VERSION ""

NS_ :

BS_:

BU_: TPMS iBooster_ADAS IM ESC_ADAS EPS1_ADAS CGW_ADAS VCU_ADAS FCM

BO_ 912 IM_02_Alarm_Event: 16 IM
 SG_ ALIVE_IM_02 : 23|8@0+ (1,0) [0|255] ""  VCU_ADAS,CGW_ADAS
 SG_ CRC_IM_02 : 7|16@0+ (1,0) [0|65535] ""  VCU_ADAS,CGW_ADAS
 SG_ IM_Driver_Fatigue_Event : 98|3@0+ (1,0) [0|7] ""  VCU_ADAS,CGW_ADAS
 SG_ IM_Driver_Distraction_Event : 111|3@0+ (1,0) [0|7] ""  VCU_ADAS,CGW_ADAS

BO_ 913 IM_03_Status: 20 IM
 SG_ ALIVE_IM_03 : 23|8@0+ (1,0) [0|255] ""  VCU_ADAS,CGW_ADAS
 SG_ CRC_IM_03 : 7|16@0+ (1,0) [0|65535] ""  VCU_ADAS,CGW_ADAS
 SG_ IM_Calibrate_Result : 103|1@0+ (1,0) [0|1] ""  VCU_ADAS,CGW_ADAS
 SG_ IM_Camera_Lens_Cover : 102|1@0+ (1,0) [0|1] ""  VCU_ADAS,CGW_ADAS
 SG_ IM_Driver_Eye_Invisible : 101|1@0+ (1,0) [0|1] ""  VCU_ADAS,CGW_ADAS
 SG_ IM_Driver_Face_Invisible : 111|11@0+ (1,0) [0|1] ""  VCU_ADAS,CGW_ADAS
 SG_ IM_Driver_Distraction : 122|3@0+ (1,0) [0|7] ""  VCU_ADAS,CGW_ADAS
 SG_ IM_Driver_Fatigue : 116|2@0+ (1,0) [0|3] ""  VCU_ADAS,CGW_ADAS
 SG_ IM_DMS_Status : 98|3@0+ (1,0) [0|7] ""  VCU_ADAS,CGW_ADAS

BO_ 1986 IDS_iBooster_Resp: 8 iBooster_ADAS
 SG_ IDS_iBooster_Resp : 7|64@0+ (1,0) [0|1.84467440737096E+019] ""  CGW_ADAS

BO_ 1982 IDS_ESC_Resp: 8 ESC_ADAS
 SG_ IDS_ESC_Resp : 7|64@0+ (1,0) [0|1.84467440737096E+019] ""  CGW_ADAS

BO_ 1973 IDS_FCM_Resp: 8 FCM
 SG_ IDS_FCM_Resp : 7|64@0+ (1,0) [0|1.84467440737096E+019] ""  CGW_ADAS

BO_ 1906 IDS_iBooster_Req: 8 CGW_ADAS
 SG_ IDS_iBooster_Req : 7|64@0+ (1,0) [0|1.84467440737096E+019] ""  iBooster_ADAS

BO_ 1902 IDS_ESC_Req: 8 CGW_ADAS
 SG_ IDS_ESC_Req : 7|64@0+ (1,0) [0|1.84467440737096E+019] ""  ESC_ADAS

BO_ 1893 IDS_FCM_Req: 8 CGW_ADAS
 SG_ IDS_FCM_Req : 7|64@0+ (1,0) [0|1.84467440737096E+019] ""  FCM

BO_ 801 HU_02: 16 CGW_ADAS
 SG_ HU_DigitSpeed : 111|9@0+ (1,0) [0|260] "km/h"  FCM,VCU_ADAS,EPS1_ADAS
 SG_ ALIVE_HU_02 : 23|8@0+ (1,0) [0|255] ""  FCM,VCU_ADAS,EPS1_ADAS
 SG_ CRC_HU_02 : 7|16@0+ (1,0) [0|65535] ""  FCM,VCU_ADAS,EPS1_ADAS
 SG_ HU_ST_TILT_Setting : 102|1@0+ (1,0) [0|1] ""  FCM,VCU_ADAS,EPS1_ADAS
 SG_ HU_ST_USIS_Setting : 103|1@0+ (1,0) [0|1] ""  FCM,VCU_ADAS,EPS1_ADAS

BO_ 1791 Diag_FuncReq_All_ECUs: 8 CGW_ADAS
 SG_ Diag_FuncReq_All_ECUs : 7|64@0+ (1,0) [0|1.84467440737096E+019] "N/A"  TPMS,IM,iBooster_ADAS,FCM,ESC_ADAS,EPS1_ADAS

BO_ 1775 Diag_FuncReq_All_CAN: 8 CGW_ADAS
 SG_ Diag_FuncReq_All_CAN : 7|64@0+ (1,0) [0|1.84467440737096E+019] "N/A"  TPMS,IM,iBooster_ADAS,FCM,ESC_ADAS,EPS1_ADAS

BO_ 789 TBOX_01_OTA: 16 CGW_ADAS
 SG_ TBOX_OTA_WakeupStatus : 99|2@0+ (1,0) [0|0] ""  VCU_ADAS,TPMS,IM,iBooster_ADAS,FCM,ESC_ADAS,EPS1_ADAS
 SG_ ALIVE_TBOX_01 : 23|8@0+ (1,0) [0|255] ""  VCU_ADAS,EPS1_ADAS,IM,FCM,ESC_ADAS,iBooster_ADAS,TPMS
 SG_ CRC_TBOX_01 : 7|16@0+ (1,0) [0|65535] ""  VCU_ADAS,EPS1_ADAS,IM,FCM,ESC_ADAS,iBooster_ADAS,TPMS
 SG_ TBOX_OTA_Status : 103|4@0+ (1,0) [0|15] ""  VCU_ADAS,EPS1_ADAS,IM,FCM,ESC_ADAS,iBooster_ADAS,TPMS

BO_ 901 VCU_13_VSMS: 32 VCU_ADAS
 SG_ VCU_TowModRq : 115|1@0+ (1,0) [0|1] ""  IM,FCM,ESC_ADAS
 SG_ VCU_TowModSts : 116|1@0+ (1,0) [0|1] ""  IM,FCM,ESC_ADAS
 SG_ VCU_Dur_Lt_h : 207|14@0+ (1,0) [0|16383] "h"  IM,FCM,ESC_ADAS
 SG_ VCU_Dur_Trip_h : 199|8@0+ (1,0) [0|255] "h"  IM,FCM,ESC_ADAS
 SG_ VCU_Dur_Act_h : 99|4@0+ (1,0) [0|15] "h"  IM,FCM,ESC_ADAS
 SG_ VCU_Dur_Lt_min : 191|6@0+ (1,0) [0|59] ""  IM,FCM,ESC_ADAS
 SG_ VCU_Dur_Trip_min : 183|6@0+ (1,0) [0|59] "min"  IM,FCM,ESC_ADAS
 SG_ VCU_Dur_Act_min : 175|6@0+ (1,0) [0|59] "min"  IM,FCM,ESC_ADAS
 SG_ VCU_AvgDrivRngRate : 159|14@0+ (0.1,0) [0|1000] "km/h"  IM,FCM,ESC_ADAS
 SG_ ALIVE_VCU_13 : 23|8@0+ (1,0) [0|255] ""  IM,FCM,ESC_ADAS
 SG_ CRC_VCU_13 : 7|16@0+ (1,0) [0|65535] ""  IM,FCM,ESC_ADAS
 SG_ VCU_ProdRollrModSts : 101|1@0+ (1,0) [0|1] ""  FCM,IM,ESC_ADAS
 SG_ VCU_DynoModSts : 102|1@0+ (1,0) [0|1] ""  IM,ESC_ADAS,FCM
 SG_ VCU_DynoModActvtnEnblSts : 103|1@0+ (1,0) [0|1] ""  IM,ESC_ADAS,FCM
 SG_ VCU_AvgSpd_Lt : 143|11@0+ (0.1,0) [0|160] "km/h"  IM,FCM,ESC_ADAS
 SG_ VCU_AvgSpd_Trip : 127|11@0+ (0.1,0) [0|160] "km/h"  IM,FCM,ESC_ADAS
 SG_ VCU_AvgSpd_Act : 111|11@0+ (0.1,0) [0|160] "km/h"  IM,FCM,ESC_ADAS

BO_ 1296 NM_EPS: 8 EPS1_ADAS
 SG_ usrData1_EPS_Bit7_ECUSPEC_AWAKE : 31|1@0+ (1,0) [0|1] ""  FCM,IM,VCU_ADAS,ESC_ADAS,iBooster_ADAS,TPMS,CGW_ADAS
 SG_ usrData1_EPS_Bit6_DIAGN_AWAKE : 30|1@0+ (1,0) [0|1] ""  FCM,IM,VCU_ADAS,ESC_ADAS,iBooster_ADAS,TPMS,CGW_ADAS
 SG_ usrData1_EPS_Bit5_IGNITION_AWAKE : 29|1@0+ (1,0) [0|1] ""  FCM,IM,VCU_ADAS,ESC_ADAS,iBooster_ADAS,TPMS,CGW_ADAS
 SG_ usrData1_EPS_Bit4_NETWORK_AWAKE : 28|1@0+ (1,0) [0|1] ""  FCM,IM,VCU_ADAS,ESC_ADAS,iBooster_ADAS,TPMS,CGW_ADAS
 SG_ usrData1_EPS_Bit3_ECUSPEC_WAKEUP : 27|1@0+ (1,0) [0|1] ""  FCM,IM,VCU_ADAS,ESC_ADAS,iBooster_ADAS,TPMS,CGW_ADAS
 SG_ usrData1_EPS_Bit2_NETWORK_WAKEUP : 26|1@0+ (1,0) [0|1] ""  FCM,IM,VCU_ADAS,ESC_ADAS,iBooster_ADAS,TPMS,CGW_ADAS
 SG_ usrData1_EPS_Bit1_RESET_WAKEUP : 25|1@0+ (1,0) [0|1] ""  FCM,IM,VCU_ADAS,ESC_ADAS,iBooster_ADAS,TPMS,CGW_ADAS
 SG_ CtrlBitVector_EPS_Bit7_Res : 15|1@0+ (1,0) [0|1] ""  FCM,IM,VCU_ADAS,ESC_ADAS,iBooster_ADAS,TPMS,CGW_ADAS
 SG_ CtrlBitVector_EPS_Bit6_PNI : 14|1@0+ (1,0) [0|1] ""  FCM,IM,VCU_ADAS,ESC_ADAS,iBooster_ADAS,TPMS,CGW_ADAS
 SG_ CtrlBitVector_EPS_Bit5_Res : 13|1@0+ (1,0) [0|1] ""  FCM,IM,VCU_ADAS,ESC_ADAS,iBooster_ADAS,TPMS,CGW_ADAS
 SG_ CtrlBitVector_EPS_Bit4_ActWake : 12|1@0+ (1,0) [0|1] ""  FCM,IM,VCU_ADAS,ESC_ADAS,iBooster_ADAS,TPMS,CGW_ADAS
 SG_ CtrlBitVector_EPS_Bit3_NMCoord : 11|1@0+ (1,0) [0|1] ""  FCM,IM,VCU_ADAS,ESC_ADAS,iBooster_ADAS,TPMS,CGW_ADAS
 SG_ CtrlBitVector_EPS_Bit2_Res : 10|1@0+ (1,0) [0|1] ""  FCM,IM,VCU_ADAS,ESC_ADAS,iBooster_ADAS,TPMS,CGW_ADAS
 SG_ CtrlBitVector_EPS_Bit1_Res : 9|1@0+ (1,0) [0|1] ""  FCM,IM,VCU_ADAS,ESC_ADAS,iBooster_ADAS,TPMS,CGW_ADAS
 SG_ usrData1_EPS_Bit0_IGN_WAKEUP : 24|1@0+ (1,0) [0|1] ""  FCM,IM,VCU_ADAS,ESC_ADAS,iBooster_ADAS,TPMS,CGW_ADAS
 SG_ usrData0_EPS : 23|8@0+ (1,0) [0|255] ""  FCM,IM,VCU_ADAS,ESC_ADAS,iBooster_ADAS,TPMS,CGW_ADAS
 SG_ srcNodeID_EPS : 7|8@0+ (1,0) [0|127] ""  FCM,IM,VCU_ADAS,ESC_ADAS,iBooster_ADAS,TPMS,CGW_ADAS
 SG_ CtrlBitVector_EPS_Bit0_RMR : 8|1@0+ (1,0) [0|1] ""  FCM,IM,VCU_ADAS,ESC_ADAS,iBooster_ADAS,TPMS,CGW_ADAS
 SG_ usrData2_EPS : 39|8@0+ (1,0) [0|255] ""  FCM,IM,VCU_ADAS,ESC_ADAS,iBooster_ADAS,TPMS,CGW_ADAS
 SG_ usrData4_EPS_PN_Info1 : 55|8@0+ (1,0) [0|255] ""  FCM,IM,VCU_ADAS,ESC_ADAS,iBooster_ADAS,TPMS,CGW_ADAS
 SG_ usrData5_EPS_PN_Info2 : 63|8@0+ (1,0) [0|255] ""  FCM,IM,VCU_ADAS,ESC_ADAS,iBooster_ADAS,TPMS,CGW_ADAS
 SG_ usrData3_EPS : 47|8@0+ (1,0) [0|255] ""  FCM,IM,VCU_ADAS,ESC_ADAS,iBooster_ADAS,TPMS,CGW_ADAS

BO_ 1295 NM_ESC: 8 ESC_ADAS
 SG_ usrData1_ESC_Bit7_ECUSPEC_AWAKE : 31|1@0+ (1,0) [0|1] ""  CGW_ADAS,VCU_ADAS,EPS1_ADAS,FCM,IM,iBooster_ADAS,TPMS
 SG_ usrData1_ESC_Bit6_DIAGN_AWAKE : 30|1@0+ (1,0) [0|1] ""  CGW_ADAS,VCU_ADAS,EPS1_ADAS,FCM,IM,iBooster_ADAS,TPMS
 SG_ usrData1_ESC_Bit5_IGNITION_AWAKE : 29|1@0+ (1,0) [0|1] ""  CGW_ADAS,VCU_ADAS,EPS1_ADAS,FCM,IM,iBooster_ADAS,TPMS
 SG_ usrData1_ESC_Bit4_NETWORK_AWAKE : 28|1@0+ (1,0) [0|1] ""  CGW_ADAS,VCU_ADAS,EPS1_ADAS,FCM,IM,iBooster_ADAS,TPMS
 SG_ usrData1_ESC_Bit3_ECUSPEC_WAKEUP : 27|1@0+ (1,0) [0|1] ""  CGW_ADAS,VCU_ADAS,EPS1_ADAS,FCM,IM,iBooster_ADAS,TPMS
 SG_ usrData1_ESC_Bit2_NETWORK_WAKEUP : 26|1@0+ (1,0) [0|1] ""  CGW_ADAS,VCU_ADAS,EPS1_ADAS,FCM,IM,iBooster_ADAS,TPMS
 SG_ usrData1_ESC_Bit1_RESET_WAKEUP : 25|1@0+ (1,0) [0|1] ""  CGW_ADAS,VCU_ADAS,EPS1_ADAS,FCM,IM,iBooster_ADAS,TPMS
 SG_ CtrlBitVector_ESC_Bit7_Res : 15|1@0+ (1,0) [0|1] ""  CGW_ADAS,VCU_ADAS,EPS1_ADAS,FCM,IM,iBooster_ADAS,TPMS
 SG_ CtrlBitVector_ESC_Bit6_PNI : 14|1@0+ (1,0) [0|1] ""  CGW_ADAS,VCU_ADAS,EPS1_ADAS,FCM,IM,iBooster_ADAS,TPMS
 SG_ CtrlBitVector_ESC_Bit5_Res : 13|1@0+ (1,0) [0|1] ""  CGW_ADAS,VCU_ADAS,EPS1_ADAS,FCM,IM,iBooster_ADAS,TPMS
 SG_ CtrlBitVector_ESC_Bit4_ActWake : 12|1@0+ (1,0) [0|1] ""  CGW_ADAS,VCU_ADAS,EPS1_ADAS,FCM,IM,iBooster_ADAS,TPMS
 SG_ CtrlBitVector_ESC_Bit3_NMCoord : 11|1@0+ (1,0) [0|1] ""  CGW_ADAS,VCU_ADAS,EPS1_ADAS,FCM,IM,iBooster_ADAS,TPMS
 SG_ CtrlBitVector_ESC_Bit2_Res : 10|1@0+ (1,0) [0|1] ""  CGW_ADAS,VCU_ADAS,EPS1_ADAS,FCM,IM,iBooster_ADAS,TPMS
 SG_ CtrlBitVector_ESC_Bit1_Res : 9|1@0+ (1,0) [0|1] ""  CGW_ADAS,VCU_ADAS,EPS1_ADAS,FCM,IM,iBooster_ADAS,TPMS
 SG_ usrData1_ESC_Bit0_IGN_WAKEUP : 24|1@0+ (1,0) [0|1] ""  CGW_ADAS,VCU_ADAS,EPS1_ADAS,FCM,IM,iBooster_ADAS,TPMS
 SG_ usrData0_ESC : 23|8@0+ (1,0) [0|255] ""  CGW_ADAS,VCU_ADAS,EPS1_ADAS,FCM,IM,iBooster_ADAS,TPMS
 SG_ srcNodeID_ESC : 7|8@0+ (1,0) [0|127] ""  CGW_ADAS,VCU_ADAS,EPS1_ADAS,FCM,IM,iBooster_ADAS,TPMS
 SG_ CtrlBitVector_ESC_Bit0_RMR : 8|1@0+ (1,0) [0|1] ""  CGW_ADAS,VCU_ADAS,EPS1_ADAS,FCM,IM,iBooster_ADAS,TPMS
 SG_ usrData2_ESC : 39|8@0+ (1,0) [0|255] ""  CGW_ADAS,VCU_ADAS,EPS1_ADAS,FCM,IM,iBooster_ADAS,TPMS
 SG_ usrData4_ESC_PN_Info1 : 55|8@0+ (1,0) [0|255] ""  CGW_ADAS,VCU_ADAS,EPS1_ADAS,FCM,IM,iBooster_ADAS,TPMS
 SG_ usrData5_ESC_PN_Info2 : 63|8@0+ (1,0) [0|255] ""  CGW_ADAS,VCU_ADAS,EPS1_ADAS,FCM,IM,iBooster_ADAS,TPMS
 SG_ usrData3_ESC : 47|8@0+ (1,0) [0|255] ""  CGW_ADAS,VCU_ADAS,EPS1_ADAS,FCM,IM,iBooster_ADAS,TPMS

BO_ 1281 NM_CGW: 8 CGW_ADAS
 SG_ usrData1_CGW_Bit7_ECUSPEC_AWAKE : 31|1@0+ (1,0) [0|1] ""  ESC_ADAS,EPS1_ADAS,iBooster_ADAS
 SG_ usrData1_CGW_Bit6_DIAGN_AWAKE : 30|1@0+ (1,0) [0|1] ""  ESC_ADAS,EPS1_ADAS,iBooster_ADAS
 SG_ usrData1_CGW_Bit5_IGNITION_AWAKE : 29|1@0+ (1,0) [0|1] ""  ESC_ADAS,EPS1_ADAS,iBooster_ADAS
 SG_ usrData1_CGW_Bit4_NETWORK_AWAKE : 28|1@0+ (1,0) [0|1] ""  ESC_ADAS,EPS1_ADAS,iBooster_ADAS
 SG_ usrData1_CGW_Bit3_ECUSPEC_WAKEUP : 27|1@0+ (1,0) [0|1] ""  ESC_ADAS,EPS1_ADAS,iBooster_ADAS
 SG_ usrData1_CGW_Bit2_NETWORK_WAKEUP : 26|1@0+ (1,0) [0|1] ""  ESC_ADAS,EPS1_ADAS,iBooster_ADAS
 SG_ usrData1_CGW_Bit1_RESET_WAKEUP : 25|1@0+ (1,0) [0|1] ""  ESC_ADAS,EPS1_ADAS,iBooster_ADAS
 SG_ CtrlBitVector_CGW_Bit7_Res : 15|1@0+ (1,0) [0|1] ""  ESC_ADAS,EPS1_ADAS,iBooster_ADAS
 SG_ CtrlBitVector_CGW_Bit6_PNI : 14|1@0+ (1,0) [0|1] ""  ESC_ADAS,EPS1_ADAS,iBooster_ADAS
 SG_ CtrlBitVector_CGW_Bit5_Res : 13|1@0+ (1,0) [0|1] ""  ESC_ADAS,EPS1_ADAS,iBooster_ADAS
 SG_ CtrlBitVector_CGW_Bit4_ActWake : 12|1@0+ (1,0) [0|1] ""  ESC_ADAS,EPS1_ADAS,iBooster_ADAS
 SG_ CtrlBitVector_CGW_Bit3_NMCoord : 11|1@0+ (1,0) [0|1] ""  ESC_ADAS,EPS1_ADAS,iBooster_ADAS
 SG_ CtrlBitVector_CGW_Bit2_Res : 10|1@0+ (1,0) [0|1] ""  ESC_ADAS,EPS1_ADAS,iBooster_ADAS
 SG_ CtrlBitVector_CGW_Bit1_Res : 9|1@0+ (1,0) [0|1] ""  ESC_ADAS,EPS1_ADAS,iBooster_ADAS
 SG_ usrData1_CGW_Bit0_IGN_WAKEUP : 24|1@0+ (1,0) [0|1] ""  ESC_ADAS,EPS1_ADAS,iBooster_ADAS
 SG_ usrData0_CGW : 23|8@0+ (1,0) [0|255] ""  ESC_ADAS,EPS1_ADAS,iBooster_ADAS
 SG_ srcNodeID_CGW : 7|8@0+ (1,0) [0|127] ""  ESC_ADAS,EPS1_ADAS,iBooster_ADAS
 SG_ CtrlBitVector_CGW_Bit0_RMR : 8|1@0+ (1,0) [0|1] ""  ESC_ADAS,EPS1_ADAS,iBooster_ADAS
 SG_ usrData2_CGW : 39|8@0+ (1,0) [0|255] ""  ESC_ADAS,EPS1_ADAS,iBooster_ADAS
 SG_ usrData4_CGW_PN_Info1 : 55|8@0+ (1,0) [0|255] ""  ESC_ADAS,EPS1_ADAS,iBooster_ADAS
 SG_ usrData5_CGW_PN_Info2 : 63|8@0+ (1,0) [0|255] ""  ESC_ADAS,EPS1_ADAS,iBooster_ADAS
 SG_ usrData3_CGW : 47|8@0+ (1,0) [0|255] ""  ESC_ADAS,EPS1_ADAS,iBooster_ADAS

BO_ 1311 NM_iBooster: 8 iBooster_ADAS
 SG_ usrData1_iBo_Bit7_ECUSPEC_AWAKE : 31|1@0+ (1,0) [0|1] ""  EPS1_ADAS,FCM,IM,ESC_ADAS,TPMS,VCU_ADAS,CGW_ADAS
 SG_ usrData1_iBo_Bit6_DIAGN_AWAKE : 30|1@0+ (1,0) [0|1] ""  EPS1_ADAS,FCM,IM,ESC_ADAS,TPMS,VCU_ADAS,CGW_ADAS
 SG_ usrData1_iBo_Bit5_IGNITION_AWAKE : 29|1@0+ (1,0) [0|1] ""  EPS1_ADAS,FCM,IM,ESC_ADAS,TPMS,VCU_ADAS,CGW_ADAS
 SG_ usrData1_iBo_Bit4_NETWORK_AWAKE : 28|1@0+ (1,0) [0|1] ""  EPS1_ADAS,FCM,IM,ESC_ADAS,TPMS,VCU_ADAS,CGW_ADAS
 SG_ usrData1_iBo_Bit3_ECUSPEC_WAKEUP : 27|1@0+ (1,0) [0|1] ""  EPS1_ADAS,FCM,IM,ESC_ADAS,TPMS,VCU_ADAS,CGW_ADAS
 SG_ usrData1_iBo_Bit2_NETWORK_WAKEUP : 26|1@0+ (1,0) [0|1] ""  EPS1_ADAS,FCM,IM,ESC_ADAS,TPMS,VCU_ADAS,CGW_ADAS
 SG_ usrData1_iBo_Bit1_RESET_WAKEUP : 25|1@0+ (1,0) [0|1] ""  EPS1_ADAS,FCM,IM,ESC_ADAS,TPMS,VCU_ADAS,CGW_ADAS
 SG_ CtrlBitVector_iBo_Bit7_Res : 15|1@0+ (1,0) [0|1] ""  EPS1_ADAS,FCM,IM,ESC_ADAS,TPMS,VCU_ADAS,CGW_ADAS
 SG_ CtrlBitVector_iBo_Bit6_PNI : 14|1@0+ (1,0) [0|1] ""  EPS1_ADAS,FCM,IM,ESC_ADAS,TPMS,VCU_ADAS,CGW_ADAS
 SG_ CtrlBitVector_iBo_Bit5_Res : 13|1@0+ (1,0) [0|1] ""  EPS1_ADAS,FCM,IM,ESC_ADAS,TPMS,VCU_ADAS,CGW_ADAS
 SG_ CtrlBitVector_iBo_Bit4_ActWake : 12|1@0+ (1,0) [0|1] ""  EPS1_ADAS,FCM,IM,ESC_ADAS,TPMS,VCU_ADAS,CGW_ADAS
 SG_ CtrlBitVector_iBo_Bit3_NMCoord : 11|1@0+ (1,0) [0|1] ""  EPS1_ADAS,FCM,IM,ESC_ADAS,TPMS,VCU_ADAS,CGW_ADAS
 SG_ CtrlBitVector_iBo_Bit2_Res : 10|1@0+ (1,0) [0|1] ""  EPS1_ADAS,FCM,IM,ESC_ADAS,TPMS,VCU_ADAS,CGW_ADAS
 SG_ CtrlBitVector_iBo_Bit1_Res : 9|1@0+ (1,0) [0|1] ""  EPS1_ADAS,FCM,IM,ESC_ADAS,TPMS,VCU_ADAS,CGW_ADAS
 SG_ usrData1_iBo_Bit0_IGN_WAKEUP : 24|1@0+ (1,0) [0|1] ""  EPS1_ADAS,FCM,IM,ESC_ADAS,TPMS,VCU_ADAS,CGW_ADAS
 SG_ usrData0_iBo : 23|8@0+ (1,0) [0|255] ""  EPS1_ADAS,FCM,IM,ESC_ADAS,TPMS,VCU_ADAS,CGW_ADAS
 SG_ srcNodeID_iBo : 7|8@0+ (1,0) [0|127] ""  EPS1_ADAS,FCM,IM,ESC_ADAS,TPMS,VCU_ADAS,CGW_ADAS
 SG_ CtrlBitVector_iBo_Bit0_RMR : 8|1@0+ (1,0) [0|1] ""  EPS1_ADAS,FCM,IM,ESC_ADAS,TPMS,VCU_ADAS,CGW_ADAS
 SG_ usrData2_iBo : 39|8@0+ (1,0) [0|255] ""  EPS1_ADAS,FCM,IM,ESC_ADAS,TPMS,VCU_ADAS,CGW_ADAS
 SG_ usrData4_iBo_PN_Info1 : 55|8@0+ (1,0) [0|255] ""  EPS1_ADAS,FCM,IM,ESC_ADAS,TPMS,VCU_ADAS,CGW_ADAS
 SG_ usrData5_iBo_PN_Info2 : 63|8@0+ (1,0) [0|255] ""  EPS1_ADAS,FCM,IM,ESC_ADAS,TPMS,VCU_ADAS,CGW_ADAS
 SG_ usrData3_iBo : 47|8@0+ (1,0) [0|255] ""  EPS1_ADAS,FCM,IM,ESC_ADAS,TPMS,VCU_ADAS,CGW_ADAS

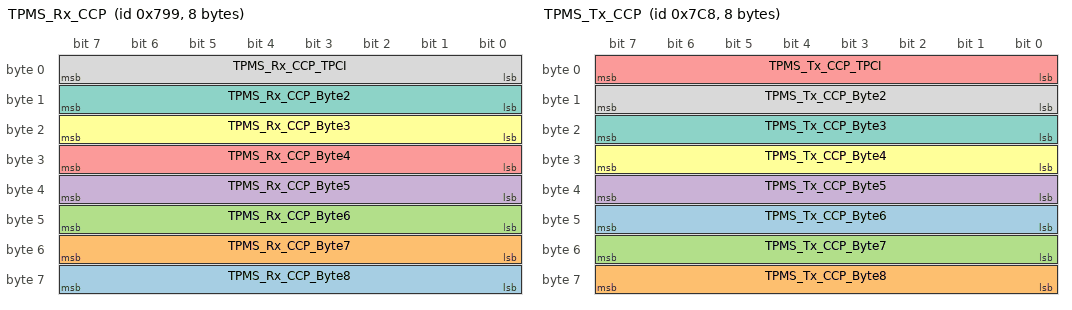
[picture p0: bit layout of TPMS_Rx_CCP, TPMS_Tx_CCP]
BO_ 1945 TPMS_Rx_CCP: 8 CGW_ADAS
 SG_ TPMS_Rx_CCP_Byte8 : 63|8@0+ (1,0) [0|255] ""  TPMS
 SG_ TPMS_Rx_CCP_Byte7 : 55|8@0+ (1,0) [0|255] ""  TPMS
 SG_ TPMS_Rx_CCP_Byte6 : 47|8@0+ (1,0) [0|255] ""  TPMS
 SG_ TPMS_Rx_CCP_Byte5 : 39|8@0+ (1,0) [0|255] ""  TPMS
 SG_ TPMS_Rx_CCP_Byte4 : 31|8@0+ (1,0) [0|255] ""  TPMS
 SG_ TPMS_Rx_CCP_Byte3 : 23|8@0+ (1,0) [0|255] ""  TPMS
 SG_ TPMS_Rx_CCP_Byte2 : 15|8@0+ (1,0) [0|255] ""  TPMS
 SG_ TPMS_Rx_CCP_TPCI : 7|8@0+ (1,0) [0|255] ""  TPMS

BO_ 1992 TPMS_Tx_CCP: 8 TPMS
 SG_ TPMS_Tx_CCP_Byte6 : 47|8@0+ (1,0) [0|255] ""  CGW_ADAS
 SG_ TPMS_Tx_CCP_Byte8 : 63|8@0+ (1,0) [0|255] ""  CGW_ADAS
 SG_ TPMS_Tx_CCP_Byte7 : 55|8@0+ (1,0) [0|255] ""  CGW_ADAS
 SG_ TPMS_Tx_CCP_Byte5 : 39|8@0+ (1,0) [0|255] ""  CGW_ADAS
 SG_ TPMS_Tx_CCP_TPCI : 7|8@0+ (1,0) [0|255] ""  CGW_ADAS
 SG_ TPMS_Tx_CCP_Byte4 : 31|8@0+ (1,0) [0|255] ""  CGW_ADAS
 SG_ TPMS_Tx_CCP_Byte3 : 23|8@0+ (1,0) [0|255] ""  CGW_ADAS
 SG_ TPMS_Tx_CCP_Byte2 : 15|8@0+ (1,0) [0|255] ""  CGW_ADAS

BO_ 528 TPMS_01: 32 TPMS
 SG_ TPM_MalfLmp_On_Rq : 211|1@0+ (1,0) [0|1] ""  FCM,CGW_ADAS
 SG_ TPM_IndLmp_On_Rq : 212|1@0+ (1,0) [0|1] ""  FCM,CGW_ADAS
 SG_ TPM_WarnDisp_Rq : 215|3@0+ (1,0) [0|7] ""  FCM,CGW_ADAS
 SG_ TPM_Stat : 202|3@0+ (1,0) [0|7] ""  FCM,CGW_ADAS
 SG_ TPM_MsgDisp_Rq : 206|4@0+ (1,0) [0|15] ""  FCM,CGW_ADAS
 SG_ Press_Disp_Avl : 207|1@0+ (1,0) [0|1] ""  FCM,CGW_ADAS
 SG_ TireStat_FR : 197|2@0+ (1,0) [0|3] ""  FCM,CGW_ADAS
 SG_ TireStat_RL : 195|2@0+ (1,0) [0|3] ""  FCM,CGW_ADAS
 SG_ TireStat_RR : 193|2@0+ (1,0) [0|3] ""  FCM,CGW_ADAS
 SG_ TireStat_FL : 199|2@0+ (1,0) [0|3] ""  FCM,CGW_ADAS
 SG_ TirePress_RR : 191|8@0+ (2.5,0) [0|632.5] "kPa"  FCM,CGW_ADAS
 SG_ TirePress_RL : 183|8@0+ (2.5,0) [0|632.5] "kPa"  FCM,CGW_ADAS
 SG_ TirePress_FR : 175|8@0+ (2.5,0) [0|632.5] "kPa"  FCM,CGW_ADAS
 SG_ TirePress_FL : 167|8@0+ (2.5,0) [0|632.5] "kPa"  FCM,CGW_ADAS
 SG_ Tire_Temp_WarnDisp_Rq : 159|3@0+ (1,0) [0|7] ""  CGW_ADAS,FCM
 SG_ Tire_Temp_Stat_RR : 145|2@0+ (1,0) [0|3] ""  CGW_ADAS,FCM
 SG_ Tire_Temp_Stat_RL : 147|2@0+ (1,0) [0|3] ""  CGW_ADAS,FCM
 SG_ Tire_Temp_Stat_FR : 149|2@0+ (1,0) [0|3] ""  CGW_ADAS,FCM
 SG_ Tire_Temp_Stat_FL : 151|2@0+ (1,0) [0|3] ""  CGW_ADAS,FCM
 SG_ RefPress_Rear : 143|8@0+ (2.5,0) [0|632.5] "kPa"  CGW_ADAS,FCM
 SG_ RefPress_Front : 135|8@0+ (2.5,0) [0|632.5] "kPa"  CGW_ADAS,FCM
 SG_ TireTemp_RR : 127|8@0+ (1,-50) [-50|204] "degC"  CGW_ADAS,FCM
 SG_ TireTemp_RL : 119|8@0+ (1,-50) [-50|204] "degC"  CGW_ADAS,FCM
 SG_ TireTemp_FR : 111|8@0+ (1,-50) [-50|204] "degC"  FCM,CGW_ADAS
 SG_ TireTemp_FL : 103|8@0+ (1,-50) [-50|204] "degC"  FCM,CGW_ADAS
 SG_ ALIVE_TPMS_01 : 23|8@0+ (1,0) [0|255] ""  FCM,CGW_ADAS
 SG_ CRC_TPMS_01 : 7|16@0+ (1,0) [0|65535] ""  FCM,CGW_ADAS

BO_ 640 HU_08_Unit: 16 CGW_ADAS
 SG_ ALIVE_HU_08 : 23|8@0+ (1,0) [0|255] ""  VCU_ADAS,FCM
 SG_ CRC_HU_08 : 7|16@0+ (1,0) [0|65535] ""  VCU_ADAS,FCM
 SG_ DateFormat : 99|2@0+ (1,0) [0|3] ""  VCU_ADAS,FCM
 SG_ SpeedUnit : 101|2@0+ (1,0) [0|3] ""  VCU_ADAS,FCM
 SG_ DistanceUnit : 109|2@0+ (1,0) [0|3] ""  VCU_ADAS,FCM
 SG_ TempUnit : 97|2@0+ (1,0) [0|3] ""  VCU_ADAS,FCM
 SG_ FuelConsumption : 127|8@0+ (1,0) [0|255] ""  VCU_ADAS,FCM
 SG_ Language : 119|8@0+ (1,0) [0|0] ""  VCU_ADAS,FCM
 SG_ FuelUnit : 111|2@0+ (1,0) [0|3] ""  VCU_ADAS,FCM
 SG_ TimeFormat : 103|2@0+ (1,0) [0|0] ""  VCU_ADAS,FCM

BO_ 128 VCU_07_Tqs_ESC: 32 VCU_ADAS
 SG_ VCU_AccPedalPos_Q : 247|2@0+ (1,0) [0|3] ""  CGW_ADAS,ESC_ADAS
 SG_ VCU_RECUPot_WhlTq_Q : 201|2@0+ (1,0) [0|3] ""  CGW_ADAS,ESC_ADAS
 SG_ VCU_RECUPot_WhlTq_RA_Q : 193|2@0+ (1,0) [0|3] ""  CGW_ADAS,ESC_ADAS
 SG_ VCU_RECUPot_WhlTq_FA_Q : 195|2@0+ (1,0) [0|3] ""  CGW_ADAS,ESC_ADAS
 SG_ VCU_Target_WhlTq_Q : 203|2@0+ (1,0) [0|3] ""  CGW_ADAS,ESC_ADAS
 SG_ VCU_Target_WhlTq_FA_Q : 205|2@0+ (1,0) [0|3] ""  CGW_ADAS,ESC_ADAS
 SG_ VCU_Target_WhlTq_RA_Q : 207|2@0+ (1,0) [0|3] ""  CGW_ADAS,ESC_ADAS
 SG_ ALIVE_VCU_07 : 23|8@0+ (1,0) [0|255] ""  CGW_ADAS,ESC_ADAS
 SG_ CRC_VCU_07 : 7|16@0+ (1,0) [0|65535] ""  CGW_ADAS,ESC_ADAS
 SG_ VCU_coordWhlTq_Q : 199|4@0+ (1,0) [0|15] ""  CGW_ADAS,ESC_ADAS
 SG_ VCU_AccPedalPos_Virt : 175|8@0+ (1,0) [0|100] "%"  CGW_ADAS,ESC_ADAS
 SG_ VCU_AccPedalPos : 167|8@0+ (1,0) [0|100] "%"  CGW_ADAS,ESC_ADAS
 SG_ VCU_coordWhlTq : 183|16@0- (1,0) [-32768|32767] "Nm"  CGW_ADAS,ESC_ADAS
 SG_ VCU_RECUPot_WhlTq : 151|16@0- (1,0) [-32768|32767] "Nm"  CGW_ADAS,ESC_ADAS
 SG_ VCU_RECUPot_WhlTq_RA : 135|16@0- (1,0) [-32768|32767] ""  CGW_ADAS,ESC_ADAS
 SG_ VCU_RECUPot_WhlTq_FA : 119|16@0- (1,0) [-32768|32767] ""  CGW_ADAS,ESC_ADAS
 SG_ VCU_Target_WhlTq : 103|16@0- (1,0) [-32768|32767] ""  CGW_ADAS,ESC_ADAS
 SG_ VCU_Target_WhlTq_FA : 215|16@0- (1,0) [-32768|32767] ""  CGW_ADAS,ESC_ADAS
 SG_ VCU_Target_WhlTq_RA : 231|16@0- (1,0) [-32768|32767] ""  CGW_ADAS,ESC_ADAS

BO_ 832 TCC_02: 48 VCU_ADAS
 SG_ TCC_ByPassFlap_error : 298|2@0+ (1,0) [0|3] ""  CGW_ADAS,FCM,TPMS
 SG_ TCC_RecircFlap_error : 309|2@0+ (1,0) [0|3] ""  CGW_ADAS,FCM,TPMS
 SG_ TCC_ModeFlap_error : 311|2@0+ (1,0) [0|3] ""  CGW_ADAS,FCM,TPMS
 SG_ TCC_Blower_Error : 211|2@0+ (1,0) [0|3] ""  TPMS,FCM,CGW_ADAS
 SG_ TCC_HVAC_AirDistributionMode : 301|3@0+ (1,0) [0|7] ""  CGW_ADAS,FCM,TPMS
 SG_ TCC_HV_Compressor_Availability : 295|8@0+ (1,0) [0|255] ""  CGW_ADAS,TPMS,FCM
 SG_ TCC_HV_Compressor_error : 237|2@0+ (1,0) [0|3] ""  CGW_ADAS,TPMS,FCM
 SG_ TCC_HV_Compressor_power : 271|8@0+ (100,0) [0|25500] "W"  CGW_ADAS,TPMS,FCM
 SG_ TCC_HV_PTC_HVAC_Availability : 279|8@0+ (1,0) [0|255] ""  CGW_ADAS,TPMS,FCM
 SG_ TCC_HV_PTC_HVAC_error : 239|2@0+ (1,0) [0|3] ""  CGW_ADAS,TPMS,FCM
 SG_ TCC_HV_PTC_HVAC_power : 255|9@0+ (100,0) [0|12800] "W"  CGW_ADAS,TPMS,FCM
 SG_ TCC_AGM_error : 225|2@0+ (1,0) [0|3] ""  CGW_ADAS,TPMS,FCM
 SG_ TCC_EFAN_error : 227|2@0+ (1,0) [0|3] ""  CGW_ADAS,TPMS,FCM
 SG_ TCC_HV_PTC_Battery_Availability : 287|8@0+ (1,0) [0|255] ""  CGW_ADAS,TPMS,FCM
 SG_ TCC_HV_PTC_Battery_error : 229|2@0+ (1,0) [0|3] ""  CGW_ADAS,TPMS,FCM
 SG_ TCC_HV_PTC_Battery_power : 262|7@0+ (100,0) [0|7000] "W"  CGW_ADAS,TPMS,FCM
 SG_ TCC_WAPU_EDU_Error : 231|2@0+ (1,0) [0|3] ""  CGW_ADAS,TPMS,FCM
 SG_ TCC_RSV_EDU_Error : 217|2@0+ (1,0) [0|3] ""  CGW_ADAS,TPMS,FCM
 SG_ TCC_CoolantTempEDURear_IN_error : 219|2@0+ (1,0) [0|3] ""  CGW_ADAS,TPMS,FCM
 SG_ TCC_CoolantTempEDUFront_IN_error : 221|2@0+ (1,0) [0|3] ""  CGW_ADAS,TPMS,FCM
 SG_ TCC_EDU_Cooling_error : 223|2@0+ (1,0) [0|3] ""  CGW_ADAS,TPMS,FCM
 SG_ TCC_CoolantTempIPU_IN : 247|8@0+ (1,-40) [-40|125] "°C"  CGW_ADAS,TPMS,FCM
 SG_ TCC_STAT_Defrost : 213|2@0+ (1,0) [0|3] ""  CGW_ADAS,TPMS,FCM
 SG_ TCC_STAT_Sync : 215|2@0+ (1,0) [0|3] ""  CGW_ADAS,TPMS,FCM
 SG_ TCC_STAT_Recirc : 201|2@0+ (1,0) [0|3] ""  CGW_ADAS,TPMS,FCM
 SG_ TCC_STAT_AC : 205|2@0+ (1,0) [0|3] ""  CGW_ADAS,TPMS,FCM
 SG_ TCC_STAT_AUTO : 207|2@0+ (1,0) [0|3] ""  CGW_ADAS,TPMS,FCM
 SG_ TCC_BlowerLevelManual : 199|3@0+ (1,0) [0|7] ""  CGW_ADAS,TPMS,FCM
 SG_ TCC_RightZoneSetTemp : 191|5@0+ (0.5,16) [16|27] "°C"  CGW_ADAS,TPMS,FCM
 SG_ TCC_LeftZoneSetTemp : 183|5@0+ (0.5,16) [16|27] "°C"  CGW_ADAS,TPMS,FCM
 SG_ TCC_CoolantTempIPU_IN_error : 331|2@0+ (1,0) [0|3] ""  TPMS,FCM,CGW_ADAS
 SG_ TCC_CabinTemp_Q : 333|2@0+ (1,0) [0|3] ""  TPMS,FCM,CGW_ADAS
 SG_ TCC_CabinTemp : 175|8@0+ (0.5,-40) [-40|85] "°C"  CGW_ADAS,FCM,TPMS
 SG_ TCC_AmbientTemp : 167|8@0+ (0.5,-40) [-40|87.5] "°C"  CGW_ADAS,FCM,TPMS
 SG_ TCC_AmbientTempRaw : 159|8@0+ (1,-40) [-40|210] "°C"  TPMS,CGW_ADAS,FCM
 SG_ CRC_TCC_02 : 7|16@0+ (1,0) [0|65535] ""  CGW_ADAS,FCM,TPMS
 SG_ ALIVE_TCC_02 : 23|8@0+ (1,0) [0|255] ""  CGW_ADAS,FCM,TPMS
 SG_ TCC_BlowerLevel : 135|7@0+ (1,0) [0|100] "%"  FCM,CGW_ADAS,TPMS
 SG_ TCC_RSV_EDU_Position : 151|7@0+ (1,0) [0|100] "%"  TPMS,CGW_ADAS,FCM
 SG_ TCC_CoolantFlow_EDURear : 127|8@0+ (0.5,0) [0|127.5] "l/min"  TPMS,CGW_ADAS,FCM
 SG_ TCC_CoolantFlow_EDUFront : 119|8@0+ (0.5,0) [0|127.5] "l/min"  TPMS,CGW_ADAS,FCM
 SG_ TCC_WAPU_EDU : 143|7@0+ (1,0) [0|100] "%"  TPMS,CGW_ADAS,FCM
 SG_ TCC_CoolantTempEDURear_IN : 111|8@0+ (1,-40) [-40|125] "°C"  TPMS,CGW_ADAS,FCM
 SG_ TCC_CoolantTempEDUFront_IN : 103|8@0+ (1,-40) [-40|125] "°C"  TPMS,CGW_ADAS,FCM
 SG_ TCC_AmbientTemp_Q : 335|2@0+ (1,0) [0|3] ""  TPMS,FCM,CGW_ADAS
 SG_ TCC_STAT_MaxAC : 203|2@0+ (1,0) [0|3] ""  CGW_ADAS,TPMS,FCM

BO_ 409 ESC_02_AccelYRS: 32 ESC_ADAS
 SG_ ESC_VehLatInc_Q : 199|4@0+ (1,0) [0|15] ""  VCU_ADAS,FCM,EPS1_ADAS,CGW_ADAS
 SG_ ESC_VehLatInc : 183|16@0+ (0.002,-65) [-65|65] "m/s²"  VCU_ADAS,FCM,EPS1_ADAS,CGW_ADAS
 SG_ SSecOC_MAC_ESC_02 : 39|64@0+ (1,0) [0|1.84467440737096E+019] ""  VCU_ADAS,FCM,EPS1_ADAS,CGW_ADAS
 SG_ SSecOC_Fresh_ESC_02 : 31|8@0+ (1,0) [0|255] ""  VCU_ADAS,FCM,EPS1_ADAS,CGW_ADAS
 SG_ ESC_VehLgtInc_Q : 159|4@0+ (1,0) [0|15] ""  VCU_ADAS,EPS1_ADAS,CGW_ADAS,FCM
 SG_ ESC_VehLgtInc : 143|16@0+ (0.002,-65) [-65|65] "m/s²"  VCU_ADAS,EPS1_ADAS,CGW_ADAS,FCM
 SG_ ESC_LatAcc_Q : 135|4@0+ (1,0) [0|15] ""  VCU_ADAS,EPS1_ADAS,CGW_ADAS,FCM
 SG_ ESC_LatAcc : 103|16@0+ (0.002,-65) [-65|65] "m/s²"  VCU_ADAS,EPS1_ADAS,CGW_ADAS,FCM
 SG_ ESC_LgtAcc_Q : 131|4@0+ (1,0) [0|15] ""  VCU_ADAS,EPS1_ADAS,CGW_ADAS,FCM
 SG_ ESC_LgtAcc : 119|16@0+ (0.002,-65) [-65|65] "m/s²"  VCU_ADAS,EPS1_ADAS,CGW_ADAS,FCM
 SG_ ALIVE_ESC_02 : 23|8@0+ (1,0) [0|255] ""  CGW_ADAS,VCU_ADAS,EPS1_ADAS,FCM
 SG_ CRC_ESC_02 : 7|16@0+ (1,0) [0|65535] ""  VCU_ADAS,EPS1_ADAS,FCM,CGW_ADAS
 SG_ ESC_YawRt_Q : 155|4@0+ (1,0) [0|15] ""  CGW_ADAS,VCU_ADAS,EPS1_ADAS,FCM
 SG_ ESC_YawRt : 167|16@0+ (0.005,-163.84) [-163.84|163.835] "°/sec"  CGW_ADAS,VCU_ADAS,EPS1_ADAS,FCM

BO_ 299 ESC_04_Torques: 48 ESC_ADAS
 SG_ ESC_IntvAct_Q : 343|4@0+ (1,0) [0|15] ""  VCU_ADAS,CGW_ADAS
 SG_ ESC_IntvAct : 329|2@0+ (1,0) [0|3] ""  VCU_ADAS,CGW_ADAS
 SG_ ESC_DTC_IntvAct_Q : 333|4@0+ (1,0) [0|15] ""  VCU_ADAS,CGW_ADAS
 SG_ ESC_DTC_IntvAct : 335|2@0+ (1,0) [0|3] ""  VCU_ADAS,CGW_ADAS
 SG_ ESC_TCS_IntvAct_Q : 323|4@0+ (1,0) [0|15] ""  CGW_ADAS,VCU_ADAS
 SG_ SSecOC_MAC_ESC_04 : 39|64@0+ (1,0) [0|1.84467440737096E+019] ""  VCU_ADAS,CGW_ADAS
 SG_ SSecOC_Fresh_ESC_04 : 31|8@0+ (1,0) [0|255] ""  VCU_ADAS,CGW_ADAS
 SG_ ESC_MotRotSpdMinLim_RA_Q : 115|4@0+ (1,0) [0|15] ""  CGW_ADAS,VCU_ADAS
 SG_ ESC_MotRotSpdMinLim_FA_Q : 119|4@0+ (1,0) [0|15] ""  CGW_ADAS,VCU_ADAS
 SG_ ESC_MotRotSpdMinLim_RA_Sts : 97|1@0+ (1,0) [0|1] ""  CGW_ADAS,VCU_ADAS
 SG_ ESC_MotRotSpdMinLim_FA_Sts : 99|1@0+ (1,0) [0|1] ""  CGW_ADAS,VCU_ADAS
 SG_ ESC_MotRotSpdMinLim_RA : 127|8@0- (1,0) [-128|127] ""  CGW_ADAS,VCU_ADAS
 SG_ ESC_MotRotSpdMinLim_FA : 135|8@0- (1,0) [-128|127] ""  CGW_ADAS,VCU_ADAS
 SG_ ESC_RecuWhlTqReq : 207|16@0- (1,0) [-32768|32767] "Nm"  CGW_ADAS,VCU_ADAS
 SG_ ESC_StabWhlTq_RA : 191|16@0- (1,0) [-32768|32767] ""  CGW_ADAS,VCU_ADAS
 SG_ ESC_StabWhlTq_FA : 175|16@0- (1,0) [-32768|32767] "Nm"  CGW_ADAS,VCU_ADAS
 SG_ ESC_MotRotSpdMaxLim_FA : 159|16@0- (1,0) [-32768|32767] ""  CGW_ADAS,VCU_ADAS
 SG_ ESC_MotRotSpdMaxLim_RA : 143|16@0- (1,0) [-32768|32767] ""  CGW_ADAS,VCU_ADAS
 SG_ ESC_TCS_IntvAct : 313|2@0+ (1,0) [0|3] ""  CGW_ADAS,VCU_ADAS
 SG_ ESC_MotRotSpdMaxLim_FA_Sts : 103|1@0+ (1,0) [0|1] ""  CGW_ADAS,VCU_ADAS
 SG_ ESC_MotRotSpdMaxLim_RA_Sts : 101|1@0+ (1,0) [0|1] ""  CGW_ADAS,VCU_ADAS
 SG_ ESC_RecuWhlTqReq_Q : 319|4@0+ (1,0) [0|15] ""  CGW_ADAS,VCU_ADAS
 SG_ ESC_StabWhlTq_FA_Q : 291|4@0+ (1,0) [0|15] ""  CGW_ADAS,VCU_ADAS
 SG_ ESC_RecuWhlTqReq_Sts : 309|2@0+ (1,0) [0|3] ""  CGW_ADAS,VCU_ADAS
 SG_ ESC_StabWhlTq_FA_Sts : 293|2@0+ (1,0) [0|3] ""  CGW_ADAS,VCU_ADAS
 SG_ ESC_StabWhlTq_RA_Q : 283|4@0+ (1,0) [0|15] ""  CGW_ADAS,VCU_ADAS
 SG_ ESC_StabWhlTq_RA_Sts : 295|2@0+ (1,0) [0|3] ""  CGW_ADAS,VCU_ADAS
 SG_ ESC_MotRotSpdMaxLim_FA_Q : 111|4@0+ (1,0) [0|15] ""  VCU_ADAS,CGW_ADAS
 SG_ ESC_MotRotSpdMaxLim_RA_Q : 107|4@0+ (1,0) [0|15] ""  VCU_ADAS,CGW_ADAS
 SG_ ESC_CFA_Min : 279|7@0+ (0.01,0) [0|1] ""  VCU_ADAS,CGW_ADAS
 SG_ ESC_DrvTotBrkTqReq_Q : 299|4@0+ (1,0) [0|15] ""  VCU_ADAS,CGW_ADAS
 SG_ ESC_TotBrkTqReq_Q : 287|4@0+ (1,0) [0|15] ""  VCU_ADAS,CGW_ADAS
 SG_ ESC_CFA_Max : 271|7@0+ (0.01,0) [0|1] ""  VCU_ADAS,CGW_ADAS
 SG_ ESC_DrvTotBrkTqReq : 255|16@0+ (1,-32000) [-32000|0] "Nm"  VCU_ADAS,CGW_ADAS
 SG_ ESC_TotBrkTqReq : 239|16@0+ (1,-32000) [-32000|0] "Nm"  VCU_ADAS,CGW_ADAS
 SG_ ALIVE_ESC_04 : 23|8@0+ (1,0) [0|255] ""  VCU_ADAS,CGW_ADAS
 SG_ CRC_ESC_04 : 7|16@0+ (1,0) [0|65535] ""  VCU_ADAS,CGW_ADAS

BO_ 152 ESC_03_Status_Functions: 32 ESC_ADAS
 SG_ SSecOC_MAC_ESC_03 : 39|64@0+ (1,0) [0|1.84467440737096E+019] ""  FCM,VCU_ADAS,CGW_ADAS
 SG_ SSecOC_Fresh_ESC_03 : 31|8@0+ (1,0) [0|255] ""  FCM,VCU_ADAS,CGW_ADAS
 SG_ ESC_ActvIndcn_AEB : 207|1@0+ (1,0) [0|1] ""  VCU_ADAS,FCM,CGW_ADAS
 SG_ ESC_FltIndcn_AEB : 206|2@0+ (1,0) [0|3] ""  VCU_ADAS,FCM,CGW_ADAS
 SG_ ESC_BrkDiscTemp : 175|16@0+ (1,0) [0|2000] "°C"  CGW_ADAS,VCU_ADAS,FCM
 SG_ ESC_ABS_IntvAct : 141|2@0+ (1,0) [0|3] ""  CGW_ADAS,VCU_ADAS,FCM
 SG_ ESC_SysSts : 127|2@0+ (1,0) [0|3] ""  CGW_ADAS,VCU_ADAS,FCM
 SG_ ESC_EssReq : 199|3@0+ (1,0) [0|7] ""  CGW_ADAS,VCU_ADAS,FCM
 SG_ ESC_EssReq_Q : 147|4@0+ (1,0) [0|15] ""  CGW_ADAS,VCU_ADAS,FCM
 SG_ ESC_BrkLiReq_Q : 155|4@0+ (1,0) [0|15] ""  CGW_ADAS,VCU_ADAS,FCM
 SG_ ESC_BrkLiReq : 157|2@0+ (1,0) [0|3] ""  CGW_ADAS,VCU_ADAS,FCM
 SG_ ESC_MstCylP_Q : 119|4@0+ (1,0) [0|15] ""  CGW_ADAS,VCU_ADAS,FCM
 SG_ ESC_MstCylP : 103|16@0+ (0.01,0) [0|250] "bar"  CGW_ADAS,VCU_ADAS,FCM
 SG_ ESC_BTC_IntvAct_Q : 123|4@0+ (1,0) [0|15] ""  VCU_ADAS,FCM,CGW_ADAS
 SG_ ESC_SystSts_EPB : 135|2@0+ (1,0) [0|3] ""  CGW_ADAS,VCU_ADAS,FCM
 SG_ ESC_AVH_Actv : 159|2@0+ (1,0) [0|3] ""  CGW_ADAS,VCU_ADAS,FCM
 SG_ ESC_CDP_Actv : 151|2@0+ (1,0) [0|3] ""  CGW_ADAS,VCU_ADAS,FCM
 SG_ ESC_EPB_SwitchPosition : 165|2@0+ (1,0) [0|3] ""  CGW_ADAS,VCU_ADAS,FCM
 SG_ ESC_EPB_SwitchPosition_Q : 163|4@0+ (1,0) [0|15] ""  CGW_ADAS,VCU_ADAS,FCM
 SG_ ESC_BTC_IntvAct : 125|2@0+ (1,0) [0|3] ""  VCU_ADAS,FCM,CGW_ADAS
 SG_ ESC_VDC_IntvAct_Q : 131|4@0+ (1,0) [0|15] ""  CGW_ADAS,VCU_ADAS,FCM
 SG_ ESC_ABS_IntvAct_Q : 139|4@0+ (1,0) [0|15] ""  CGW_ADAS,VCU_ADAS,FCM
 SG_ ESC_DrvPressBrkPedl : 167|1@0+ (1,0) [0|1] ""  FCM,VCU_ADAS,CGW_ADAS
 SG_ ESC_SpecialMode : 188|2@0+ (1,0) [0|3] ""  VCU_ADAS,FCM,CGW_ADAS
 SG_ ESC_VDC_IntvAct : 133|2@0+ (1,0) [0|3] ""  FCM,VCU_ADAS,CGW_ADAS
 SG_ ESC_Mode : 115|4@0+ (1,0) [0|15] ""  VCU_ADAS,FCM,CGW_ADAS
 SG_ ESC_SystSts_HDC : 191|3@0+ (1,0) [0|7] ""  CGW_ADAS,VCU_ADAS,FCM
 SG_ ESC_SystSts_AVH : 143|2@0+ (1,0) [0|3] ""  CGW_ADAS,VCU_ADAS,FCM
 SG_ ALIVE_ESC_03 : 23|8@0+ (1,0) [0|255] ""  CGW_ADAS,FCM,VCU_ADAS
 SG_ CRC_ESC_03 : 7|16@0+ (1,0) [0|65535] ""  CGW_ADAS,FCM,VCU_ADAS

BO_ 787 HU_01_OTA: 16 CGW_ADAS
 SG_ ALIVE_HU_01 : 23|8@0+ (1,0) [0|255] ""  VCU_ADAS,EPS1_ADAS,IM,FCM,ESC_ADAS,iBooster_ADAS,TPMS
 SG_ CRC_HU_01 : 7|16@0+ (1,0) [0|65535] ""  VCU_ADAS,EPS1_ADAS,IM,FCM,ESC_ADAS,iBooster_ADAS,TPMS
 SG_ HU_OTA_UpdateConfirm : 103|3@0+ (1,0) [0|7] ""  VCU_ADAS,EPS1_ADAS,IM,FCM,ESC_ADAS,iBooster_ADAS,TPMS

BO_ 786 ESC_05_OTA: 16 ESC_ADAS
 SG_ ALIVE_ESC_05 : 23|8@0+ (1,0) [0|255] ""  CGW_ADAS,VCU_ADAS,EPS1_ADAS,IM,FCM,iBooster_ADAS,TPMS
 SG_ CRC_ESC_05 : 7|16@0+ (1,0) [0|65535] ""  CGW_ADAS,VCU_ADAS,EPS1_ADAS,IM,FCM,iBooster_ADAS,TPMS
 SG_ ESC_OTA_inhib_FB : 103|2@0+ (1,0) [0|3] ""  CGW_ADAS,VCU_ADAS,EPS1_ADAS,IM,FCM,iBooster_ADAS,TPMS

BO_ 386 FCM_02_SA: 20 FCM
 SG_ SSecOC_MAC_FCM_02 : 39|64@0+ (1,0) [0|1.84467440737096E+019] ""  CGW_ADAS
 SG_ SSecOC_Fresh_FCM_02 : 31|8@0+ (1,0) [0|255] ""  CGW_ADAS
 SG_ CRC_FCM_02 : 7|16@0+ (1,0) [0|65535] ""  CGW_ADAS
 SG_ ALIVE_FCM_02 : 23|8@0+ (1,0) [0|255] ""  CGW_ADAS
 SG_ FCM_LatVelocityLane : 151|8@0+ (1,0) [0|255] ""  CGW_ADAS
 SG_ FCM_LonVelocityLane : 143|8@0+ (1,0) [0|255] ""  CGW_ADAS
 SG_ FCM_LatClearanceRi : 135|8@0+ (1,0) [0|255] ""  CGW_ADAS
 SG_ FCM_LatClearanceLe : 127|8@0+ (1,0) [0|255] ""  CGW_ADAS
 SG_ FCM_HostLaneWidth : 119|8@0+ (1,0) [0|255] ""  CGW_ADAS
 SG_ FCM_LaneMarkingWidth : 111|8@0+ (1,0) [0|255] ""  CGW_ADAS
 SG_ FCM_LaneMarkingColor : 98|2@0+ (1,0) [0|3] ""  CGW_ADAS
 SG_ FCM_LaneMarkingTyp : 101|3@0+ (1,0) [0|7] ""  CGW_ADAS
 SG_ FCM_LaneMarkingSts : 103|2@0+ (1,0) [0|3] ""  CGW_ADAS
 SG_ FCM_DRA_AESA_ECALL_Req : 159|1@0+ (1,0) [0|1] ""  CGW_ADAS

BO_ 357 FCM_03_STATUS_HU: 24 FCM
 SG_ FCM_LA_sens_Feed : 177|2@0+ (1,0) [0|3] ""  CGW_ADAS
 SG_ FCM_ELKA_ON_Feed : 169|2@0+ (1,0) [0|3] ""  CGW_ADAS
 SG_ FCM_LA_Mode_Feed : 153|2@0+ (1,0) [0|3] ""  CGW_ADAS
 SG_ FCM_HWA_ICON_Feed : 180|3@0+ (1,0) [0|7] ""  CGW_ADAS
 SG_ FCM_DRA_Sts : 183|3@0+ (1,0) [0|7] ""  CGW_ADAS
 SG_ FCM_AESA_Sts : 172|3@0+ (1,0) [0|7] ""  CGW_ADAS
 SG_ SSecOC_MAC_FCM_03 : 39|64@0+ (1,0) [0|1.84467440737096E+019] ""  CGW_ADAS
 SG_ SSecOC_Fresh_FCM_03 : 31|8@0+ (1,0) [0|255] ""  CGW_ADAS
 SG_ FCM_PDC_SettingSts : 125|2@0+ (1,0) [0|3] ""  CGW_ADAS
 SG_ FCM_BSW_Sts : 127|2@0+ (1,0) [0|3] ""  CGW_ADAS
 SG_ FCM_DRA_DstSetgsSts : 113|2@0+ (1,0) [0|3] ""  CGW_ADAS
 SG_ FCM_DRA_BehaviorSts : 115|2@0+ (1,0) [0|3] ""  CGW_ADAS
 SG_ FCM_ASA_RoadCondSts : 117|2@0+ (1,0) [0|3] ""  CGW_ADAS
 SG_ FCM_ASA_LegalLimSts : 119|2@0+ (1,0) [0|3] ""  CGW_ADAS
 SG_ FCM_ELK_Sts : 106|3@0+ (1,0) [0|7] ""  CGW_ADAS
 SG_ FCM_LDW_Sts : 175|3@0+ (1,0) [0|7] ""  CGW_ADAS
 SG_ FCM_ASA_SpdChgWarnSts : 108|2@0+ (1,0) [0|3] ""  CGW_ADAS
 SG_ FCM_ASA_OverSpdWarnSts : 111|3@0+ (1,0) [0|7] ""  CGW_ADAS
 SG_ FCM_DCA_Sts : 97|2@0+ (1,0) [0|3] ""  CGW_ADAS
 SG_ FCM_AEB_Sts : 99|2@0+ (1,0) [0|3] ""  CGW_ADAS
 SG_ FCM_FCW_Snvty : 101|2@0+ (1,0) [0|3] ""  CGW_ADAS
 SG_ FCM_FCW_Sts : 103|2@0+ (1,0) [0|3] ""  CGW_ADAS
 SG_ ALIVE_FCM_03 : 23|8@0+ (1,0) [0|255] ""  CGW_ADAS
 SG_ CRC_FCM_03 : 7|16@0+ (1,0) [0|65535] ""  CGW_ADAS
 SG_ FCM_DRA_AESA_Status : 185|2@0+ (1,0) [0|3] ""  CGW_ADAS
 SG_ FCM_HOW_Sts : 162|3@0+ (1,0) [0|7] ""  CGW_ADAS
 SG_ FCM_LCA_Sts : 167|3@0+ (1,0) [0|7] ""  CGW_ADAS
 SG_ FCM_VehPosiLane : 159|4@0+ (1,0) [0|15] ""  CGW_ADAS
 SG_ FCM_TakeoverWarnSts : 164|2@0+ (1,0) [0|3] ""  CGW_ADAS
 SG_ FCM_ASA_Sts : 155|2@0+ (1,0) [0|3] ""  CGW_ADAS
 SG_ FCM_DCA_Warn : 135|8@0+ (1,0) [0|255] ""  CGW_ADAS
 SG_ FCM_DCA_Sts2 : 123|4@0+ (1,0) [0|15] ""  CGW_ADAS

BO_ 352 HU_05_SET_ADAS: 32 CGW_ADAS
 SG_ HU_Veh_DoorLock : 229|1@0+ (1,0) [0|1] ""  IM,VCU_ADAS,FCM,EPS1_ADAS
 SG_ HU_Veh_GearPosition : 202|3@0+ (1,0) [0|7] ""  IM,VCU_ADAS,FCM,EPS1_ADAS
 SG_ HU_Veh_TurnLed : 204|2@0+ (1,0) [0|2] ""  IM,VCU_ADAS,FCM,EPS1_ADAS
 SG_ HU_VehSteerWhlAngle : 223|10@0+ (1,0) [0|720] "degree"  IM,VCU_ADAS,FCM,EPS1_ADAS
 SG_ HU_Veh_SteerAngle_Symbol : 205|1@0+ (1,0) [0|1] ""  IM,VCU_ADAS,FCM,EPS1_ADAS
 SG_ HU_Veh_Speed : 215|8@0+ (1,0) [0|250] "km/h"  IM,VCU_ADAS,FCM,EPS1_ADAS
 SG_ HU_LDW_Switch : 123|2@0+ (1,0) [0|3] ""  IM,VCU_ADAS,FCM,EPS1_ADAS
 SG_ HOD_HandsMonitor : 121|2@0+ (1,0) [0|3] ""  VCU_ADAS,IM,FCM,EPS1_ADAS
 SG_ HU_FunctSelect : 239|4@0+ (1,0) [0|15] ""  VCU_ADAS,IM,FCM,EPS1_ADAS
 SG_ HU_SpeedControlSts : 233|2@0+ (1,0) [0|3] ""  VCU_ADAS,IM,FCM,EPS1_ADAS
 SG_ HU_CruiseControlSts : 235|2@0+ (1,0) [0|3] ""  VCU_ADAS,IM,FCM,EPS1_ADAS
 SG_ SET_ACCSoftbutton_mode : 207|2@0+ (1,0) [0|3] ""  IM,VCU_ADAS,FCM,EPS1_ADAS
 SG_ SET_ACCSoftButton_set_timegap : 195|4@0+ (1,0) [0|15] ""  IM,VCU_ADAS,FCM,EPS1_ADAS
 SG_ HU_PDCPopupSts : 197|2@0+ (1,0) [0|3] ""  IM,VCU_ADAS,EPS1_ADAS,FCM
 SG_ SET_PDCSoftButton_Front : 199|2@0+ (1,0) [0|3] ""  IM,VCU_ADAS,EPS1_ADAS,FCM
 SG_ MILE_KM : 143|24@0+ (1,0) [0|16777200] "km"  IM,FCM,VCU_ADAS,EPS1_ADAS
 SG_ HandsoffDetection : 135|8@0+ (1,0) [0|255] ""  IM,VCU_ADAS,EPS1_ADAS,FCM
 SG_ SET_PDCSetting : 125|2@0+ (1,0) [0|3] ""  IM,VCU_ADAS,EPS1_ADAS,FCM
 SG_ SET_BlindSpotWarning : 127|2@0+ (1,0) [0|3] ""  IM,VCU_ADAS,EPS1_ADAS,FCM
 SG_ SET_DistanceSettings : 113|2@0+ (1,0) [0|3] ""  IM,VCU_ADAS,EPS1_ADAS,FCM
 SG_ SET_DrivingAssistBehavior : 115|2@0+ (1,0) [0|3] ""  IM,VCU_ADAS,EPS1_ADAS,FCM
 SG_ SET_AutoSpeedAdaption_RoadCond : 117|2@0+ (1,0) [0|3] ""  IM,VCU_ADAS,EPS1_ADAS,FCM
 SG_ SET_AutoSpeedAdaption_LegalLimit : 119|2@0+ (1,0) [0|3] ""  IM,VCU_ADAS,EPS1_ADAS,FCM
 SG_ SET_ELK : 105|2@0+ (1,0) [0|3] ""  IM,VCU_ADAS,EPS1_ADAS,FCM
 SG_ SET_LDW : 107|2@0+ (1,0) [0|3] ""  IM,VCU_ADAS,EPS1_ADAS,FCM
 SG_ SET_SpeedChangeWarning : 109|2@0+ (1,0) [0|3] ""  IM,VCU_ADAS,EPS1_ADAS,FCM
 SG_ SET_OverspeedWarning : 111|2@0+ (1,0) [0|3] ""  IM,VCU_ADAS,EPS1_ADAS,FCM
 SG_ SET_DriverConditionAssist : 97|2@0+ (1,0) [0|3] ""  IM,VCU_ADAS,EPS1_ADAS,FCM
 SG_ SET_AEB : 99|2@0+ (1,0) [0|3] ""  IM,VCU_ADAS,EPS1_ADAS,FCM
 SG_ SET_ForwardCollWarn_Sensitivity : 101|2@0+ (1,0) [0|3] ""  IM,VCU_ADAS,EPS1_ADAS,FCM
 SG_ SET_ForwardCollisionWarning : 103|2@0+ (1,0) [0|3] ""  IM,VCU_ADAS,EPS1_ADAS,FCM
 SG_ ALIVE_HU_05 : 23|8@0+ (1,0) [0|255] ""  IM,VCU_ADAS,FCM,EPS1_ADAS
 SG_ CRC_HU_05 : 7|16@0+ (1,0) [0|65535] ""  IM,VCU_ADAS,FCM,EPS1_ADAS
 SG_ HU_ELK_AcoustWarnSetg : 226|2@0+ (1,0) [0|3] ""  IM,VCU_ADAS,FCM,EPS1_ADAS
 SG_ RNG : 167|12@0+ (1,0) [0|4094] "km"  IM,VCU_ADAS,EPS1_ADAS,FCM
 SG_ SET_ASA : 169|2@0+ (1,0) [0|3] ""  IM,VCU_ADAS,EPS1_ADAS,FCM
 SG_ SET_PDCSoftButton : 228|2@0+ (1,0) [0|3] ""  VCU_ADAS,IM,FCM,EPS1_ADAS
 SG_ ASA_SpdLimFusion : 191|8@0+ (1,0) [0|255] ""  IM,VCU_ADAS,EPS1_ADAS,FCM
 SG_ STAT_ISAMap : 171|2@0+ (1,0) [0|3] ""  IM,VCU_ADAS,EPS1_ADAS,FCM
 SG_ HU_SpdLimMap : 183|8@0+ (1,0) [0|255] ""  IM,VCU_ADAS,EPS1_ADAS,FCM

BO_ 400 SWS_02_CC_RQ: 20 CGW_ADAS
 SG_ V2X_Charging : 143|8@0+ (1,0) [0|255] ""  VCU_ADAS,FCM,ESC_ADAS
 SG_ ChargeCurrent : 135|8@0+ (1,0) [0|255] ""  VCU_ADAS,FCM,ESC_ADAS
 SG_ StateOfCharge : 127|8@0+ (1,0) [0|255] ""  VCU_ADAS,FCM,ESC_ADAS
 SG_ ChargePort_Lock : 119|8@0+ (1,0) [0|255] ""  VCU_ADAS,FCM,ESC_ADAS
 SG_ Charging_ONOFF : 111|8@0+ (1,0) [0|255] ""  VCU_ADAS,FCM,ESC_ADAS
 SG_ CC_STATE : 97|2@0+ (1,0) [0|3] ""  VCU_ADAS,FCM,ESC_ADAS
 SG_ CC_CNL : 99|2@0+ (1,0) [0|3] ""  VCU_ADAS,FCM,ESC_ADAS
 SG_ CC_RES : 101|2@0+ (1,0) [0|3] ""  VCU_ADAS,FCM,ESC_ADAS
 SG_ CC_SET : 103|2@0+ (1,0) [0|3] ""  VCU_ADAS,FCM,ESC_ADAS
 SG_ ALIVE_SWS_02 : 23|8@0+ (1,0) [0|255] ""  VCU_ADAS,FCM,ESC_ADAS
 SG_ CRC_SWS_02 : 7|16@0+ (1,0) [0|65535] ""  VCU_ADAS,FCM,ESC_ADAS

BO_ 1055 WarnMsg_iBooster: 16 iBooster_ADAS
 SG_ SSecOC_MAC_iBoosterWarnMsg : 39|64@0+ (1,0) [0|255] ""  CGW_ADAS
 SG_ SSecOC_Fresh_iBoosterWarnMsg : 31|8@0+ (1,0) [0|255] ""  CGW_ADAS
 SG_ WarningMessageID_iBooster : 111|16@0+ (1,0) [0|65535] ""  CGW_ADAS
 SG_ BitBlinking_iBooster : 99|2@0+ (1,0) [0|3] "Bit"  CGW_ADAS
 SG_ BitStatus_iBooster : 97|2@0+ (1,0) [0|3] "Bit"  CGW_ADAS
 SG_ ALIVE_WarnMsg_iBooster : 23|8@0+ (1,0) [0|255] ""  CGW_ADAS
 SG_ CRC_WarnMsg_iBooster : 7|16@0+ (1,0) [0|65535] ""  CGW_ADAS

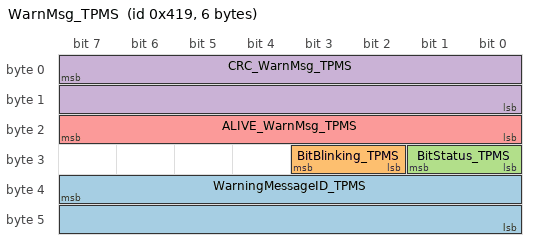
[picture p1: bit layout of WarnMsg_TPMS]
BO_ 1049 WarnMsg_TPMS: 6 TPMS
 SG_ WarningMessageID_TPMS : 39|16@0+ (1,0) [0|65535] ""  CGW_ADAS
 SG_ BitBlinking_TPMS : 27|2@0+ (1,0) [0|3] "Bit"  CGW_ADAS
 SG_ BitStatus_TPMS : 25|2@0+ (1,0) [0|3] "Bit"  CGW_ADAS
 SG_ CRC_WarnMsg_TPMS : 7|16@0+ (1,0) [0|65535] ""  CGW_ADAS
 SG_ ALIVE_WarnMsg_TPMS : 23|8@0+ (1,0) [0|255] ""  CGW_ADAS

BO_ 2564485407 Diag_Resp_iBooster: 64 iBooster_ADAS
 SG_ Diag_Resp_iBooster : 7|64@0+ (1,0) [0|1.84467440737096E+019] "N/A"  CGW_ADAS

BO_ 2564485401 Diag_Resp_TPMS: 64 TPMS
 SG_ Diag_Resp_TPMS : 7|64@0+ (1,0) [0|1.84467440737096E+019] "N/A"  CGW_ADAS

BO_ 2564431857 Diag_PhyReq_iBooster: 64 CGW_ADAS
 SG_ Diag_PhyReq_iBooster : 7|64@0+ (1,0) [0|1.84467440737096E+019] "N/A"  iBooster_ADAS

BO_ 2564430321 Diag_PhyReq_TPMS: 64 CGW_ADAS
 SG_ Diag_PhyReq_TPMS : 7|64@0+ (1,0) [0|1.84467440737096E+019] "N/A"  TPMS

BO_ 263 BCM_11_WIPERWASHER_STATUS: 16 CGW_ADAS
 SG_ ALIVE_BCM_11 : 23|8@0+ (1,0) [0|255] ""  FCM
 SG_ STAT_WiperSensitivityInterval : 103|3@0+ (1,0) [0|7] ""  FCM
 SG_ CRC_BCM_11 : 7|16@0+ (1,0) [0|65535] ""  FCM
 SG_ STAT_WasherRear : 109|2@0+ (1,0) [0|3] ""  FCM
 SG_ STAT_WiperRear : 111|2@0+ (1,0) [0|3] ""  FCM
 SG_ STAT_WasherFront : 97|2@0+ (1,0) [0|3] ""  FCM
 SG_ STAT_WiperFront : 100|3@0+ (1,0) [0|7] ""  FCM

BO_ 265 BCM_08_SWITCH_STATUS: 20 CGW_ADAS
 SG_ STAT_AutoAC_Button : 145|2@0+ (1,0) [0|3] ""  ESC_ADAS,FCM,VCU_ADAS
 SG_ STAT_ESCButton : 147|2@0+ (1,0) [0|3] ""  VCU_ADAS,FCM,ESC_ADAS
 SG_ STAT_WadingModeButton : 149|2@0+ (1,0) [0|3] ""  FCM,ESC_ADAS,VCU_ADAS
 SG_ STAT_DownhillAssistButton : 151|2@0+ (1,0) [0|3] ""  VCU_ADAS,FCM,ESC_ADAS
 SG_ STAT_InteriorSocket230VButton : 137|2@0+ (1,0) [0|3] ""  VCU_ADAS,FCM,ESC_ADAS
 SG_ STAT_PDC_Button : 129|2@0+ (1,0) [0|3] ""  VCU_ADAS,FCM,ESC_ADAS
 SG_ STAT_MaxAC_Button : 121|2@0+ (1,0) [0|3] ""  FCM,ESC_ADAS,VCU_ADAS
 SG_ STAT_BLTS_BCM_Mon : 111|2@0+ (1,0) [0|3] ""  ESC_ADAS,FCM,VCU_ADAS
 SG_ STAT_TemperatureRightWheel : 140|3@0+ (1,0) [0|7] ""  VCU_ADAS,FCM,ESC_ADAS
 SG_ STAT_TemperatureLeftWheel : 143|3@0+ (1,0) [0|7] ""  VCU_ADAS,FCM,ESC_ADAS
 SG_ STAT_FAN_Wheel : 132|3@0+ (1,0) [0|7] ""  VCU_ADAS,FCM,ESC_ADAS
 SG_ STAT_AC_Button : 123|2@0+ (1,0) [0|3] ""  FCM,ESC_ADAS,VCU_ADAS
 SG_ STAT_Zone_Wheel : 135|3@0+ (1,0) [0|7] ""  VCU_ADAS,FCM,ESC_ADAS
 SG_ STAT_Recirculation_Button : 125|2@0+ (1,0) [0|3] ""  FCM,ESC_ADAS,VCU_ADAS
 SG_ STAT_Windshield_Button : 127|2@0+ (1,0) [0|3] ""  FCM,ESC_ADAS,VCU_ADAS
 SG_ STAT_MultimediaControlButton : 114|3@0+ (1,0) [0|7] ""  FCM,ESC_ADAS,VCU_ADAS
 SG_ STAT_MultimediaVolumeButton : 117|3@0+ (1,0) [0|7] ""  FCM,ESC_ADAS,VCU_ADAS
 SG_ STAT_Display_Button : 119|2@0+ (1,0) [0|3] ""  FCM,ESC_ADAS,VCU_ADAS
 SG_ STAT_SteeringWheelHeating_Button : 105|2@0+ (1,0) [0|3] ""  FCM,ESC_ADAS,VCU_ADAS
 SG_ STAT_Sync_Button : 107|2@0+ (1,0) [0|3] ""  FCM,ESC_ADAS,VCU_ADAS
 SG_ STAT_Defrost_Button : 109|2@0+ (1,0) [0|3] ""  FCM,ESC_ADAS,VCU_ADAS
 SG_ ALIVE_BCM_08 : 23|8@0+ (1,0) [0|255] ""  ESC_ADAS,VCU_ADAS,FCM
 SG_ CRC_BCM_08 : 7|16@0+ (1,0) [0|65535] ""  ESC_ADAS,VCU_ADAS,FCM
 SG_ STAT_BrakeLightSwitchBCM : 97|2@0+ (1,0) [0|3] ""  ESC_ADAS,FCM,VCU_ADAS
 SG_ STAT_Horn : 99|2@0+ (1,0) [0|3] ""  ESC_ADAS,FCM,VCU_ADAS
 SG_ STAT_WorkingLight_Button : 101|2@0+ (1,0) [0|3] ""  ESC_ADAS,FCM,VCU_ADAS
 SG_ STAT_HazardWarn : 103|2@0+ (1,0) [0|3] ""  ESC_ADAS,FCM,VCU_ADAS

BO_ 262 BCM_07_LIGHT: 32 CGW_ADAS
 SG_ STAT_ReadingLight_RR : 239|2@0+ (1,0) [0|3] ""  IM,VCU_ADAS,FCM,ESC_ADAS
 SG_ STAT_ActiveReadLightPA : 225|2@0+ (1,0) [0|3] ""  IM,VCU_ADAS,FCM,ESC_ADAS
 SG_ STAT_ActiveReadLightDR : 227|2@0+ (1,0) [0|3] ""  IM,VCU_ADAS,FCM,ESC_ADAS
 SG_ STAT_ActiveInteriorLight : 229|2@0+ (1,0) [0|3] ""  IM,VCU_ADAS,FCM,ESC_ADAS
 SG_ STAT_ActiveAmbientLight : 217|2@0+ (1,0) [0|3] ""  IM,VCU_ADAS,FCM,ESC_ADAS
 SG_ STAT_HeadlightTurnOnReminder : 219|2@0+ (1,0) [0|3] ""  IM,VCU_ADAS,FCM,ESC_ADAS
 SG_ STAT_HazardWarningLight : 221|2@0+ (1,0) [0|3] ""  IM,VCU_ADAS,FCM,ESC_ADAS
 SG_ STAT_Emergency_BrakeLight : 223|2@0+ (1,0) [0|3] ""  IM,VCU_ADAS,FCM,ESC_ADAS
 SG_ RLS_VoltageError : 92|2@0+ (1,0) [0|3] ""  IM,VCU_ADAS,ESC_ADAS,FCM
 SG_ RLS_TempSensorValue : 135|8@0+ (0.5,-40) [-40|87] "degC"  IM,VCU_ADAS,ESC_ADAS,FCM
 SG_ RLS_TempDewPoint : 87|11@0+ (0.1,-39.6) [-39.6|60.4] "degC"  IM,VCU_ADAS,ESC_ADAS,FCM
 SG_ STAT_ReadingLight_RL : 231|2@0+ (1,0) [0|3] ""  IM,VCU_ADAS,FCM,ESC_ADAS
 SG_ STAT_HeadlightReminder : 215|2@0+ (1,0) [0|3] ""  IM,VCU_ADAS,FCM,ESC_ADAS
 SG_ RLS_Solar_Right : 191|8@0+ (4,0) [0|1000] "w/m2"  IM,VCU_ADAS,ESC_ADAS,FCM
 SG_ RLS_Solar_Left : 183|8@0+ (4,0) [0|1000] "w/m2"  IM,VCU_ADAS,ESC_ADAS,FCM
 SG_ RLS_RS_FAULT : 173|1@0+ (1,0) [0|1] ""  IM,VCU_ADAS,ESC_ADAS,FCM
 SG_ RLS_Response_error : 169|1@0+ (1,0) [0|1] ""  IM,VCU_ADAS,ESC_ADAS,FCM
 SG_ RLS_Rainfall : 153|2@0+ (1,0) [0|3] ""  IM,VCU_ADAS,ESC_ADAS,FCM
 SG_ RLS_LiSwitchReason : 155|2@0+ (1,0) [0|3] ""  IM,VCU_ADAS,ESC_ADAS,FCM
 SG_ RLS_HumidSensorValue : 143|8@0+ (0.5,-0.5) [-0.5|127] "%"  IM,VCU_ADAS,ESC_ADAS,FCM
 SG_ RLS_Humid_Temp_Error : 170|1@0+ (1,0) [0|1] ""  IM,VCU_ADAS,ESC_ADAS,FCM
 SG_ RLS_FWBrightness : 167|10@0+ (6,0) [0|6126] "Lux"  IM,VCU_ADAS,ESC_ADAS,FCM
 SG_ RLS_COMMFAULT : 171|1@0+ (1,0) [0|1] ""  IM,VCU_ADAS,ESC_ADAS,FCM
 SG_ RLS_AutoPanel : 172|1@0+ (1,0) [0|1] ""  IM,VCU_ADAS,ESC_ADAS,FCM
 SG_ RLS_AmbBrightness : 151|12@0+ (20,0) [0|81880] "Lux"  IM,VCU_ADAS,ESC_ADAS,FCM
 SG_ BCM_BSM_OTM_Right_LED_State : 210|3@0+ (1,0) [0|7] ""  IM,VCU_ADAS,FCM,ESC_ADAS
 SG_ BCM_BSM_OTM_Left_LED_State : 213|3@0+ (1,0) [0|7] ""  IM,VCU_ADAS,FCM,ESC_ADAS
 SG_ STAT_LicenceLight : 127|2@0+ (1,0) [0|3] ""  IM,VCU_ADAS,ESC_ADAS,FCM
 SG_ STAT_WorkingLight : 113|2@0+ (1,0) [0|3] ""  IM,VCU_ADAS,ESC_ADAS,FCM
 SG_ STAT_LowBeam : 119|2@0+ (1,0) [0|3] "Bit"  IM,VCU_ADAS,ESC_ADAS,FCM
 SG_ STAT_PositionLight : 117|2@0+ (1,0) [0|3] "Bit"  IM,VCU_ADAS,ESC_ADAS,FCM
 SG_ STAT_BrakeLight : 115|2@0+ (1,0) [0|3] ""  IM,VCU_ADAS,ESC_ADAS,FCM
 SG_ STAT_LightActivation : 98|3@0+ (1,0) [0|7] ""  IM,VCU_ADAS,ESC_ADAS,FCM
 SG_ STAT_DRL : 107|2@0+ (1,0) [0|3] "Bit"  IM,VCU_ADAS,ESC_ADAS,FCM
 SG_ STAT_TurnIndicators : 101|3@0+ (1,0) [0|7] "Bit"  IM,VCU_ADAS,ESC_ADAS,FCM
 SG_ STAT_ReverseLight : 109|2@0+ (1,0) [0|3] ""  IM,VCU_ADAS,ESC_ADAS,FCM
 SG_ STAT_InteriorLight : 111|2@0+ (1,0) [0|3] "Bit"  IM,VCU_ADAS,ESC_ADAS,FCM
 SG_ STAT_FogLampRear : 103|2@0+ (1,0) [0|3] "Bit"  IM,VCU_ADAS,ESC_ADAS,FCM
 SG_ STAT_ADBFunction : 125|2@0+ (1,0) [0|3] ""  IM,VCU_ADAS,ESC_ADAS,FCM
 SG_ ALIVE_BCM_07 : 23|8@0+ (1,0) [0|255] ""  IM,VCU_ADAS,ESC_ADAS,FCM
 SG_ CRC_BCM_07 : 7|16@0+ (1,0) [0|65535] ""  IM,VCU_ADAS,ESC_ADAS,FCM
 SG_ STAT_HighBeam : 105|2@0+ (1,0) [0|3] "Bit"  IM,VCU_ADAS,ESC_ADAS,FCM

BO_ 324 ESC_01_VeloSpeed: 48 ESC_ADAS
 SG_ ESC_VehSpdLat_Q : 311|4@0+ (1,0) [0|15] ""  CGW_ADAS,EPS1_ADAS,FCM,iBooster_ADAS,IM,TPMS,VCU_ADAS
 SG_ ESC_VehSpdLat : 295|16@0+ (0.015625,0) [0|350] "km/h"  VCU_ADAS,TPMS,IM,iBooster_ADAS,FCM,EPS1_ADAS,CGW_ADAS
 SG_ SSecOC_MAC_ESC_01 : 39|64@0+ (1,0) [0|1.84467440737096E+019] ""  VCU_ADAS,TPMS,IM,iBooster_ADAS,FCM,EPS1_ADAS,CGW_ADAS
 SG_ SSecOC_Fresh_ESC_01 : 31|8@0+ (1,0) [0|255] ""  VCU_ADAS,TPMS,IM,iBooster_ADAS,FCM,EPS1_ADAS,CGW_ADAS
 SG_ ESC_WhlTck_RR_Q : 283|2@0+ (1,0) [0|3] ""  IM,iBooster_ADAS,EPS1_ADAS,CGW_ADAS,VCU_ADAS,FCM,TPMS
 SG_ ESC_WhlTck_RL_Q : 287|2@0+ (1,0) [0|3] ""  IM,iBooster_ADAS,EPS1_ADAS,CGW_ADAS,VCU_ADAS,FCM,TPMS
 SG_ ESC_WhlTck_FR_Q : 275|2@0+ (1,0) [0|3] ""  IM,iBooster_ADAS,EPS1_ADAS,CGW_ADAS,VCU_ADAS,FCM,TPMS
 SG_ ESC_WhlTck_RR : 271|8@0+ (1,0) [0|254] "Tick"  VCU_ADAS,IM,iBooster_ADAS,EPS1_ADAS,CGW_ADAS,FCM,TPMS
 SG_ ESC_WhlTck_RL : 263|8@0+ (1,0) [0|254] "Tick"  VCU_ADAS,IM,iBooster_ADAS,EPS1_ADAS,CGW_ADAS,FCM,TPMS
 SG_ ESC_WhlTck_FR : 255|8@0+ (1,0) [0|254] "Tick"  VCU_ADAS,IM,iBooster_ADAS,EPS1_ADAS,CGW_ADAS,FCM,TPMS
 SG_ ESC_WhlTck_FL_Q : 279|2@0+ (1,0) [0|3] ""  IM,iBooster_ADAS,EPS1_ADAS,CGW_ADAS,VCU_ADAS,FCM,TPMS
 SG_ ESC_WhlTck_FL : 247|8@0+ (1,0) [0|254] "Tick"  VCU_ADAS,IM,iBooster_ADAS,EPS1_ADAS,CGW_ADAS,FCM,TPMS
 SG_ ESC_WhlSpd_RR_Q : 223|2@0+ (1,0) [0|3] ""  iBooster_ADAS,VCU_ADAS,FCM,IM,EPS1_ADAS,CGW_ADAS,TPMS
 SG_ ESC_WhlSpd_RR : 207|16@0- (0.015625,0) [-400|400] "rad/s"  iBooster_ADAS,VCU_ADAS,FCM,IM,EPS1_ADAS,CGW_ADAS,TPMS
 SG_ ESC_WhlSpd_RL_Q : 199|2@0+ (1,0) [0|3] ""  iBooster_ADAS,VCU_ADAS,FCM,IM,EPS1_ADAS,CGW_ADAS,TPMS
 SG_ ESC_WhlSpd_RL : 183|16@0- (0.015625,0) [-400|400] "rad/s"  iBooster_ADAS,VCU_ADAS,FCM,IM,EPS1_ADAS,CGW_ADAS,TPMS
 SG_ ESC_WhlSpd_FR_Q : 175|2@0+ (1,0) [0|3] ""  iBooster_ADAS,VCU_ADAS,FCM,IM,EPS1_ADAS,CGW_ADAS,TPMS
 SG_ ESC_WhlSpd_FR : 159|16@0- (0.015625,0) [-400|400] "rad/s"  iBooster_ADAS,VCU_ADAS,FCM,IM,EPS1_ADAS,CGW_ADAS,TPMS
 SG_ ESC_WhlSpd_FL_Q : 151|2@0+ (1,0) [0|3] ""  iBooster_ADAS,VCU_ADAS,FCM,IM,EPS1_ADAS,CGW_ADAS,TPMS
 SG_ ESC_WhlSpd_FL : 135|16@0- (0.015625,0) [-400|400] "rad/s"  iBooster_ADAS,VCU_ADAS,FCM,IM,EPS1_ADAS,CGW_ADAS,TPMS
 SG_ ESC_VehDrvCond_Q : 127|2@0+ (1,0) [0|3] ""  VCU_ADAS,iBooster_ADAS,FCM,IM,EPS1_ADAS,CGW_ADAS,TPMS
 SG_ ESC_DrivDist_Q : 219|2@0+ (1,0) [0|3] ""  VCU_ADAS,IM,iBooster_ADAS,EPS1_ADAS,FCM,CGW_ADAS,TPMS
 SG_ ALIVE_ESC_01 : 23|8@0+ (1,0) [0|255] ""  iBooster_ADAS,EPS1_ADAS,VCU_ADAS,CGW_ADAS,FCM,TPMS,IM
 SG_ CRC_ESC_01 : 7|16@0+ (1,0) [0|65535] ""  iBooster_ADAS,EPS1_ADAS,VCU_ADAS,CGW_ADAS,FCM,TPMS,IM
 SG_ ESC_DrivDist : 231|16@0+ (1,0) [0|65535] "cm"  VCU_ADAS,IM,iBooster_ADAS,EPS1_ADAS,FCM,CGW_ADAS,TPMS
 SG_ ESC_VehDrvCond : 115|2@0+ (1,0) [0|3] ""  VCU_ADAS,iBooster_ADAS,FCM,IM,CGW_ADAS,EPS1_ADAS,TPMS
 SG_ ESC_VehSpd_Q : 119|2@0+ (1,0) [0|3] ""  iBooster_ADAS,EPS1_ADAS,VCU_ADAS,CGW_ADAS,FCM,IM,TPMS
 SG_ ESC_VehSpd : 103|16@0+ (0.015625,0) [0|350] "km/h"  iBooster_ADAS,EPS1_ADAS,VCU_ADAS,CGW_ADAS,FCM,IM,TPMS

BO_ 267 TM_01_STATUS: 16 CGW_ADAS
 SG_ SSecOC_MAC_TM_01 : 39|64@0+ (1,0) [0|255] ""  FCM,ESC_ADAS
 SG_ SSecOC_Fresh_TM_01 : 31|8@0+ (1,0) [0|255] ""  FCM,ESC_ADAS
 SG_ STAT_Hitch_TM : 127|2@0+ (1,0) [0|3] ""  FCM,ESC_ADAS
 SG_ ALIVE_TM_01 : 23|8@0+ (1,0) [0|255] ""  FCM,ESC_ADAS
 SG_ CRC_TM_01 : 7|16@0+ (1,0) [0|65535] ""  FCM,ESC_ADAS
 SG_ ST_TRAI : 121|2@0+ (1,0) [0|3] ""  FCM,ESC_ADAS
 SG_ TrailerInput : 119|2@0+ (1,0) [0|3] ""  FCM,ESC_ADAS
 SG_ STAT_HWPosLightInput_TM : 111|2@0+ (1,0) [0|3] ""  FCM,ESC_ADAS
 SG_ STAT_HWIndicatorInput_TM : 113|2@0+ (1,0) [0|3] ""  FCM,ESC_ADAS
 SG_ STAT_HWBrakeLightInput_TM : 109|2@0+ (1,0) [0|3] ""  FCM,ESC_ADAS
 SG_ VoltageStatus_TM : 99|2@0+ (1,0) [0|3] ""  FCM,ESC_ADAS
 SG_ STAT_BrakeLight_TM : 101|2@0+ (1,0) [0|3] ""  FCM,ESC_ADAS
 SG_ TrailerSystemError : 115|2@0+ (1,0) [0|3] ""  FCM,ESC_ADAS
 SG_ STAT_TurnIndicators_TM : 107|4@0+ (1,0) [0|15] "Bit"  FCM,ESC_ADAS
 SG_ STAT_FogLampRear_TM : 103|2@0+ (1,0) [0|3] "Bit"  FCM,ESC_ADAS
 SG_ STAT_PositionLight_TM : 97|2@0+ (1,0) [0|3] "Bit"  FCM,ESC_ADAS
 SG_ STAT_ReverseLight_TM : 117|2@0+ (1,0) [0|3] "Bit"  FCM,ESC_ADAS

BO_ 171 ACM_01_CRASH: 16 CGW_ADAS
 SG_ SSecOC_MAC_ACM_01 : 39|64@0+ (1,0) [0|1.84467440737096E+019] ""  VCU_ADAS,FCM
 SG_ ALIVE_ACM_01 : 23|8@0+ (1,0) [0|255] ""  VCU_ADAS,FCM
 SG_ CRC_ACM_01 : 7|16@0+ (1,0) [0|65535] ""  VCU_ADAS,FCM
 SG_ ST_CRASH_TYPE : 100|4@0+ (1,0) [0|15] ""  VCU_ADAS,FCM
 SG_ ST_CRASH : 103|3@0+ (1,0) [0|7] ""  VCU_ADAS,FCM
 SG_ SSecOC_Fresh_ACM_01 : 31|8@0+ (1,0) [0|255] ""  VCU_ADAS,FCM

BO_ 760 TBOX_02_TIME: 20 CGW_ADAS
 SG_ ALIVE_TBOX_02 : 23|8@0+ (1,0) [0|255] ""  IM,ESC_ADAS,VCU_ADAS,iBooster_ADAS,FCM,EPS1_ADAS,TPMS
 SG_ CRC_TBOX_02 : 7|16@0+ (1,0) [0|65535] ""  IM,ESC_ADAS,VCU_ADAS,iBooster_ADAS,FCM,EPS1_ADAS,TPMS
 SG_ TBOX_CrtTi_Hr : 119|5@0+ (1,0) [0|23] "h"  IM,ESC_ADAS,EPS1_ADAS,VCU_ADAS,iBooster_ADAS,FCM,TPMS
 SG_ TBOX_CrtTi_Mins : 111|6@0+ (1,0) [0|59] "min"  IM,ESC_ADAS,VCU_ADAS,EPS1_ADAS,iBooster_ADAS,FCM,TPMS
 SG_ TBOX_CrtTi_Sec : 103|6@0+ (1,0) [0|59] "s"  IM,ESC_ADAS,VCU_ADAS,iBooster_ADAS,EPS1_ADAS,FCM,TPMS
 SG_ TBOX_CrtTi_Day : 127|5@0+ (1,1) [1|31] "d"  IM,ESC_ADAS,EPS1_ADAS,VCU_ADAS,iBooster_ADAS,FCM,TPMS
 SG_ TBOX_CrtTi_Mth : 135|4@0+ (1,1) [1|12] "m"  FCM,IM,ESC_ADAS,EPS1_ADAS,VCU_ADAS,iBooster_ADAS,TPMS
 SG_ TBOX_CrtTi_Yr : 143|8@0+ (1,2015) [2015|2270] "y"  FCM,IM,EPS1_ADAS,ESC_ADAS,VCU_ADAS,iBooster_ADAS,TPMS
 SG_ TBOX_ZoneT : 151|7@0+ (15,-720) [-720|1185] "min"  EPS1_ADAS,FCM,IM,ESC_ADAS,VCU_ADAS,iBooster_ADAS,TPMS

BO_ 1015 SWS_01_AUDIO_CONT: 16 CGW_ADAS
 SG_ Microphone_SWS : 105|2@0+ (1,0) [0|3] ""  FCM
 SG_ Phone_SWS : 107|2@0+ (1,0) [0|0] ""  FCM
 SG_ Track_Rewind_SWS : 109|2@0+ (1,0) [0|3] ""  FCM
 SG_ Track_Forward_SWS : 111|2@0+ (1,0) [0|3] ""  FCM
 SG_ VolumeDown_SWS : 97|2@0+ (1,0) [0|3] ""  FCM
 SG_ ALIVE_SWS_AUDIO_CONT : 23|8@0+ (1,0) [0|255] ""  FCM
 SG_ CRC_SWS_AUDIO_CONT : 7|16@0+ (1,0) [0|65535] ""  FCM
 SG_ VolumeUp_SWS : 99|2@0+ (1,0) [0|3] ""  FCM
 SG_ OK_button_SWS : 101|2@0+ (1,0) [0|3] ""  FCM
 SG_ TOOT_SWS : 103|2@0+ (1,0) [0|3] ""  FCM

BO_ 1018 HU_03_SET_FUNC: 16 CGW_ADAS
 SG_ SET_TowMode : 127|2@0+ (1,0) [0|0] ""  TPMS
 SG_ ALIVE_HU_03 : 23|8@0+ (1,0) [0|255] ""  TPMS
 SG_ CRC_HU_03 : 7|16@0+ (1,0) [0|65535] ""  TPMS
 SG_ SteeringHeatingRequest : 117|2@0+ (1,0) [0|3] ""  TPMS
 SG_ SET_InteriorMotionSensing : 119|2@0+ (1,0) [0|3] ""  TPMS
 SG_ SET_RCP_Button : 113|2@0+ (1,0) [0|3] ""  TPMS
 SG_ DimmingVehicleBrightness : 111|8@0+ (1,0) [0|100] "%"  TPMS
 SG_ SET_DayTimeRunningLight : 103|2@0+ (1,0) [0|3] ""  TPMS
 SG_ SET_LeavingHomeSetting : 98|3@0+ (1,0) [0|7] "Bit"  TPMS
 SG_ SET_ComingHomeSetting : 101|3@0+ (1,0) [0|7] "Bit"  TPMS
 SG_ SET_ToDefaultFactorySetting : 115|2@0+ (1,0) [0|3] ""  TPMS
 SG_ SET_RemoteLockFeedback : 125|2@0+ (1,0) [0|3] ""  TPMS

CM_ BU_ TPMS "Tire Pressure Monitoring System";
CM_ BU_ iBooster_ADAS "iBooster";
CM_ BU_ IM "Inner Mirror";
CM_ BU_ ESC_ADAS "Electronic Stability Control";
CM_ BU_ EPS1_ADAS "Electronic Power Steering 1";
CM_ BU_ CGW_ADAS "Central Gateway";
CM_ BU_ VCU_ADAS "Vehicle Control Unit";
CM_ BU_ FCM "Front Camera Module";
CM_ SG_ 912 ALIVE_IM_02 "Alive Counter";
CM_ SG_ 912 CRC_IM_02 "DataID=0x008B. Checksum calculation accordig CAN Specification. Cyclic Redundancy Check";
CM_ SG_ 913 ALIVE_IM_03 "Alive Counter";
CM_ SG_ 913 CRC_IM_03 "DataID=0x008C. Checksum calculation accordig CAN Specification. Cyclic Redundancy Check";
CM_ BO_ 1986 "Intrusion Detection System";
CM_ BO_ 1982 "Intrusion Detection System";
CM_ BO_ 1973 "Intrusion Detection System";
CM_ BO_ 1906 "Intrusion Detection System";
CM_ BO_ 1902 "Intrusion Detection System";
CM_ BO_ 1893 "Intrusion Detection System";
CM_ SG_ 801 HU_DigitSpeed "calculated speed";
CM_ SG_ 801 ALIVE_HU_02 "Alive Counter";
CM_ SG_ 801 CRC_HU_02 "DataID=0x002E. Checksum calculation accordig CAN Specification. Cyclic Redundancy Check";
CM_ SG_ 1791 Diag_FuncReq_All_ECUs "Diagnostic physical request data to all ECUs";
CM_ SG_ 1775 Diag_FuncReq_All_CAN "Diagnostic physical request data to all CAN";
CM_ SG_ 789 TBOX_OTA_WakeupStatus "it is a status of wake up type(OTA), TBOX shall send this signal when wakeup network for OTA until vehicle sleep";
CM_ SG_ 789 ALIVE_TBOX_01 "Alive Counter";
CM_ SG_ 789 CRC_TBOX_01 "DataID=0x004F. Checksum calculation accordig CAN Specification. Cyclic Redundancy Check";
CM_ SG_ 789 TBOX_OTA_Status "TBOX send OTA status to all CANFD ECUs, OTA status is a statusmachine of OTA process";
CM_ BO_ 901 "SVSM";
CM_ SG_ 901 VCU_TowModRq "Tow mode request from VCU to HU";
CM_ SG_ 901 VCU_TowModSts "Status of Tow Mode";
CM_ SG_ 901 VCU_Dur_Lt_h "Duration lifetime h";
CM_ SG_ 901 VCU_Dur_Trip_h "Duration trip in h";
CM_ SG_ 901 VCU_Dur_Act_h "Duration since start h";
CM_ SG_ 901 VCU_Dur_Lt_min "Duration since lifetime min";
CM_ SG_ 901 VCU_Dur_Trip_min "Duration since start trip min";
CM_ SG_ 901 VCU_Dur_Act_min "Duration since start min
";
CM_ SG_ 901 VCU_AvgDrivRngRate "Average speed of last charge in km/h";
CM_ SG_ 901 ALIVE_VCU_13 "Alive Counter";
CM_ SG_ 901 CRC_VCU_13 "DataID=0x0068. Checksum calculation accordig CAN Specification. Cyclic Redundancy Check";
CM_ SG_ 901 VCU_ProdRollrModSts "Production Roller Mode Status";
CM_ SG_ 901 VCU_DynoModSts "Dyno Mode Status";
CM_ SG_ 901 VCU_AvgSpd_Lt "Average vehicle speed since lifetime km/h";
CM_ SG_ 901 VCU_AvgSpd_Trip "Average vehicle speed since trip km/h";
CM_ SG_ 901 VCU_AvgSpd_Act "Average vehicle speed since start km/h";
CM_ BO_ 1296 "Networkmanagement message";
CM_ BO_ 1295 "Networkmanagement message";
CM_ BO_ 1281 "Networkmanagement message";
CM_ BO_ 1311 "Networkmanagement message";
CM_ SG_ 1945 TPMS_Rx_CCP_Byte8 "CCP signal";
CM_ SG_ 1945 TPMS_Rx_CCP_Byte7 "CCP signal";
CM_ SG_ 1945 TPMS_Rx_CCP_Byte6 "CCP signal";
CM_ SG_ 1945 TPMS_Rx_CCP_Byte5 "CCP signal";
CM_ SG_ 1945 TPMS_Rx_CCP_Byte4 "CCP signal";
CM_ SG_ 1945 TPMS_Rx_CCP_Byte3 "CCP signal";
CM_ SG_ 1945 TPMS_Rx_CCP_Byte2 "CCP signal";
CM_ SG_ 1945 TPMS_Rx_CCP_TPCI "CCP signal";
CM_ SG_ 1992 TPMS_Tx_CCP_Byte6 "CCP signal";
CM_ SG_ 1992 TPMS_Tx_CCP_Byte8 "CCP signal";
CM_ SG_ 1992 TPMS_Tx_CCP_Byte7 "CCP signal";
CM_ SG_ 1992 TPMS_Tx_CCP_Byte5 "CCP signal";
CM_ SG_ 1992 TPMS_Tx_CCP_TPCI "CCP signal";
CM_ SG_ 1992 TPMS_Tx_CCP_Byte4 "CCP signal";
CM_ SG_ 1992 TPMS_Tx_CCP_Byte3 "CCP signal";
CM_ SG_ 1992 TPMS_Tx_CCP_Byte2 "CCP signal";
CM_ SG_ 528 TPM_MalfLmp_On_Rq "Request Tire Pressure Monitoring Malfunction Lamp";
CM_ SG_ 528 TPM_IndLmp_On_Rq "Request Tire Pressure Monitoring Indication Lamp";
CM_ SG_ 528 TPM_WarnDisp_Rq "Request Tire Pressure Monitioring Warning Display";
CM_ SG_ 528 TPM_Stat "Status Tire Pressure Monitoring";
CM_ SG_ 528 TPM_MsgDisp_Rq "Request tire pressure monitoring display";
CM_ SG_ 528 Press_Disp_Avl "Pressure display avaiable";
CM_ SG_ 528 TireStat_FR "Tire status front right";
CM_ SG_ 528 TireStat_RL "Tire status rear left";
CM_ SG_ 528 TireStat_RR "Tire status rear right";
CM_ SG_ 528 TireStat_FL "Tire status front left";
CM_ SG_ 528 TirePress_RR "Tire pressure rear right";
CM_ SG_ 528 TirePress_RL "Tire pressure rear left";
CM_ SG_ 528 TirePress_FR "Tire pressure front right";
CM_ SG_ 528 TirePress_FL "Tire pressure front left";
CM_ SG_ 528 Tire_Temp_WarnDisp_Rq "Request display warning tire temperature";
CM_ SG_ 528 Tire_Temp_Stat_RR "Status Tire Temperature Rear Right";
CM_ SG_ 528 Tire_Temp_Stat_RL "Status Tire Temperature Rear Left";
CM_ SG_ 528 Tire_Temp_Stat_FR "Status Tire Temperature Front Right";
CM_ SG_ 528 Tire_Temp_Stat_FL "Status Tire Temperature front left";
CM_ SG_ 528 RefPress_Rear "Reference Pressure rear";
CM_ SG_ 528 RefPress_Front "Reference Pressure front";
CM_ SG_ 528 TireTemp_RR "Tire Temperature Rear Right";
CM_ SG_ 528 TireTemp_RL "Tire Temperature Rear Left";
CM_ SG_ 528 TireTemp_FR "Tire Temperature Front Right";
CM_ SG_ 528 TireTemp_FL "Tire Temperature Front Left";
CM_ SG_ 528 ALIVE_TPMS_01 "Alive Counter";
CM_ SG_ 528 CRC_TPMS_01 "DataID=0x005D. Checksum calculation accordig CAN Specification. Cyclic Redundancy Check";
CM_ SG_ 640 ALIVE_HU_08 "Alive Counter";
CM_ SG_ 640 CRC_HU_08 "DataID=0x0034. Checksum calculation accordig CAN Specification. Cyclic Redundancy Check";
CM_ SG_ 128 VCU_AccPedalPos_Q "Qualifier for Accelerator Pedal Status";
CM_ SG_ 128 VCU_RECUPot_WhlTq_Q "Qualifier for Complete Vehicle Recuperation  Potential with power limits";
CM_ SG_ 128 VCU_RECUPot_WhlTq_RA_Q "Qualifier for Rear Axis Recuperation  Potential with power limits";
CM_ SG_ 128 VCU_RECUPot_WhlTq_FA_Q "Qualifier for Front Axis Recuperation  Potential with power limits";
CM_ SG_ 128 VCU_Target_WhlTq_Q "Qualifier for Target Wheel Torque for complete vehicle";
CM_ SG_ 128 VCU_Target_WhlTq_FA_Q "Qualifier for Target Front Wheel Torque Request";
CM_ SG_ 128 VCU_Target_WhlTq_RA_Q "Qualifier for Target Rear Wheel Torque Request";
CM_ SG_ 128 ALIVE_VCU_07 "Alive Counter";
CM_ SG_ 128 CRC_VCU_07 "DataID=0x0062. Checksum calculation accordig CAN Specification. Cyclic Redundancy Check";
CM_ SG_ 128 VCU_coordWhlTq_Q "Qualifier for Torque demand for Complete vehicle with Recuperation request from ESC";
CM_ SG_ 128 VCU_AccPedalPos_Virt "Virtual Accelerator pedal position";
CM_ SG_ 128 VCU_AccPedalPos "Accelerator pedal position";
CM_ SG_ 128 VCU_coordWhlTq "Torque demand for Complete vehicle with Recuperation request from ESC";
CM_ SG_ 128 VCU_RECUPot_WhlTq "Wheel based, combined FA + RA";
CM_ SG_ 128 VCU_RECUPot_WhlTq_RA "Wheel based";
CM_ SG_ 128 VCU_RECUPot_WhlTq_FA "Wheel based";
CM_ SG_ 128 VCU_Target_WhlTq "Coordinated Target Tq.on vehicle level (Driver + system). Before ESC request. Positiv value acccelerating; negativ values decelerating.";
CM_ SG_ 128 VCU_Target_WhlTq_FA "Coordinated Target Tq. Front axel (Driver + system + RECU). Before ESC stability Tq. request,  but with RECU request from ESC. Positiv value acccelerating; negativ values decelerating";
CM_ SG_ 128 VCU_Target_WhlTq_RA "Coordinated Target Tq. Rear axel (Driver + system + RECU). Before ESC request. Positiv value acccelerating; negativ values decelerating";
CM_ SG_ 832 TCC_ByPassFlap_error "By Pass flap error";
CM_ SG_ 832 TCC_RecircFlap_error "Recirculation flap error";
CM_ SG_ 832 TCC_ModeFlap_error "Mode Flap error";
CM_ SG_ 832 TCC_Blower_Error "HVAC Blower error";
CM_ SG_ 832 TCC_HVAC_AirDistributionMode "HVAC flap position (air distribution mode)";
CM_ SG_ 832 TCC_HV_Compressor_Availability "HV-compressor availability status";
CM_ SG_ 832 TCC_HV_Compressor_error "HV-compressor error";
CM_ SG_ 832 TCC_HV_Compressor_power "HV-compressor power";
CM_ SG_ 832 TCC_HV_PTC_HVAC_Availability "HVAC PTC availability status";
CM_ SG_ 832 TCC_HV_PTC_HVAC_error "HVAC PTC error";
CM_ SG_ 832 TCC_HV_PTC_HVAC_power "HVAC PTC power total";
CM_ SG_ 832 TCC_AGM_error "Active Grill Shutter (AGS) error";
CM_ SG_ 832 TCC_EFAN_error "Cooling fan (EFAN) error";
CM_ SG_ 832 TCC_HV_PTC_Battery_Availability "Battery HPTC availability status";
CM_ SG_ 832 TCC_HV_PTC_Battery_error "Battery HPTC error";
CM_ SG_ 832 TCC_HV_PTC_Battery_power "Battery HPTC power";
CM_ SG_ 832 TCC_WAPU_EDU_Error "EDU waterpump error";
CM_ SG_ 832 TCC_RSV_EDU_Error "EDU RSV error";
CM_ SG_ 832 TCC_CoolantTempEDURear_IN_error "EDU rear coolant inlet temperature sensor error";
CM_ SG_ 832 TCC_CoolantTempEDUFront_IN_error "EDU front coolant inlet temperature sensor error";
CM_ SG_ 832 TCC_EDU_Cooling_error "Error status of EDU cooling";
CM_ SG_ 832 TCC_CoolantTempIPU_IN "Coolant inlet temperature at IPU inlet";
CM_ SG_ 832 TCC_STAT_Defrost "Status feedback of Defrost function";
CM_ SG_ 832 TCC_STAT_Sync "Status feedback of SYNC function";
CM_ SG_ 832 TCC_STAT_Recirc "Status feedback of Recirculation function";
CM_ SG_ 832 TCC_STAT_AC "Status feedback of AC function";
CM_ SG_ 832 TCC_STAT_AUTO "Status feedback of AUTO function";
CM_ SG_ 832 TCC_BlowerLevelManual "HVAC blower level current set";
CM_ SG_ 832 TCC_RightZoneSetTemp "Right zone temperature setting for cabin conditioning";
CM_ SG_ 832 TCC_LeftZoneSetTemp "Left zone temperature setting for cabin conditioning";
CM_ SG_ 832 TCC_CoolantTempIPU_IN_error "Coolant inlet temperature at IPU inlet error";
CM_ SG_ 832 TCC_CabinTemp_Q "Qualifier for cabin temperature sensor";
CM_ SG_ 832 TCC_CabinTemp "Cabin temperature inside the vehicle";
CM_ SG_ 832 TCC_AmbientTemp "Ambient temperature outside the vehicle";
CM_ SG_ 832 TCC_AmbientTempRaw "Ambient Temperature Raw";
CM_ SG_ 832 CRC_TCC_02 "DataID=0x0058. Checksum calculation accordig CAN Specification. Cyclic Redundancy Check";
CM_ SG_ 832 ALIVE_TCC_02 "Alive Counter";
CM_ SG_ 832 TCC_RSV_EDU_Position "EDU RSV position ";
CM_ SG_ 832 TCC_CoolantFlow_EDURear "EDU rear coolant volume flow";
CM_ SG_ 832 TCC_CoolantFlow_EDUFront "EDU front coolant volume flow";
CM_ SG_ 832 TCC_WAPU_EDU "EDU waterpump speed";
CM_ SG_ 832 TCC_CoolantTempEDURear_IN "EDU rear coolant inlet temperature";
CM_ SG_ 832 TCC_CoolantTempEDUFront_IN "EDU front coolant inlet temperature";
CM_ SG_ 832 TCC_AmbientTemp_Q "Qualifier for ambient temperature sensor ";
CM_ SG_ 832 TCC_STAT_MaxAC "Status feedback of MAX AC function";
CM_ BO_ 409 "Longitudinal, lateral acceleration, yaw rate sensor";
CM_ SG_ 409 ESC_VehLatInc_Q "Qualifier Vehicle Inclination Lateral";
CM_ SG_ 409 ESC_VehLatInc "Vehicle Inclination Lateral";
CM_ SG_ 409 SSecOC_MAC_ESC_02 "Short SecOC MAC signal byte 0 on CAN";
CM_ SG_ 409 SSecOC_Fresh_ESC_02 "Short SecOC Fresh signal byte 0 on CAN";
CM_ SG_ 409 ESC_VehLgtInc_Q "Qualifier Vehicle Inclination Longitudinal";
CM_ SG_ 409 ESC_VehLgtInc "Vehicle Inclination Longitudinal";
CM_ SG_ 409 ESC_LatAcc_Q "Extended status qualifier for the signal lateral acceleration";
CM_ SG_ 409 ESC_LatAcc "Lateral acceleration in the center of gravity.
A positive longitudinal acceleration acts in the vehicle Y direction. 
The lateral acceleration of the vehicle is measured by a lateral acceleration sensor.";
CM_ SG_ 409 ESC_LgtAcc_Q "Extended status qualifier for the signal longitudinal acceleration";
CM_ SG_ 409 ESC_LgtAcc "Longitudinal acceleration in the center of gravity.
A positive longitudinal acceleration acts in the vehicle X direction. 
The longitudinal acceleration of the vehicle is measured by a longitudinal acceleration sensor.";
CM_ SG_ 409 ALIVE_ESC_02 "Alive Counter";
CM_ SG_ 409 CRC_ESC_02 "DataID=0x0026. Checksum calculation accordig CAN Specification. Cyclic Redundancy Check";
CM_ SG_ 409 ESC_YawRt_Q "Qualifier yaw rate";
CM_ SG_ 409 ESC_YawRt "yaw rate, invalid Value = FFFFh";
CM_ BO_ 299 "ESC Torques";
CM_ SG_ 299 ESC_IntvAct_Q "Qualifier ESC Intervention active";
CM_ SG_ 299 ESC_IntvAct "ESC Intervention active";
CM_ SG_ 299 ESC_DTC_IntvAct_Q "Qualifier DTC Control Intervention active";
CM_ SG_ 299 ESC_DTC_IntvAct "DTC Control Intervention active";
CM_ SG_ 299 ESC_TCS_IntvAct_Q "Qualifier TCS Control Intervention active";
CM_ SG_ 299 SSecOC_MAC_ESC_04 "Short SecOC MAC signal byte 0 on CAN";
CM_ SG_ 299 SSecOC_Fresh_ESC_04 "Short SecOC Fresh signal byte 0 on CAN";
CM_ SG_ 299 ESC_MotRotSpdMinLim_RA_Q "Qualifier min. target speed EDU Rear Axle";
CM_ SG_ 299 ESC_MotRotSpdMinLim_FA_Q "Qualifier min. target speed EDU Front Axle";
CM_ SG_ 299 ESC_MotRotSpdMinLim_RA_Sts "min. target speed EDU Rear Axle release";
CM_ SG_ 299 ESC_MotRotSpdMinLim_FA_Sts "min. target speed EDU Front Axle release";
CM_ SG_ 299 ESC_MotRotSpdMinLim_RA "min. target speed EDU Rear Axle";
CM_ SG_ 299 ESC_MotRotSpdMinLim_FA "min. target speed EDU Front Axle";
CM_ SG_ 299 ESC_RecuWhlTqReq "Recuperation wheel torque request";
CM_ SG_ 299 ESC_StabWhlTq_RA "Stability Control Wheel Torque Request Rear Axle (TCS/DTC)";
CM_ SG_ 299 ESC_StabWhlTq_FA "Stability Control Wheel Torque Request Front Axle (TCS/DTC)";
CM_ SG_ 299 ESC_MotRotSpdMaxLim_FA "max. target speed EDU Front Axle";
CM_ SG_ 299 ESC_MotRotSpdMaxLim_RA "max. target speed EDU Rear Axle";
CM_ SG_ 299 ESC_TCS_IntvAct "TCS Control Intervention active";
CM_ SG_ 299 ESC_MotRotSpdMaxLim_FA_Sts "max. target speed EDU Front Axle release";
CM_ SG_ 299 ESC_MotRotSpdMaxLim_RA_Sts "max. target speed EDU Rear Axle release";
CM_ SG_ 299 ESC_RecuWhlTqReq_Q "Qualifier Recuperation wheel torque request";
CM_ SG_ 299 ESC_StabWhlTq_FA_Q "Qualifier Stability Control Wheel Torque Request Front Axle (TCS/DTC)";
CM_ SG_ 299 ESC_RecuWhlTqReq_Sts "Recuperation Request active";
CM_ SG_ 299 ESC_StabWhlTq_FA_Sts "Stability Control Intervention active Front Axle";
CM_ SG_ 299 ESC_StabWhlTq_RA_Q "Qualifier Stability Control Wheel Torque Request Rear Axle (TCS/DTC)";
CM_ SG_ 299 ESC_StabWhlTq_RA_Sts "Stability Control Intervention active Rear Axle";
CM_ SG_ 299 ESC_MotRotSpdMaxLim_FA_Q "Qualifier max. target speed EDU Front Axle";
CM_ SG_ 299 ESC_MotRotSpdMaxLim_RA_Q "Qualifier max. target speed EDU Rear Axle";
CM_ SG_ 299 ESC_CFA_Min "Coefficient Front Axle Minimum, 1=full torque Front, 0= full torque Rear";
CM_ SG_ 299 ESC_DrvTotBrkTqReq_Q "Extended status qualifier for signal Actual_Braking_ torque_sum.";
CM_ SG_ 299 ESC_TotBrkTqReq_Q "Extended status qualifier for signal Actual_Braking_ torque_sum.
";
CM_ SG_ 299 ESC_CFA_Max "Coefficient Front Axle Maximum, 1=full torque Front, 0= full torque Rear";
CM_ SG_ 299 ESC_DrvTotBrkTqReq "Current wheel-related braking torque that the driver tries to apply via the brake pedal.
When the brake pedal is actuated, a negative value is transmitted ";
CM_ SG_ 299 ESC_TotBrkTqReq "Current wheel-related total friction braking torque. A negative braking torque corresponds to a frictional force against the vehicle movement.";
CM_ SG_ 299 ALIVE_ESC_04 "Alive Counter";
CM_ SG_ 299 CRC_ESC_04 "DataID=0x0028. Checksum calculation accordig CAN Specification. Cyclic Redundancy Check";
CM_ BO_ 152 "Status Functions";
CM_ SG_ 152 SSecOC_MAC_ESC_03 "Short SecOC MAC signal byte 0 on CAN";
CM_ SG_ 152 SSecOC_Fresh_ESC_03 "Short SecOC Fresh signal byte 0 on CAN";
CM_ SG_ 152 ESC_ActvIndcn_AEB "Indication for AEB braking readiness of ESC";
CM_ SG_ 152 ESC_FltIndcn_AEB "Indication for AEB braking readiness of ESC";
CM_ SG_ 152 ESC_BrkDiscTemp "Model Based brake disc Temperature";
CM_ SG_ 152 ESC_ABS_IntvAct "ABS intervention active";
CM_ SG_ 152 ESC_SysSts "Overall ESC System Status";
CM_ SG_ 152 ESC_EssReq "Emergency Braking Signal Request from ESC";
CM_ SG_ 152 ESC_EssReq_Q "Qualifier Emergency Braking Signal Request from ESC";
CM_ SG_ 152 ESC_BrkLiReq_Q "Qualifier for Brake lights on requested by EPBi";
CM_ SG_ 152 ESC_BrkLiReq "Brake lights on requested by EPBi";
CM_ SG_ 152 ESC_MstCylP_Q "qualifier Pressure of the braking system (Pressure of the master cylinder).Invalid value = FFFFh";
CM_ SG_ 152 ESC_MstCylP "Pressure of the braking system (Pressure of the master cylinder).Invalid value = FFFFh";
CM_ SG_ 152 ESC_BTC_IntvAct_Q "Qualifier BTC intervention active";
CM_ SG_ 152 ESC_SystSts_EPB "Status electric park brake";
CM_ SG_ 152 ESC_AVH_Actv "Autohold active";
CM_ SG_ 152 ESC_CDP_Actv "Controlled deceleration via Parking Brake Button active";
CM_ SG_ 152 ESC_EPB_SwitchPosition "EPB switch position";
CM_ SG_ 152 ESC_EPB_SwitchPosition_Q "qualifier EPB switch position";
CM_ SG_ 152 ESC_BTC_IntvAct "BTC intervention active";
CM_ SG_ 152 ESC_VDC_IntvAct_Q "Qualifier VDC Intervention active ESC_VDC_IntvAct  (VDC incl. EUC + RMF + TSM)";
CM_ SG_ 152 ESC_ABS_IntvAct_Q "Qualifier ABS Intervention active ESC_ABS_IntvAct";
CM_ SG_ 152 ESC_DrvPressBrkPedl "driver is applying the brake pedal or not";
CM_ SG_ 152 ESC_SpecialMode "ESC Special mode";
CM_ SG_ 152 ESC_VDC_IntvAct "VDC intervention active (VDC incl. EUC + RMF + TSM)";
CM_ SG_ 152 ESC_Mode "Shows Active ESC Mode
";
CM_ SG_ 152 ESC_SystSts_HDC "Hill Descent Control Status";
CM_ SG_ 152 ESC_SystSts_AVH "Auto Vehicle Hold Status";
CM_ SG_ 152 ALIVE_ESC_03 "Alive Counter";
CM_ SG_ 152 CRC_ESC_03 "DataID=0x0027. Checksum calculation accordig CAN Specification. Cyclic Redundancy Check";
CM_ SG_ 787 ALIVE_HU_01 "Alive Counter";
CM_ SG_ 787 CRC_HU_01 "DataID=0x002D. Checksum calculation accordig CAN Specification. Cyclic Redundancy Check";
CM_ SG_ 787 HU_OTA_UpdateConfirm "HU send the input confirmation of updating from user to all CANFD ECUs";
CM_ SG_ 786 ALIVE_ESC_05 "Alive Counter";
CM_ SG_ 786 CRC_ESC_05 "DataID=0x0029. Checksum calculation accordig CAN Specification. Cyclic Redundancy Check";
CM_ SG_ 786 ESC_OTA_inhib_FB "ESC execute the inhibition and send the Feedback to all CANFD ECUs";
CM_ SG_ 386 SSecOC_MAC_FCM_02 "Short SecOC MAC signal byte 0 on CAN";
CM_ SG_ 386 SSecOC_Fresh_FCM_02 "Short SecOC Fresh signal byte 0 on CAN";
CM_ SG_ 386 CRC_FCM_02 "DataID=0x002B. Checksum calculation accordig CAN Specification. Cyclic Redundancy Check";
CM_ SG_ 386 ALIVE_FCM_02 "Alive Counter";
CM_ SG_ 386 FCM_LatVelocityLane "Lateral velocity in reference to the host lane";
CM_ SG_ 386 FCM_LonVelocityLane "Longitudinal velocity in reference to the host lane";
CM_ SG_ 386 FCM_LatClearanceRi "Lateral clearance to the left Right marking";
CM_ SG_ 386 FCM_LatClearanceLe "Lateral clearance to the left lane marking";
CM_ SG_ 386 FCM_HostLaneWidth "Width of host lane";
CM_ SG_ 386 FCM_LaneMarkingWidth "Width of lane marking";
CM_ SG_ 386 FCM_LaneMarkingColor "Color of lane marking";
CM_ SG_ 386 FCM_LaneMarkingTyp "Type of lane marking";
CM_ SG_ 386 FCM_LaneMarkingSts "Status of lane marking";
CM_ SG_ 386 FCM_DRA_AESA_ECALL_Req "The signal will be used to trigger the ECALL functionality once the AESA control is done and the vehicle is brought to stop.";
CM_ SG_ 357 FCM_LA_sens_Feed "Csaba --> can we remove it?";
CM_ SG_ 357 FCM_ELKA_ON_Feed "Vanessa --> can we remove it?";
CM_ SG_ 357 FCM_LA_Mode_Feed "need to be checked with VALEO";
CM_ SG_ 357 FCM_HWA_ICON_Feed "HighWayAssist icon signal für HU will be removed, because Status includes this state already";
CM_ SG_ 357 FCM_DRA_Sts "DrivingAssist status";
CM_ SG_ 357 FCM_AESA_Sts "AutomaticEmergencyStoppingAssist status feedback to HU";
CM_ SG_ 357 SSecOC_MAC_FCM_03 "Short SecOC MAC signal byte 0 on CAN";
CM_ SG_ 357 SSecOC_Fresh_FCM_03 "Short SecOC Fresh signal byte 0 on CAN";
CM_ SG_ 357 FCM_PDC_SettingSts "ParkDistanceControl settings feedback to HU";
CM_ SG_ 357 FCM_BSW_Sts "BlindSpotWarning (warning/no warning) status feedback to HU (is not relevant) will be removed";
CM_ SG_ 357 FCM_DRA_DstSetgsSts "DrivingAssist DistanceSettings status feedback to HU";
CM_ SG_ 357 FCM_DRA_BehaviorSts "DrivingAssist DistanceSettings behavior status feedback to HU";
CM_ SG_ 357 FCM_ASA_RoadCondSts "DrivingAssist DistanceSettings road condition status feedback to HU";
CM_ SG_ 357 FCM_ASA_LegalLimSts "DrivingAssist DistanceSettings road condition status feedback to HU";
CM_ SG_ 357 FCM_ELK_Sts "EmergencyLaneKeeping status feedback to HU";
CM_ SG_ 357 FCM_LDW_Sts "LaneDepartureWarning status feedback to HU";
CM_ SG_ 357 FCM_ASA_SpdChgWarnSts "AutomaticSpeedAssist overspeed warning status feedback to HU";
CM_ SG_ 357 FCM_ASA_OverSpdWarnSts "AutomaticSpeedAssist speed limit change warning status feedback to HU";
CM_ SG_ 357 FCM_DCA_Sts "DriverConditionAssist status feedback signal will be removed";
CM_ SG_ 357 FCM_AEB_Sts "AutomaticEmergencyBrankingAssist deceleration status feedback signal … will be removed";
CM_ SG_ 357 FCM_FCW_Snvty "ForwardCollisionWarning sensitivity setting feedback to HU";
CM_ SG_ 357 FCM_FCW_Sts "ForwardCollisionWarning status feedback signal will be removed";
CM_ SG_ 357 ALIVE_FCM_03 "Alive Counter";
CM_ SG_ 357 CRC_FCM_03 "DataID=0x0003. Checksum calculation accordig CAN Specification. Cyclic Redundancy Check";
CM_ SG_ 357 FCM_DRA_AESA_Status "Signal indicating the working status of AESA (automatic emergency stop assist) system.";
CM_ SG_ 357 FCM_HOW_Sts "HandsOffWarning status feedback to HU";
CM_ SG_ 357 FCM_LCA_Sts "LaneCenteringAssist status feedback to HU";
CM_ SG_ 357 FCM_VehPosiLane "The position of vehicle in lanes --> Rucai";
CM_ SG_ 357 FCM_TakeoverWarnSts "TakeOverWarning status feedback to HU";
CM_ SG_ 357 FCM_ASA_Sts "AutomaticSpeedAssist status feedback to HU";
CM_ SG_ 357 FCM_DCA_Warn "DriverConditionAssist warning signal to HU will be removed";
CM_ SG_ 357 FCM_DCA_Sts2 "DriverConditionAssist status feedback signal to HU will be removed";
CM_ SG_ 352 HU_Veh_DoorLock "Door lock signal (HMI simulated)";
CM_ SG_ 352 HU_Veh_GearPosition "Gear position (HMI simulated)";
CM_ SG_ 352 HU_Veh_TurnLed "Turning led signal (HMI simulated)";
CM_ SG_ 352 HU_VehSteerWhlAngle "Steering wheel angle (HMI simulated)";
CM_ SG_ 352 HU_Veh_SteerAngle_Symbol "Steering wheel angle symbol (HMI simulated)";
CM_ SG_ 352 HU_Veh_Speed "Vehicle speed (HMI simulated)";
CM_ SG_ 352 HU_FunctSelect "signal for function selection in HU (ACC/CC/DistanceControl/SpeedLimiter)";
CM_ SG_ 352 HU_CruiseControlSts "Cruise Control Status";
CM_ SG_ 352 HU_PDCPopupSts "the signal for the pop up status of PDC / RVC";
CM_ SG_ 352 SET_PDCSoftButton_Front "to switch front park assist under Vehicle, comfort features setting";
CM_ SG_ 352 MILE_KM "Mileage information, value of total distance";
CM_ SG_ 352 ALIVE_HU_05 "Alive Counter";
CM_ SG_ 352 CRC_HU_05 "DataID=0x0031. Checksum calculation accordig CAN Specification. Cyclic Redundancy Check";
CM_ SG_ 352 HU_ELK_AcoustWarnSetg "acoustic warning setting for ELK function from HU";
CM_ SG_ 352 RNG "The signal / parameter indicates the expected range (on-board computer function).";
CM_ SG_ 352 SET_PDCSoftButton "a signal for two softbuttons to open or close the pop up under offroad, attitude settings - moved to HU - to be deleted";
CM_ BO_ 400 "Cruise Control message from Steering Wheel Switchtes
charging options: if only needed by VCU, could be combined with Cruise Control";
CM_ SG_ 400 ALIVE_SWS_02 "Alive Counter";
CM_ SG_ 400 CRC_SWS_02 "DataID=0x004D. Checksum calculation accordig CAN Specification. Cyclic Redundancy Check";
CM_ BO_ 1055 "Warning message to HU";
CM_ SG_ 1055 SSecOC_MAC_iBoosterWarnMsg "Short SecOC MAC signal byte 0 on CAN";
CM_ SG_ 1055 SSecOC_Fresh_iBoosterWarnMsg "Short SecOC Fresh signal byte 0 on CAN";
CM_ SG_ 1055 WarningMessageID_iBooster "The value (0-65534) defines the warning message ID (details see warning message cataloge). ";
CM_ SG_ 1055 BitBlinking_iBooster "This parameter defines the blinking frequency of a telltale";
CM_ SG_ 1055 BitStatus_iBooster "The status defines if a warning message is set or reset";
CM_ SG_ 1055 ALIVE_WarnMsg_iBooster "Alive Counter";
CM_ SG_ 1055 CRC_WarnMsg_iBooster "DataID=0x007F. Checksum calculation accordig CAN Specification. Cyclic Redundancy Check";
CM_ BO_ 1049 "Warning message to HU";
CM_ SG_ 1049 WarningMessageID_TPMS "The value (0-65534) defines the warning message ID (details see warning message cataloge). ";
CM_ SG_ 1049 BitBlinking_TPMS "This parameter defines the blinking frequency of a telltale";
CM_ SG_ 1049 BitStatus_TPMS "The status defines if a warning message is set or reset";
CM_ SG_ 1049 CRC_WarnMsg_TPMS "DataID=0x0089. Checksum calculation accordig CAN Specification. Cyclic Redundancy Check";
CM_ SG_ 1049 ALIVE_WarnMsg_TPMS "Alive Counter";
CM_ SG_ 2564485407 Diag_Resp_iBooster "Diagnostic physical response data from iBooster";
CM_ SG_ 2564485401 Diag_Resp_TPMS "Diagnostic physical response data from TPMS";
CM_ SG_ 2564431857 Diag_PhyReq_iBooster "Diagnostic physical request data to iBooster";
CM_ SG_ 2564430321 Diag_PhyReq_TPMS "Diagnostic physical request data to TPMS";
CM_ BO_ 263 "status, mode of wiper";
CM_ SG_ 263 ALIVE_BCM_11 "Alive Counter";
CM_ SG_ 263 STAT_WiperSensitivityInterval "Mulifunction switch wiper
Status Intervallmode button";
CM_ SG_ 263 CRC_BCM_11 "DataID=0x0011. Checksum calculation accordig CAN Specification. Cyclic Redundancy Check";
CM_ SG_ 263 STAT_WasherRear "Multifunction switch wiper
Status WashMode Rear button";
CM_ SG_ 263 STAT_WiperRear "Multifunction switch wiper
Status Rear Wiper intermediate button";
CM_ SG_ 263 STAT_WasherFront "Multifunction switch wiper
Status WashMode Front button";
CM_ SG_ 263 STAT_WiperFront "Information if the wiping speed high is activated. (Button)
Invalid value = 7";
CM_ BO_ 265 "General switch status contriled by BCM  /Body";
CM_ SG_ 265 STAT_WadingModeButton "Wading Mode Button Status";
CM_ SG_ 265 STAT_BLTS_BCM_Mon "Monitoring function for BLTS";
CM_ SG_ 265 ALIVE_BCM_08 "Alive Counter";
CM_ SG_ 265 CRC_BCM_08 "DataID=0x000E. Checksum calculation accordig CAN Specification. Cyclic Redundancy Check";
CM_ SG_ 265 STAT_BrakeLightSwitchBCM "Raw Value Brake Light switch BCM pressed
ASIL B on Body CAN";
CM_ SG_ 265 STAT_Horn "Status switch horn";
CM_ SG_ 265 STAT_WorkingLight_Button "Status WorkingLight Button";
CM_ SG_ 265 STAT_HazardWarn "Hazard Warning switch activation";
CM_ BO_ 262 "This message includes the status information of the different light systems, like the status of the indication lamps and high-/lowbeam.";
CM_ SG_ 262 STAT_ReadingLight_RR "Current state of reading light";
CM_ SG_ 262 STAT_ActiveReadLightPA "status for active reading light passenger side";
CM_ SG_ 262 STAT_ActiveReadLightDR "status for active reading light driver side";
CM_ SG_ 262 STAT_ActiveInteriorLight "status for active interior light";
CM_ SG_ 262 STAT_ActiveAmbientLight "status for active ambiente light";
CM_ SG_ 262 STAT_HeadlightTurnOnReminder "Request for headlight turn on signal";
CM_ SG_ 262 STAT_HazardWarningLight "State of the hazard warning light function.";
CM_ SG_ 262 STAT_Emergency_BrakeLight "State of the emergency BRAKE LIGHT function";
CM_ SG_ 262 RLS_VoltageError "Voltage error";
CM_ SG_ 262 RLS_TempSensorValue "Windscreen temperature";
CM_ SG_ 262 RLS_TempDewPoint "Dew Point";
CM_ SG_ 262 STAT_ReadingLight_RL "Current state of reading light ";
CM_ SG_ 262 STAT_HeadlightReminder "Follow Me Home Light Status

";
CM_ SG_ 262 RLS_Solar_Right "Solar value right";
CM_ SG_ 262 RLS_Solar_Left "Solar value left";
CM_ SG_ 262 RLS_RS_FAULT "RS Fault";
CM_ SG_ 262 RLS_Response_error "Response error";
CM_ SG_ 262 RLS_Rainfall "Rainfall classification";
CM_ SG_ 262 RLS_LiSwitchReason "Light switch reason";
CM_ SG_ 262 RLS_HumidSensorValue "Relative humidity on inner surface of windscreen";
CM_ SG_ 262 RLS_Humid_Temp_Error "Humid_Temp error";
CM_ SG_ 262 RLS_FWBrightness "Forward brightness";
CM_ SG_ 262 RLS_COMMFAULT "Communication error";
CM_ SG_ 262 RLS_AutoPanel "Auto Panel Dim Request";
CM_ SG_ 262 RLS_AmbBrightness "Ambient brightness";
CM_ SG_ 262 BCM_BSM_OTM_Right_LED_State "State of the LCDAS LED in the right outer mirror. LED control is requested by FCM.";
CM_ SG_ 262 BCM_BSM_OTM_Left_LED_State "State of the LCDAS LED in the left outer mirror. LED control is requested by FCM.";
CM_ SG_ 262 STAT_LowBeam "LowBeam status.
Invalid value = 3
";
CM_ SG_ 262 STAT_PositionLight "Position Ligth status.
Invalid value = 3
";
CM_ SG_ 262 STAT_BrakeLight "Debug message for validation Status of stop light";
CM_ SG_ 262 STAT_LightActivation "Status of Autolight ";
CM_ SG_ 262 STAT_DRL "Status Day Time running Light";
CM_ SG_ 262 STAT_TurnIndicators "This signal represents the constant blinking status of the turn indicators.
Invalid value  = 7";
CM_ SG_ 262 STAT_ReverseLight "Status if the reverse light is activated ";
CM_ SG_ 262 STAT_InteriorLight "Status for functional illumination in the interior light switch button.
Invalid = 3";
CM_ SG_ 262 STAT_FogLampRear "Fog lamp Rear Status";
CM_ SG_ 262 ALIVE_BCM_07 "Alive Counter";
CM_ SG_ 262 CRC_BCM_07 "DataID=0x000D. Checksum calculation accordig CAN Specification. Cyclic Redundancy Check";
CM_ SG_ 262 STAT_HighBeam "This is the status signal for the static warning lamp in the instrument cluster, if highbeam is activated or deactivated.
Invalid value = 3";
CM_ BO_ 324 "ESC_Velospeed - Vehicle speed, wheele speed, milage";
CM_ SG_ 324 ESC_VehSpdLat_Q "Qualifier Lateral Vehicle Speed";
CM_ SG_ 324 ESC_VehSpdLat "Lateral Vehicle Speed (qualifier Lateral Vehicle Speed)";
CM_ SG_ 324 SSecOC_MAC_ESC_01 "Short SecOC MAC signal byte 0 on CAN";
CM_ SG_ 324 SSecOC_Fresh_ESC_01 "Short SecOC Fresh signal byte 0 on CAN";
CM_ SG_ 324 ESC_WhlTck_RR_Q "Qualifier Wheel Tick RR";
CM_ SG_ 324 ESC_WhlTck_RL_Q "Qualifier Wheel Tick RL";
CM_ SG_ 324 ESC_WhlTck_FR_Q "Qualifier Wheel Tick FR";
CM_ SG_ 324 ESC_WhlTck_RR "Wheel tick (pulse counter) of rear right wheel.
A tick is counted every rising and falling edge of teeth.
The ticks are accumulated. No ticks must be lost or added.";
CM_ SG_ 324 ESC_WhlTck_RL "Wheel tick (pulse counter) of rear left wheel.
A tick is counted every rising and falling edge of teeth.
The ticks are accumulated. No ticks must be lost or added.";
CM_ SG_ 324 ESC_WhlTck_FR "Wheel tick (pulse counter) of front right wheel.
A tick is counted every rising and falling edge of teeth.
The ticks are accumulated. No ticks must be lost or added.";
CM_ SG_ 324 ESC_WhlTck_FL_Q "Qualifier Wheel Tick FL";
CM_ SG_ 324 ESC_WhlTck_FL "Wheel tick (pulse counter) of front left wheel.
A tick is counted every rising and falling edge of teeth.
The ticks are accumulated. No ticks must be lost or added.";
CM_ SG_ 324 ESC_WhlSpd_RR_Q "Qualifier wheel speed rear right";
CM_ SG_ 324 ESC_WhlSpd_RR "Measured speed of the rear right single wheel.";
CM_ SG_ 324 ESC_WhlSpd_RL_Q "Qualifier wheel speed rear left";
CM_ SG_ 324 ESC_WhlSpd_RL "Measured speed of the rear left single wheel.";
CM_ SG_ 324 ESC_WhlSpd_FR_Q "Qualifier for wheel speed front right";
CM_ SG_ 324 ESC_WhlSpd_FR "Measured speed of the front right single wheel.";
CM_ SG_ 324 ESC_WhlSpd_FL_Q "Qualifier for wheel speed front left";
CM_ SG_ 324 ESC_WhlSpd_FL "Measured speed of the front left single wheel.";
CM_ SG_ 324 ESC_VehDrvCond_Q "Qualifier Driving Condition Detected: Stationary, Moving Forwards, Moving Backwards";
CM_ SG_ 324 ESC_DrivDist_Q "Qualifier ESC_Mileage: 1 cm / Digit;  invalid value FFFFh, input for Mileage calc, in cm, reset each clamp change";
CM_ SG_ 324 ALIVE_ESC_01 "Alive Counter";
CM_ SG_ 324 CRC_ESC_01 "DataID=0x0025. Checksum calculation accordig CAN Specification. Cyclic Redundancy Check";
CM_ SG_ 324 ESC_DrivDist "ESC_Mileage: 1 cm / Digit;  invalid value FFFFh, input for Mileage calc, in cm, reset each clamp change";
CM_ SG_ 324 ESC_VehDrvCond "Driving Condition Detected: Driving condition Values 4,5,6 describe if the axle are on the chassis dynamometer roller dynamometer test bench;
Value 3 described when the recognition of the moving direction isn't recognised.";
CM_ SG_ 324 ESC_VehSpd_Q "Qualifier Vehicle Speed";
CM_ SG_ 324 ESC_VehSpd "Vehicle Speed";
CM_ BO_ 267 "Trailer Module Status";
CM_ SG_ 267 SSecOC_MAC_TM_01 "Short SecOC MAC signal byte 0 on CAN";
CM_ SG_ 267 SSecOC_Fresh_TM_01 "Short SecOC Fresh signal byte 0 on CAN";
CM_ SG_ 267 ALIVE_TM_01 "Alive Counter";
CM_ SG_ 267 CRC_TM_01 "DataID=0x005C. Checksum calculation accordig CAN Specification. Cyclic Redundancy Check";
CM_ SG_ 267 ST_TRAI "This parameter/signal indicates whether a trailer is actually connected or not.";
CM_ SG_ 267 STAT_BrakeLight_TM "Debug message for validation Status of stop light";
CM_ SG_ 267 STAT_TurnIndicators_TM "This signal represents the constant blinking status of the turn indicators.
Invalid value  = 7";
CM_ SG_ 267 STAT_FogLampRear_TM "Fog lamp Rear Status";
CM_ SG_ 267 STAT_PositionLight_TM "Position Ligth status.
Invalid value = 3
";
CM_ SG_ 267 STAT_ReverseLight_TM "Fog lamp Rear Status";
CM_ BO_ 171 "Post Crash reaction";
CM_ SG_ 171 SSecOC_MAC_ACM_01 "Short SecOC MAC signal byte 0 on CAN";
CM_ SG_ 171 ALIVE_ACM_01 "Alive Counter";
CM_ SG_ 171 CRC_ACM_01 "DataID=0x0001. Checksum calculation accordig CAN Specification. Cyclic Redundancy Check";
CM_ SG_ 171 ST_CRASH_TYPE "If a crash is detected, the ACM will provide the crash severitys (defined by calibration).";
CM_ SG_ 171 ST_CRASH "If a crash is detected, the ACM provides this information on the CAN. Crash severity is defined during calibration.";
CM_ SG_ 171 SSecOC_Fresh_ACM_01 "Short SecOC Fresh signal byte 0 on CAN";
CM_ BO_ 760 "Time and Date information";
CM_ SG_ 760 ALIVE_TBOX_02 "Alive Counter";
CM_ SG_ 760 CRC_TBOX_02 "DataID=0x0050. Checksum calculation accordig CAN Specification. Cyclic Redundancy Check";
CM_ SG_ 760 TBOX_CrtTi_Hr "Current hour information
";
CM_ SG_ 760 TBOX_CrtTi_Mins "Current minutes information
";
CM_ SG_ 760 TBOX_CrtTi_Sec "Current seconds information";
CM_ SG_ 760 TBOX_CrtTi_Day "Current Day information.";
CM_ SG_ 760 TBOX_CrtTi_Mth "Current month information";
CM_ SG_ 760 TBOX_CrtTi_Yr "Current year information";
CM_ SG_ 760 TBOX_ZoneT "Summer or Winter time information

";
CM_ BO_ 1015 "Board computer, media button for IPC  from SCM";
CM_ SG_ 1015 VolumeDown_SWS "Status Button Decrease Audio Volume";
CM_ SG_ 1015 ALIVE_SWS_AUDIO_CONT "Alive Counter";
CM_ SG_ 1015 CRC_SWS_AUDIO_CONT "DataID=0x004E. Checksum calculation accordig CAN Specification. Cyclic Redundancy Check";
CM_ SG_ 1015 VolumeUp_SWS "Status Button Increase Audio Volume";
CM_ SG_ 1015 OK_button_SWS "OK button status inside SWS. Long press is SWS_FAV select.
";
CM_ SG_ 1015 TOOT_SWS "Status Button Mute";
CM_ BO_ 1018 "Settings for customer functions, mode functions";
CM_ SG_ 1018 ALIVE_HU_03 "Alive Counter";
CM_ SG_ 1018 CRC_HU_03 "DataID=0x002F. Checksum calculation accordig CAN Specification. Cyclic Redundancy Check";
CM_ SG_ 1018 SET_RCP_Button "RCP softbutton status inside ICH, Display menue button information";
CM_ SG_ 1018 DimmingVehicleBrightness "255  invalid value. Valid range 0 - 100% Values between 101 and 254 are reserved. Used for PWM control of clamp 58,";
CM_ SG_ 1018 SET_DayTimeRunningLight "Activation of the day time running light";
CM_ SG_ 1018 SET_LeavingHomeSetting "Setting for follow me home light function
Invalid value = 3";
CM_ SG_ 1018 SET_ComingHomeSetting "Setting for Leaving home light";
CM_ SG_ 1018 SET_ToDefaultFactorySetting "Settings to default values for the ECU's,";
CM_ SG_ 1018 SET_RemoteLockFeedback "Remote Lock feedback: customer can choose light feedback when lock the door with remote key";
BA_DEF_  "DBName" STRING ;
BA_DEF_ SG_  "GenSigSendType" ENUM  "Cyclic","OnWrite","OnWriteWithRepetition","OnChange","OnChangeWithRepetition","NotUsed","NotUsed","NoSigSendType";
BA_DEF_ SG_  "GenSigInactiveValue" INT 0 65535;
BA_DEF_ SG_  "GenSigStartValue" HEX 0 65535;
BA_DEF_ BO_  "GenMsgTimeoutTime" INT 0 65535;
BA_DEF_ BO_  "E2EDataId" INT 0 65535;
BA_DEF_ BO_  "SCP_FreshnessValueTxLength" INT 0 512;
BA_DEF_ BO_  "SCP_FreshnessValueLength" INT 0 512;
BA_DEF_ BO_  "SCP_AuthInfoTxLength" INT 0 512;
BA_DEF_ BO_  "GenMsgSendType" ENUM  "Cyclic","NotUsed","NotUsed","NotUsed","NotUsed","NotUsed","NotUsed","IfActive","NoMsgSendType";
BA_DEF_ BO_  "NmAsrMessage" ENUM  "No","Yes";
BA_DEF_ BO_  "Transmitter" STRING ;
BA_DEF_ BO_  "Gateway" STRING ;
BA_DEF_ BO_  "VFrameFormat" ENUM  "CAN Standard","CAN Extended","reserved","reserved","reserved","reserved","reserved","reserved","reserved","reserved","reserved","reserved","reserved","reserved","CAN FD Standard","CAN FD Extended";
BA_DEF_ BO_  "DiagRequest" ENUM  "No","Yes";
BA_DEF_ BO_  "DiagResponse" ENUM  "No","Yes";
BA_DEF_ BO_  "DiagState" ENUM  "No","Yes";
BA_DEF_ BO_  "GenMsgCycleTime" INT 0 65535;
BA_DEF_ BO_  "GenMsgCycleTimeFast" INT 0 65535;
BA_DEF_ BO_  "GenMsgDelayTime" INT 0 65535;
BA_DEF_ BO_  "GenMsgILSupport" ENUM  "No","Yes";
BA_DEF_ BO_  "GenMsgNrOfRepetition" INT 0 255;
BA_DEF_ BO_  "GenMsgStartDelayTime" INT 0 65535;
BA_DEF_ BU_  "NmAsrNode" ENUM  "No","Yes";
BA_DEF_ BU_  "NmAsrCanMsgReducedTime" INT 0 65535;
BA_DEF_ BU_  "NmAsrCanMsgCycleOffset" INT 0 65535;
BA_DEF_ BU_  "ILUsed" ENUM  "No","Yes";
BA_DEF_ BU_  "NmAsrNodeIdentifier" HEX 0 255;
BA_DEF_  "BaudrateCANFD" INT 0 10000000;
BA_DEF_  "NmAsrWaitBusSleepTime" INT 0 65535;
BA_DEF_  "NmAsrTimeoutTime" INT 0 65536;
BA_DEF_  "NmAsrRepeatMessageTime" INT 0 65535;
BA_DEF_  "NmAsrCanMsgCycleTime" INT 0 65535;
BA_DEF_  "Baudrate" INT 0 1000000;
BA_DEF_  "BusType" STRING ;
BA_DEF_  "NmAsrBaseAddress" HEX 1280 2047;
BA_DEF_  "NmAsrMessageCount" INT 1 256;
BA_DEF_  "NmType" STRING ;
BA_DEF_DEF_  "DBName" "";
BA_DEF_DEF_  "GenSigSendType" "Cyclic";
BA_DEF_DEF_  "GenSigInactiveValue" 0;
BA_DEF_DEF_  "GenSigStartValue" 0;
BA_DEF_DEF_  "GenMsgTimeoutTime" 0;
BA_DEF_DEF_  "E2EDataId" 0;
BA_DEF_DEF_  "SCP_FreshnessValueTxLength" 4;
BA_DEF_DEF_  "SCP_FreshnessValueLength" 48;
BA_DEF_DEF_  "SCP_AuthInfoTxLength" 64;
BA_DEF_DEF_  "GenMsgSendType" "NoMsgSendType";
BA_DEF_DEF_  "NmAsrMessage" "No";
BA_DEF_DEF_  "Transmitter" "Default";
BA_DEF_DEF_  "Gateway" "Default";
BA_DEF_DEF_  "VFrameFormat" "CAN FD Standard";
BA_DEF_DEF_  "DiagRequest" "No";
BA_DEF_DEF_  "DiagResponse" "No";
BA_DEF_DEF_  "DiagState" "No";
BA_DEF_DEF_  "GenMsgCycleTime" 0;
BA_DEF_DEF_  "GenMsgCycleTimeFast" 0;
BA_DEF_DEF_  "GenMsgDelayTime" 0;
BA_DEF_DEF_  "GenMsgILSupport" "Yes";
BA_DEF_DEF_  "GenMsgNrOfRepetition" 0;
BA_DEF_DEF_  "GenMsgStartDelayTime" 0;
BA_DEF_DEF_  "NmAsrNode" "No";
BA_DEF_DEF_  "NmAsrCanMsgReducedTime" 50;
BA_DEF_DEF_  "NmAsrCanMsgCycleOffset" 0;
BA_DEF_DEF_  "ILUsed" "Yes";
BA_DEF_DEF_  "NmAsrNodeIdentifier" 0;
BA_DEF_DEF_  "BaudrateCANFD" 2000000;
BA_DEF_DEF_  "NmAsrWaitBusSleepTime" 1500;
BA_DEF_DEF_  "NmAsrTimeoutTime" 2000;
BA_DEF_DEF_  "NmAsrRepeatMessageTime" 3200;
BA_DEF_DEF_  "NmAsrCanMsgCycleTime" 640;
BA_DEF_DEF_  "Baudrate" 500000;
BA_DEF_DEF_  "BusType" "";
BA_DEF_DEF_  "NmAsrBaseAddress" 1280;
BA_DEF_DEF_  "NmAsrMessageCount" 128;
BA_DEF_DEF_  "NmType" "NmAsr";
BA_ "BusType" "CAN FD";
BA_ "DBName" "ADAS_CANFD";
BA_ "NmAsrNode" BU_ TPMS 1;
BA_ "NmAsrCanMsgCycleOffset" BU_ TPMS 125;
BA_ "NmAsrNodeIdentifier" BU_ TPMS 25;
BA_ "NmAsrNode" BU_ iBooster_ADAS 1;
BA_ "NmAsrCanMsgCycleOffset" BU_ iBooster_ADAS 155;
BA_ "NmAsrNodeIdentifier" BU_ iBooster_ADAS 31;
BA_ "NmAsrNode" BU_ IM 1;
BA_ "NmAsrCanMsgCycleOffset" BU_ IM 70;
BA_ "NmAsrNodeIdentifier" BU_ IM 14;
BA_ "NmAsrNode" BU_ ESC_ADAS 1;
BA_ "NmAsrCanMsgCycleOffset" BU_ ESC_ADAS 75;
BA_ "NmAsrNodeIdentifier" BU_ ESC_ADAS 15;
BA_ "NmAsrNode" BU_ EPS1_ADAS 1;
BA_ "NmAsrCanMsgCycleOffset" BU_ EPS1_ADAS 80;
BA_ "NmAsrNodeIdentifier" BU_ EPS1_ADAS 16;
BA_ "NmAsrNode" BU_ CGW_ADAS 1;
BA_ "NmAsrCanMsgCycleOffset" BU_ CGW_ADAS 5;
BA_ "NmAsrNodeIdentifier" BU_ CGW_ADAS 1;
BA_ "NmAsrNode" BU_ VCU_ADAS 1;
BA_ "NmAsrCanMsgCycleOffset" BU_ VCU_ADAS 20;
BA_ "NmAsrNodeIdentifier" BU_ VCU_ADAS 4;
BA_ "NmAsrNode" BU_ FCM 1;
BA_ "NmAsrCanMsgCycleOffset" BU_ FCM 25;
BA_ "NmAsrNodeIdentifier" BU_ FCM 5;
BA_ "E2EDataId" BO_ 912 139;
BA_ "Transmitter" BO_ 912 "IM";
BA_ "Gateway" BO_ 912 "CGW";
BA_ "GenMsgTimeoutTime" BO_ 913 3000;
BA_ "E2EDataId" BO_ 913 140;
BA_ "GenMsgSendType" BO_ 913 0;
BA_ "Transmitter" BO_ 913 "IM";
BA_ "Gateway" BO_ 913 "CGW";
BA_ "GenMsgCycleTime" BO_ 913 1000;
BA_ "Transmitter" BO_ 1986 "iBooster";
BA_ "Gateway" BO_ 1986 "-";
BA_ "Transmitter" BO_ 1982 "ESC";
BA_ "Gateway" BO_ 1982 "-";
BA_ "Transmitter" BO_ 1973 "FCM";
BA_ "Gateway" BO_ 1973 "-";
BA_ "Transmitter" BO_ 1906 "CGW";
BA_ "Gateway" BO_ 1906 "-";
BA_ "Transmitter" BO_ 1902 "CGW";
BA_ "Gateway" BO_ 1902 "-";
BA_ "Transmitter" BO_ 1893 "CGW";
BA_ "Gateway" BO_ 1893 "-";
BA_ "GenMsgTimeoutTime" BO_ 801 1500;
BA_ "E2EDataId" BO_ 801 46;
BA_ "GenMsgSendType" BO_ 801 0;
BA_ "Transmitter" BO_ 801 "HU";
BA_ "Gateway" BO_ 801 "-";
BA_ "GenMsgCycleTime" BO_ 801 500;
BA_ "Transmitter" BO_ 1791 "Tester";
BA_ "Gateway" BO_ 1791 "CGW,VCU,HU";
BA_ "DiagState" BO_ 1791 1;
BA_ "Transmitter" BO_ 1775 "Tester";
BA_ "Gateway" BO_ 1775 "CGW,VCU,HU";
BA_ "DiagState" BO_ 1775 1;
BA_ "GenMsgTimeoutTime" BO_ 789 1500;
BA_ "E2EDataId" BO_ 789 79;
BA_ "GenMsgSendType" BO_ 789 0;
BA_ "Transmitter" BO_ 789 "TBOX";
BA_ "Gateway" BO_ 789 "CGW,VCU,HU";
BA_ "GenMsgCycleTime" BO_ 789 500;
BA_ "GenMsgTimeoutTime" BO_ 901 3000;
BA_ "E2EDataId" BO_ 901 104;
BA_ "GenMsgSendType" BO_ 901 0;
BA_ "Transmitter" BO_ 901 "VCU";
BA_ "Gateway" BO_ 901 "CGW";
BA_ "GenMsgCycleTime" BO_ 901 1000;
BA_ "NmAsrMessage" BO_ 1296 1;
BA_ "Transmitter" BO_ 1296 "EPS";
BA_ "Gateway" BO_ 1296 "-";
BA_ "GenMsgILSupport" BO_ 1296 0;
BA_ "NmAsrMessage" BO_ 1295 1;
BA_ "Transmitter" BO_ 1295 "ESC";
BA_ "Gateway" BO_ 1295 "-";
BA_ "GenMsgILSupport" BO_ 1295 0;
BA_ "NmAsrMessage" BO_ 1281 1;
BA_ "Transmitter" BO_ 1281 "CGW";
BA_ "Gateway" BO_ 1281 "VCU";
BA_ "GenMsgILSupport" BO_ 1281 0;
BA_ "NmAsrMessage" BO_ 1311 1;
BA_ "Transmitter" BO_ 1311 "iBooster";
BA_ "Gateway" BO_ 1311 "-";
BA_ "GenMsgILSupport" BO_ 1311 0;
BA_ "Transmitter" BO_ 1945 "CGW";
BA_ "Gateway" BO_ 1945 "-";
BA_ "GenMsgILSupport" BO_ 1945 0;
BA_ "Transmitter" BO_ 1992 "TPMS";
BA_ "Gateway" BO_ 1992 "CGW";
BA_ "GenMsgILSupport" BO_ 1992 0;
BA_ "GenMsgTimeoutTime" BO_ 528 3000;
BA_ "E2EDataId" BO_ 528 93;
BA_ "GenMsgSendType" BO_ 528 0;
BA_ "Transmitter" BO_ 528 "TPMS";
BA_ "Gateway" BO_ 528 "CGW";
BA_ "GenMsgCycleTime" BO_ 528 1000;
BA_ "E2EDataId" BO_ 640 52;
BA_ "Transmitter" BO_ 640 "HU";
BA_ "Gateway" BO_ 640 "CGW";
BA_ "GenMsgTimeoutTime" BO_ 128 300;
BA_ "E2EDataId" BO_ 128 98;
BA_ "GenMsgSendType" BO_ 128 0;
BA_ "Transmitter" BO_ 128 "VCU";
BA_ "Gateway" BO_ 128 "-";
BA_ "GenMsgCycleTime" BO_ 128 10;
BA_ "GenMsgTimeoutTime" BO_ 832 300;
BA_ "E2EDataId" BO_ 832 88;
BA_ "GenMsgSendType" BO_ 832 0;
BA_ "Transmitter" BO_ 832 "TCC";
BA_ "Gateway" BO_ 832 "CGW, VCU, LIN";
BA_ "GenMsgCycleTime" BO_ 832 100;
BA_ "GenMsgTimeoutTime" BO_ 409 30;
BA_ "E2EDataId" BO_ 409 38;
BA_ "GenMsgSendType" BO_ 409 0;
BA_ "Transmitter" BO_ 409 "ESC";
BA_ "Gateway" BO_ 409 "CGW, VCU";
BA_ "GenMsgCycleTime" BO_ 409 10;
BA_ "GenMsgTimeoutTime" BO_ 299 30;
BA_ "E2EDataId" BO_ 299 40;
BA_ "GenMsgSendType" BO_ 299 0;
BA_ "Transmitter" BO_ 299 "ESC";
BA_ "Gateway" BO_ 299 "CGW, VCU";
BA_ "GenMsgCycleTime" BO_ 299 10;
BA_ "GenMsgTimeoutTime" BO_ 152 30;
BA_ "E2EDataId" BO_ 152 39;
BA_ "GenMsgSendType" BO_ 152 0;
BA_ "Transmitter" BO_ 152 "ESC";
BA_ "Gateway" BO_ 152 "CGW, VCU";
BA_ "GenMsgCycleTime" BO_ 152 10;
BA_ "GenMsgTimeoutTime" BO_ 787 1500;
BA_ "E2EDataId" BO_ 787 45;
BA_ "GenMsgSendType" BO_ 787 0;
BA_ "Transmitter" BO_ 787 "HU";
BA_ "Gateway" BO_ 787 "CGW,VCU";
BA_ "GenMsgCycleTime" BO_ 787 500;
BA_ "GenMsgTimeoutTime" BO_ 786 1500;
BA_ "E2EDataId" BO_ 786 41;
BA_ "GenMsgSendType" BO_ 786 0;
BA_ "Transmitter" BO_ 786 "ESC";
BA_ "Gateway" BO_ 786 "CGW,VCU,HU";
BA_ "GenMsgCycleTime" BO_ 786 500;
BA_ "GenMsgTimeoutTime" BO_ 386 300;
BA_ "E2EDataId" BO_ 386 43;
BA_ "GenMsgSendType" BO_ 386 0;
BA_ "Transmitter" BO_ 386 "FCM";
BA_ "Gateway" BO_ 386 "CGW";
BA_ "GenMsgCycleTime" BO_ 386 100;
BA_ "GenMsgTimeoutTime" BO_ 357 1500;
BA_ "E2EDataId" BO_ 357 3;
BA_ "GenMsgSendType" BO_ 357 0;
BA_ "Transmitter" BO_ 357 "FCM";
BA_ "Gateway" BO_ 357 "CGW";
BA_ "GenMsgCycleTime" BO_ 357 500;
BA_ "GenMsgTimeoutTime" BO_ 352 1500;
BA_ "E2EDataId" BO_ 352 49;
BA_ "GenMsgSendType" BO_ 352 0;
BA_ "Transmitter" BO_ 352 "HU";
BA_ "Gateway" BO_ 352 "CGW, VCU";
BA_ "GenMsgCycleTime" BO_ 352 500;
BA_ "GenMsgTimeoutTime" BO_ 400 300;
BA_ "E2EDataId" BO_ 400 77;
BA_ "GenMsgSendType" BO_ 400 0;
BA_ "Transmitter" BO_ 400 "HU";
BA_ "Gateway" BO_ 400 "CGW";
BA_ "GenMsgCycleTime" BO_ 400 100;
BA_ "GenMsgTimeoutTime" BO_ 1055 3000;
BA_ "E2EDataId" BO_ 1055 127;
BA_ "GenMsgSendType" BO_ 1055 0;
BA_ "Transmitter" BO_ 1055 "iBooster";
BA_ "Gateway" BO_ 1055 "CGW";
BA_ "GenMsgCycleTime" BO_ 1055 1000;
BA_ "GenMsgCycleTimeFast" BO_ 1055 25;
BA_ "GenMsgDelayTime" BO_ 1055 25;
BA_ "GenMsgNrOfRepetition" BO_ 1055 3;
BA_ "GenMsgTimeoutTime" BO_ 1049 3000;
BA_ "E2EDataId" BO_ 1049 137;
BA_ "GenMsgSendType" BO_ 1049 0;
BA_ "Transmitter" BO_ 1049 "TPMS";
BA_ "Gateway" BO_ 1049 "CGW";
BA_ "GenMsgCycleTime" BO_ 1049 1000;
BA_ "GenMsgCycleTimeFast" BO_ 1049 25;
BA_ "GenMsgDelayTime" BO_ 1049 25;
BA_ "GenMsgNrOfRepetition" BO_ 1049 3;
BA_ "Transmitter" BO_ 2564485407 "iBooster";
BA_ "Gateway" BO_ 2564485407 "CGW";
BA_ "DiagResponse" BO_ 2564485407 1;
BA_ "VFrameFormat" BO_ 2564485407 15;
BA_ "Transmitter" BO_ 2564485401 "TPMS";
BA_ "Gateway" BO_ 2564485401 "CGW";
BA_ "DiagResponse" BO_ 2564485401 1;
BA_ "VFrameFormat" BO_ 2564485401 15;
BA_ "Transmitter" BO_ 2564431857 "Tester";
BA_ "Gateway" BO_ 2564431857 "CGW";
BA_ "DiagRequest" BO_ 2564431857 1;
BA_ "VFrameFormat" BO_ 2564431857 15;
BA_ "Transmitter" BO_ 2564430321 "Tester";
BA_ "Gateway" BO_ 2564430321 "CGW";
BA_ "DiagRequest" BO_ 2564430321 1;
BA_ "VFrameFormat" BO_ 2564430321 15;
BA_ "GenMsgTimeoutTime" BO_ 263 600;
BA_ "E2EDataId" BO_ 263 17;
BA_ "GenMsgSendType" BO_ 263 0;
BA_ "Transmitter" BO_ 263 "BCM";
BA_ "Gateway" BO_ 263 "CGW";
BA_ "GenMsgCycleTime" BO_ 263 200;
BA_ "GenMsgTimeoutTime" BO_ 265 300;
BA_ "E2EDataId" BO_ 265 14;
BA_ "GenMsgSendType" BO_ 265 0;
BA_ "Transmitter" BO_ 265 "BCM";
BA_ "Gateway" BO_ 265 "CGW, VCU, LIN";
BA_ "GenMsgCycleTime" BO_ 265 100;
BA_ "GenMsgCycleTimeFast" BO_ 265 10;
BA_ "GenMsgNrOfRepetition" BO_ 265 3;
BA_ "GenMsgTimeoutTime" BO_ 262 75;
BA_ "E2EDataId" BO_ 262 13;
BA_ "GenMsgSendType" BO_ 262 0;
BA_ "Transmitter" BO_ 262 "BCM";
BA_ "Gateway" BO_ 262 "CGW, VCU, LIN";
BA_ "GenMsgCycleTime" BO_ 262 25;
BA_ "GenMsgTimeoutTime" BO_ 324 30;
BA_ "E2EDataId" BO_ 324 37;
BA_ "GenMsgSendType" BO_ 324 0;
BA_ "Transmitter" BO_ 324 "ESC";
BA_ "Gateway" BO_ 324 "CGW, VCU, HU";
BA_ "GenMsgCycleTime" BO_ 324 10;
BA_ "GenMsgTimeoutTime" BO_ 267 300;
BA_ "E2EDataId" BO_ 267 92;
BA_ "GenMsgSendType" BO_ 267 0;
BA_ "Transmitter" BO_ 267 "TM";
BA_ "Gateway" BO_ 267 "CGW";
BA_ "GenMsgCycleTime" BO_ 267 100;
BA_ "GenMsgCycleTimeFast" BO_ 267 20;
BA_ "GenMsgNrOfRepetition" BO_ 267 3;
BA_ "GenMsgTimeoutTime" BO_ 171 300;
BA_ "E2EDataId" BO_ 171 1;
BA_ "GenMsgSendType" BO_ 171 0;
BA_ "Transmitter" BO_ 171 "ACM";
BA_ "Gateway" BO_ 171 "CGW, VCU";
BA_ "GenMsgCycleTime" BO_ 171 100;
BA_ "GenMsgCycleTimeFast" BO_ 171 10;
BA_ "GenMsgDelayTime" BO_ 171 5;
BA_ "GenMsgTimeoutTime" BO_ 760 3000;
BA_ "E2EDataId" BO_ 760 80;
BA_ "GenMsgSendType" BO_ 760 0;
BA_ "Transmitter" BO_ 760 "TBOX";
BA_ "Gateway" BO_ 760 "CGW, VCU";
BA_ "GenMsgCycleTime" BO_ 760 1000;
BA_ "GenMsgTimeoutTime" BO_ 1015 60;
BA_ "E2EDataId" BO_ 1015 78;
BA_ "GenMsgSendType" BO_ 1015 0;
BA_ "Transmitter" BO_ 1015 "HU";
BA_ "Gateway" BO_ 1015 "CGW";
BA_ "GenMsgCycleTime" BO_ 1015 20;
BA_ "GenMsgCycleTimeFast" BO_ 1015 20;
BA_ "GenMsgNrOfRepetition" BO_ 1015 3;
BA_ "GenMsgTimeoutTime" BO_ 1018 3000;
BA_ "E2EDataId" BO_ 1018 47;
BA_ "Transmitter" BO_ 1018 "HU";
BA_ "Gateway" BO_ 1018 "CGW";
BA_ "GenMsgCycleTime" BO_ 1018 1000;
BA_ "GenMsgCycleTimeFast" BO_ 1018 100;
BA_ "GenMsgNrOfRepetition" BO_ 1018 3;
BA_ "GenSigSendType" SG_ 912 ALIVE_IM_02 3;
BA_ "GenSigSendType" SG_ 912 CRC_IM_02 3;
BA_ "GenSigSendType" SG_ 912 IM_Driver_Fatigue_Event 3;
BA_ "GenSigSendType" SG_ 912 IM_Driver_Distraction_Event 3;
BA_ "GenSigSendType" SG_ 1986 IDS_iBooster_Resp 1;
BA_ "GenSigSendType" SG_ 1982 IDS_ESC_Resp 1;
BA_ "GenSigSendType" SG_ 1973 IDS_FCM_Resp 1;
BA_ "GenSigSendType" SG_ 1906 IDS_iBooster_Req 1;
BA_ "GenSigSendType" SG_ 1902 IDS_ESC_Req 1;
BA_ "GenSigSendType" SG_ 1893 IDS_FCM_Req 1;
BA_ "GenSigSendType" SG_ 1791 Diag_FuncReq_All_ECUs 1;
BA_ "GenSigSendType" SG_ 1775 Diag_FuncReq_All_CAN 1;
BA_ "GenSigSendType" SG_ 1296 usrData1_EPS_Bit7_ECUSPEC_AWAKE 7;
BA_ "GenSigSendType" SG_ 1296 usrData1_EPS_Bit6_DIAGN_AWAKE 7;
BA_ "GenSigSendType" SG_ 1296 usrData1_EPS_Bit5_IGNITION_AWAKE 7;
BA_ "GenSigSendType" SG_ 1296 usrData1_EPS_Bit4_NETWORK_AWAKE 7;
BA_ "GenSigSendType" SG_ 1296 usrData1_EPS_Bit3_ECUSPEC_WAKEUP 7;
BA_ "GenSigSendType" SG_ 1296 usrData1_EPS_Bit2_NETWORK_WAKEUP 7;
BA_ "GenSigSendType" SG_ 1296 usrData1_EPS_Bit1_RESET_WAKEUP 7;
BA_ "GenSigSendType" SG_ 1296 CtrlBitVector_EPS_Bit7_Res 7;
BA_ "GenSigSendType" SG_ 1296 CtrlBitVector_EPS_Bit6_PNI 7;
BA_ "GenSigSendType" SG_ 1296 CtrlBitVector_EPS_Bit5_Res 7;
BA_ "GenSigSendType" SG_ 1296 CtrlBitVector_EPS_Bit4_ActWake 7;
BA_ "GenSigSendType" SG_ 1296 CtrlBitVector_EPS_Bit3_NMCoord 7;
BA_ "GenSigSendType" SG_ 1296 CtrlBitVector_EPS_Bit2_Res 7;
BA_ "GenSigSendType" SG_ 1296 CtrlBitVector_EPS_Bit1_Res 7;
BA_ "GenSigSendType" SG_ 1296 usrData1_EPS_Bit0_IGN_WAKEUP 7;
BA_ "GenSigSendType" SG_ 1296 usrData0_EPS 7;
BA_ "GenSigSendType" SG_ 1296 srcNodeID_EPS 7;
BA_ "GenSigSendType" SG_ 1296 CtrlBitVector_EPS_Bit0_RMR 7;
BA_ "GenSigSendType" SG_ 1296 usrData2_EPS 7;
BA_ "GenSigSendType" SG_ 1296 usrData4_EPS_PN_Info1 7;
BA_ "GenSigSendType" SG_ 1296 usrData5_EPS_PN_Info2 7;
BA_ "GenSigSendType" SG_ 1296 usrData3_EPS 7;
BA_ "GenSigSendType" SG_ 1295 usrData1_ESC_Bit7_ECUSPEC_AWAKE 7;
BA_ "GenSigSendType" SG_ 1295 usrData1_ESC_Bit6_DIAGN_AWAKE 7;
BA_ "GenSigSendType" SG_ 1295 usrData1_ESC_Bit5_IGNITION_AWAKE 7;
BA_ "GenSigSendType" SG_ 1295 usrData1_ESC_Bit4_NETWORK_AWAKE 7;
BA_ "GenSigSendType" SG_ 1295 usrData1_ESC_Bit3_ECUSPEC_WAKEUP 7;
BA_ "GenSigSendType" SG_ 1295 usrData1_ESC_Bit2_NETWORK_WAKEUP 7;
BA_ "GenSigSendType" SG_ 1295 usrData1_ESC_Bit1_RESET_WAKEUP 7;
BA_ "GenSigSendType" SG_ 1295 CtrlBitVector_ESC_Bit7_Res 7;
BA_ "GenSigSendType" SG_ 1295 CtrlBitVector_ESC_Bit6_PNI 7;
BA_ "GenSigSendType" SG_ 1295 CtrlBitVector_ESC_Bit5_Res 7;
BA_ "GenSigSendType" SG_ 1295 CtrlBitVector_ESC_Bit4_ActWake 7;
BA_ "GenSigSendType" SG_ 1295 CtrlBitVector_ESC_Bit3_NMCoord 7;
BA_ "GenSigSendType" SG_ 1295 CtrlBitVector_ESC_Bit2_Res 7;
BA_ "GenSigSendType" SG_ 1295 CtrlBitVector_ESC_Bit1_Res 7;
BA_ "GenSigSendType" SG_ 1295 usrData1_ESC_Bit0_IGN_WAKEUP 7;
BA_ "GenSigSendType" SG_ 1295 usrData0_ESC 7;
BA_ "GenSigSendType" SG_ 1295 srcNodeID_ESC 7;
BA_ "GenSigSendType" SG_ 1295 CtrlBitVector_ESC_Bit0_RMR 7;
BA_ "GenSigSendType" SG_ 1295 usrData2_ESC 7;
BA_ "GenSigSendType" SG_ 1295 usrData4_ESC_PN_Info1 7;
BA_ "GenSigSendType" SG_ 1295 usrData5_ESC_PN_Info2 7;
BA_ "GenSigSendType" SG_ 1295 usrData3_ESC 7;
BA_ "GenSigSendType" SG_ 1281 usrData1_CGW_Bit7_ECUSPEC_AWAKE 7;
BA_ "GenSigSendType" SG_ 1281 usrData1_CGW_Bit6_DIAGN_AWAKE 7;
BA_ "GenSigSendType" SG_ 1281 usrData1_CGW_Bit5_IGNITION_AWAKE 7;
BA_ "GenSigSendType" SG_ 1281 usrData1_CGW_Bit4_NETWORK_AWAKE 7;
BA_ "GenSigSendType" SG_ 1281 usrData1_CGW_Bit3_ECUSPEC_WAKEUP 7;
BA_ "GenSigSendType" SG_ 1281 usrData1_CGW_Bit2_NETWORK_WAKEUP 7;
BA_ "GenSigSendType" SG_ 1281 usrData1_CGW_Bit1_RESET_WAKEUP 7;
BA_ "GenSigSendType" SG_ 1281 CtrlBitVector_CGW_Bit7_Res 7;
BA_ "GenSigSendType" SG_ 1281 CtrlBitVector_CGW_Bit6_PNI 7;
BA_ "GenSigSendType" SG_ 1281 CtrlBitVector_CGW_Bit5_Res 7;
BA_ "GenSigSendType" SG_ 1281 CtrlBitVector_CGW_Bit4_ActWake 7;
BA_ "GenSigSendType" SG_ 1281 CtrlBitVector_CGW_Bit3_NMCoord 7;
BA_ "GenSigSendType" SG_ 1281 CtrlBitVector_CGW_Bit2_Res 7;
BA_ "GenSigSendType" SG_ 1281 CtrlBitVector_CGW_Bit1_Res 7;
BA_ "GenSigSendType" SG_ 1281 usrData1_CGW_Bit0_IGN_WAKEUP 7;
BA_ "GenSigSendType" SG_ 1281 usrData0_CGW 7;
BA_ "GenSigSendType" SG_ 1281 srcNodeID_CGW 7;
BA_ "GenSigSendType" SG_ 1281 CtrlBitVector_CGW_Bit0_RMR 7;
BA_ "GenSigSendType" SG_ 1281 usrData2_CGW 7;
BA_ "GenSigSendType" SG_ 1281 usrData4_CGW_PN_Info1 7;
BA_ "GenSigSendType" SG_ 1281 usrData5_CGW_PN_Info2 7;
BA_ "GenSigSendType" SG_ 1281 usrData3_CGW 7;
BA_ "GenSigSendType" SG_ 1311 usrData1_iBo_Bit7_ECUSPEC_AWAKE 7;
BA_ "GenSigSendType" SG_ 1311 usrData1_iBo_Bit6_DIAGN_AWAKE 7;
BA_ "GenSigSendType" SG_ 1311 usrData1_iBo_Bit5_IGNITION_AWAKE 7;
BA_ "GenSigSendType" SG_ 1311 usrData1_iBo_Bit4_NETWORK_AWAKE 7;
BA_ "GenSigSendType" SG_ 1311 usrData1_iBo_Bit3_ECUSPEC_WAKEUP 7;
BA_ "GenSigSendType" SG_ 1311 usrData1_iBo_Bit2_NETWORK_WAKEUP 7;
BA_ "GenSigSendType" SG_ 1311 usrData1_iBo_Bit1_RESET_WAKEUP 7;
BA_ "GenSigSendType" SG_ 1311 CtrlBitVector_iBo_Bit7_Res 7;
BA_ "GenSigSendType" SG_ 1311 CtrlBitVector_iBo_Bit6_PNI 7;
BA_ "GenSigSendType" SG_ 1311 CtrlBitVector_iBo_Bit5_Res 7;
BA_ "GenSigSendType" SG_ 1311 CtrlBitVector_iBo_Bit4_ActWake 7;
BA_ "GenSigSendType" SG_ 1311 CtrlBitVector_iBo_Bit3_NMCoord 7;
BA_ "GenSigSendType" SG_ 1311 CtrlBitVector_iBo_Bit2_Res 7;
BA_ "GenSigSendType" SG_ 1311 CtrlBitVector_iBo_Bit1_Res 7;
BA_ "GenSigSendType" SG_ 1311 usrData1_iBo_Bit0_IGN_WAKEUP 7;
BA_ "GenSigSendType" SG_ 1311 usrData0_iBo 7;
BA_ "GenSigSendType" SG_ 1311 srcNodeID_iBo 7;
BA_ "GenSigSendType" SG_ 1311 CtrlBitVector_iBo_Bit0_RMR 7;
BA_ "GenSigSendType" SG_ 1311 usrData2_iBo 7;
BA_ "GenSigSendType" SG_ 1311 usrData4_iBo_PN_Info1 7;
BA_ "GenSigSendType" SG_ 1311 usrData5_iBo_PN_Info2 7;
BA_ "GenSigSendType" SG_ 1311 usrData3_iBo 7;
BA_ "GenSigSendType" SG_ 1945 TPMS_Rx_CCP_Byte8 7;
BA_ "GenSigSendType" SG_ 1945 TPMS_Rx_CCP_Byte7 7;
BA_ "GenSigSendType" SG_ 1945 TPMS_Rx_CCP_Byte6 7;
BA_ "GenSigSendType" SG_ 1945 TPMS_Rx_CCP_Byte5 7;
BA_ "GenSigSendType" SG_ 1945 TPMS_Rx_CCP_Byte4 7;
BA_ "GenSigSendType" SG_ 1945 TPMS_Rx_CCP_Byte3 7;
BA_ "GenSigSendType" SG_ 1945 TPMS_Rx_CCP_Byte2 7;
BA_ "GenSigSendType" SG_ 1945 TPMS_Rx_CCP_TPCI 7;
BA_ "GenSigSendType" SG_ 1992 TPMS_Tx_CCP_Byte6 7;
BA_ "GenSigSendType" SG_ 1992 TPMS_Tx_CCP_Byte8 7;
BA_ "GenSigSendType" SG_ 1992 TPMS_Tx_CCP_Byte7 7;
BA_ "GenSigSendType" SG_ 1992 TPMS_Tx_CCP_Byte5 7;
BA_ "GenSigSendType" SG_ 1992 TPMS_Tx_CCP_TPCI 7;
BA_ "GenSigSendType" SG_ 1992 TPMS_Tx_CCP_Byte4 7;
BA_ "GenSigSendType" SG_ 1992 TPMS_Tx_CCP_Byte3 7;
BA_ "GenSigSendType" SG_ 1992 TPMS_Tx_CCP_Byte2 7;
BA_ "GenSigSendType" SG_ 640 ALIVE_HU_08 3;
BA_ "GenSigSendType" SG_ 640 CRC_HU_08 3;
BA_ "GenSigSendType" SG_ 640 DateFormat 3;
BA_ "GenSigSendType" SG_ 640 SpeedUnit 3;
BA_ "GenSigSendType" SG_ 640 DistanceUnit 3;
BA_ "GenSigSendType" SG_ 640 TempUnit 3;
BA_ "GenSigSendType" SG_ 640 FuelConsumption 3;
BA_ "GenSigSendType" SG_ 640 Language 3;
BA_ "GenSigSendType" SG_ 640 FuelUnit 3;
BA_ "GenSigSendType" SG_ 640 TimeFormat 3;
BA_ "GenSigStartValue" SG_ 832 TCC_CoolantTempIPU_IN 40;
BA_ "GenSigStartValue" SG_ 832 TCC_CabinTemp 80;
BA_ "GenSigStartValue" SG_ 832 TCC_AmbientTemp 80;
BA_ "GenSigStartValue" SG_ 832 TCC_AmbientTempRaw 40;
BA_ "GenSigStartValue" SG_ 832 TCC_CoolantTempEDURear_IN 40;
BA_ "GenSigStartValue" SG_ 832 TCC_CoolantTempEDUFront_IN 40;
BA_ "GenSigSendType" SG_ 352 MILE_KM 3;
BA_ "GenSigSendType" SG_ 352 RNG 3;
BA_ "GenSigStartValue" SG_ 1055 BitStatus_iBooster 1;
BA_ "GenSigStartValue" SG_ 1049 BitStatus_TPMS 1;
BA_ "GenSigSendType" SG_ 2564485407 Diag_Resp_iBooster 1;
BA_ "GenSigSendType" SG_ 2564485401 Diag_Resp_TPMS 1;
BA_ "GenSigSendType" SG_ 2564431857 Diag_PhyReq_iBooster 1;
BA_ "GenSigSendType" SG_ 2564430321 Diag_PhyReq_TPMS 1;
BA_ "GenSigSendType" SG_ 265 STAT_BLTS_BCM_Mon 4;
BA_ "GenSigSendType" SG_ 265 STAT_BrakeLightSwitchBCM 4;
BA_ "GenSigSendType" SG_ 265 STAT_Horn 4;
BA_ "GenSigSendType" SG_ 265 STAT_WorkingLight_Button 4;
BA_ "GenSigSendType" SG_ 265 STAT_HazardWarn 4;
BA_ "GenSigStartValue" SG_ 262 RLS_TempSensorValue 80;
BA_ "GenSigStartValue" SG_ 262 RLS_TempDewPoint 396;
BA_ "GenSigStartValue" SG_ 262 RLS_HumidSensorValue 1;
BA_ "GenSigSendType" SG_ 267 ST_TRAI 4;
BA_ "GenSigSendType" SG_ 171 ST_CRASH_TYPE 3;
BA_ "GenSigStartValue" SG_ 171 ST_CRASH_TYPE 14;
BA_ "GenSigSendType" SG_ 171 ST_CRASH 3;
BA_ "GenSigStartValue" SG_ 171 ST_CRASH 6;
BA_ "GenSigStartValue" SG_ 760 TBOX_ZoneT 48;
BA_ "GenSigSendType" SG_ 1018 SET_TowMode 3;
BA_ "GenSigSendType" SG_ 1018 SteeringHeatingRequest 4;
BA_ "GenSigSendType" SG_ 1018 SET_InteriorMotionSensing 4;
BA_ "GenSigSendType" SG_ 1018 SET_RCP_Button 4;
BA_ "GenSigSendType" SG_ 1018 DimmingVehicleBrightness 3;
BA_ "GenSigSendType" SG_ 1018 SET_DayTimeRunningLight 2;
BA_ "GenSigSendType" SG_ 1018 SET_LeavingHomeSetting 2;
BA_ "GenSigSendType" SG_ 1018 SET_ComingHomeSetting 2;
BA_ "GenSigSendType" SG_ 1018 SET_ToDefaultFactorySetting 2;
BA_ "GenSigSendType" SG_ 1018 SET_RemoteLockFeedback 2;
VAL_ 912 IM_Driver_Fatigue_Event 0 "No fatigue" 1 "Drowsy_kss7" 2 "MicroSleep_kss8" 3 "Sleeping_kss9" ;
VAL_ 912 IM_Driver_Distraction_Event 0 "No distraction" 1 "Short distraction" 2 "Long distration" ;
VAL_ 913 IM_Calibrate_Result 0 "Success" 1 "Fail" ;
VAL_ 913 IM_Camera_Lens_Cover 0 "No lens covered" 1 "Lens covered" ;
VAL_ 913 IM_Driver_Eye_Invisible 0 "Eye visible" 1 "Eye invisible" ;
VAL_ 913 IM_Driver_Face_Invisible 0 "Face visible" 1 "Face invisible" ;
VAL_ 913 IM_Driver_Distraction 0 "No distraction" 1 "Short distraction status" 2 "Long distration status" ;
VAL_ 913 IM_Driver_Fatigue 0 "No fatigue" 1 "Drowsy_kss7" 2 "MicroSleep_kss8" 3 "Sleeping_kss9" ;
VAL_ 913 IM_DMS_Status 7 "Invalid" 4 "Fault" 3 "Deactivated" 2 "Active" 1 "Standby" 0 "Initialization" ;
VAL_ 801 HU_DigitSpeed 511 "Invalid" ;
VAL_ 801 HU_ST_TILT_Setting 1 "Tilt_deactivated" 0 "Tilt_activated" ;
VAL_ 801 HU_ST_USIS_Setting 1 "Usis_deactivated" 0 "Usis_activated" ;
VAL_ 789 TBOX_OTA_WakeupStatus 3 "Invalid" 2 "Reserved" 1 "Active" 0 "Initial" ;
VAL_ 789 TBOX_OTA_Status 15 "Invalid" 14 "Reserved" 13 "Reserved" 12 "Reserved" 11 "Reserved" 10 "Reserved" 9 "Idle" 8 "Rollback" 7 "OTA Error" 6 "Flashing" 5 "Download error" 4 "Pause downloading" 3 "Pre-flashing" 2 "Downloading" 1 "New version available" 0 "Initial" ;
VAL_ 901 VCU_TowModRq 1 "true" 0 "false" ;
VAL_ 901 VCU_TowModSts 1 "Mode active" 0 "Mode inactive" ;
VAL_ 901 VCU_ProdRollrModSts 1 "Active" 0 "Inactive" ;
VAL_ 901 VCU_DynoModSts 1 "Active" 0 "Inactive" ;
VAL_ 901 VCU_DynoModActvtnEnblSts 1 "Enabled" 0 "Disabled" ;
VAL_ 1296 usrData1_EPS_Bit7_ECUSPEC_AWAKE 0 "inactive" 1 "active" ;
VAL_ 1296 usrData1_EPS_Bit6_DIAGN_AWAKE 0 "inactive" 1 "active" ;
VAL_ 1296 usrData1_EPS_Bit5_IGNITION_AWAKE 0 "inactive" 1 "active" ;
VAL_ 1296 usrData1_EPS_Bit4_NETWORK_AWAKE 0 "inactive" 1 "active" ;
VAL_ 1296 usrData1_EPS_Bit3_ECUSPEC_WAKEUP 0 "inactive" 1 "active" ;
VAL_ 1296 usrData1_EPS_Bit2_NETWORK_WAKEUP 0 "inactive" 1 "active" ;
VAL_ 1296 usrData1_EPS_Bit1_RESET_WAKEUP 0 "inactive" 1 "active" ;
VAL_ 1296 CtrlBitVector_EPS_Bit3_NMCoord 0 "Start of synchronized shutdown is not requested by main coordinator" 1 "Start of synchronized shutdown is requested by main coordinator" ;
VAL_ 1296 usrData1_EPS_Bit0_IGN_WAKEUP 0 "inactive" 1 "active" ;
VAL_ 1296 usrData0_EPS 0 "User data for current vehicle without partial networking" 1 "User data for current vehicle with partial networking" 255 "User data not used" ;
VAL_ 1295 usrData1_ESC_Bit7_ECUSPEC_AWAKE 0 "inactive" 1 "active" ;
VAL_ 1295 usrData1_ESC_Bit6_DIAGN_AWAKE 0 "inactive" 1 "active" ;
VAL_ 1295 usrData1_ESC_Bit5_IGNITION_AWAKE 0 "inactive" 1 "active" ;
VAL_ 1295 usrData1_ESC_Bit4_NETWORK_AWAKE 0 "inactive" 1 "active" ;
VAL_ 1295 usrData1_ESC_Bit3_ECUSPEC_WAKEUP 0 "inactive" 1 "active" ;
VAL_ 1295 usrData1_ESC_Bit2_NETWORK_WAKEUP 0 "inactive" 1 "active" ;
VAL_ 1295 usrData1_ESC_Bit1_RESET_WAKEUP 0 "inactive" 1 "active" ;
VAL_ 1295 CtrlBitVector_ESC_Bit3_NMCoord 0 "Start of synchronized shutdown is not requested by main coordinator" 1 "Start of synchronized shutdown is requested by main coordinator" ;
VAL_ 1295 usrData1_ESC_Bit0_IGN_WAKEUP 0 "inactive" 1 "active" ;
VAL_ 1295 usrData0_ESC 0 "User data for current vehicle without partial networking" 1 "User data for current vehicle with partial networking" 255 "User data not used" ;
VAL_ 1281 usrData1_CGW_Bit7_ECUSPEC_AWAKE 0 "inactive" 1 "active" ;
VAL_ 1281 usrData1_CGW_Bit6_DIAGN_AWAKE 0 "inactive" 1 "active" ;
VAL_ 1281 usrData1_CGW_Bit5_IGNITION_AWAKE 0 "inactive" 1 "active" ;
VAL_ 1281 usrData1_CGW_Bit4_NETWORK_AWAKE 0 "inactive" 1 "active" ;
VAL_ 1281 usrData1_CGW_Bit3_ECUSPEC_WAKEUP 0 "inactive" 1 "active" ;
VAL_ 1281 usrData1_CGW_Bit2_NETWORK_WAKEUP 0 "inactive" 1 "active" ;
VAL_ 1281 usrData1_CGW_Bit1_RESET_WAKEUP 0 "inactive" 1 "active" ;
VAL_ 1281 CtrlBitVector_CGW_Bit3_NMCoord 0 "Start of synchronized shutdown is not requested by main coordinator" 1 "Start of synchronized shutdown is requested by main coordinator" ;
VAL_ 1281 usrData1_CGW_Bit0_IGN_WAKEUP 0 "inactive" 1 "active" ;
VAL_ 1281 usrData0_CGW 0 "User data for current vehicle without partial networking" 1 "User data for current vehicle with partial networking" 255 "User data not used" ;
VAL_ 1311 usrData1_iBo_Bit7_ECUSPEC_AWAKE 0 "inactive" 1 "active" ;
VAL_ 1311 usrData1_iBo_Bit6_DIAGN_AWAKE 0 "inactive" 1 "active" ;
VAL_ 1311 usrData1_iBo_Bit5_IGNITION_AWAKE 0 "inactive" 1 "active" ;
VAL_ 1311 usrData1_iBo_Bit4_NETWORK_AWAKE 0 "inactive" 1 "active" ;
VAL_ 1311 usrData1_iBo_Bit3_ECUSPEC_WAKEUP 0 "inactive" 1 "active" ;
VAL_ 1311 usrData1_iBo_Bit2_NETWORK_WAKEUP 0 "inactive" 1 "active" ;
VAL_ 1311 usrData1_iBo_Bit1_RESET_WAKEUP 0 "inactive" 1 "active" ;
VAL_ 1311 CtrlBitVector_iBo_Bit3_NMCoord 0 "Start of synchronized shutdown is not requested by main coordinator" 1 "Start of synchronized shutdown is requested by main coordinator" ;
VAL_ 1311 usrData1_iBo_Bit0_IGN_WAKEUP 0 "inactive" 1 "active" ;
VAL_ 1311 usrData0_iBo 0 "User data for current vehicle without partial networking" 1 "User data for current vehicle with partial networking" 255 "User data not used" ;
VAL_ 528 TPM_MalfLmp_On_Rq 1 "ON" 0 "OFF" ;
VAL_ 528 TPM_IndLmp_On_Rq 1 "ON" 0 "OFF" ;
VAL_ 528 TPM_WarnDisp_Rq 7 "SNA" 3 "Fast" 2 "Low_p" 1 "Soft" 0 "No_warn" ;
VAL_ 528 TPM_Stat 7 "SNA" 3 "No_sensors" 2 "Error" 1 "Wait" 0 "Active" ;
VAL_ 528 TPM_MsgDisp_Rq 15 "SNA" 6 "restart" 5 "WE_miss" 4 "TNA" 3 "error" 2 "no_sensors" 1 "unplausible" 0 "no_message" ;
VAL_ 528 Press_Disp_Avl 1 "Available" 0 "Not_available" ;
VAL_ 528 TireStat_FR 3 "Fast_deflation" 2 "Low_pressure" 1 "Soft_warning" 0 "Normal" ;
VAL_ 528 TireStat_RL 3 "Fast_deflation" 2 "Low_pressure" 1 "Soft_warning" 0 "Normal" ;
VAL_ 528 TireStat_RR 3 "Fast_deflation" 2 "Low_pressure" 1 "Soft_warning" 0 "Normal" ;
VAL_ 528 TireStat_FL 3 "Fast_deflation" 2 "Low_pressure" 1 "Soft_warning" 0 "Normal" ;
VAL_ 528 TirePress_RR 255 "SNA" 254 "NO_IND" ;
VAL_ 528 TirePress_RL 255 "SNA" 254 "NO_IND" ;
VAL_ 528 TirePress_FR 255 "SNA" 254 "NO_IND" ;
VAL_ 528 TirePress_FL 255 "SNA" 254 "NO_IND" ;
VAL_ 528 Tire_Temp_WarnDisp_Rq 7 "SNA" 2 "Reduce_speed" 1 "Tire_overheated" 0 "No_message" ;
VAL_ 528 Tire_Temp_Stat_RR 3 "SNA" 2 "Hot" 1 "Warm" 0 "Normal" ;
VAL_ 528 Tire_Temp_Stat_RL 3 "SNA" 2 "Hot" 1 "Warm" 0 "Normal" ;
VAL_ 528 Tire_Temp_Stat_FR 3 "SNA" 2 "Hot" 1 "Warm" 0 "Normal" ;
VAL_ 528 Tire_Temp_Stat_FL 3 "SNA" 2 "Hot" 1 "Warm" 0 "Normal" ;
VAL_ 528 RefPress_Rear 255 "SNA" 254 "NO_IND" ;
VAL_ 528 RefPress_Front 255 "SNA" 254 "NO_IND" ;
VAL_ 528 TireTemp_RR 255 "SNA" ;
VAL_ 528 TireTemp_RL 255 "SNA" ;
VAL_ 528 TireTemp_FR 255 "SNA" ;
VAL_ 528 TireTemp_FL 255 "SNA" ;
VAL_ 640 SpeedUnit 2 "Unit_Invalid" 1 "Unit_Mph" 0 "Unit_Kmph" ;
VAL_ 128 VCU_AccPedalPos_Q 3 "Reserved" 2 "Invalid" 1 "Valid" 0 "Initializing" ;
VAL_ 128 VCU_RECUPot_WhlTq_Q 3 "Reserved" 2 "Invalid" 1 "Valid" 0 "Initializing" ;
VAL_ 128 VCU_RECUPot_WhlTq_RA_Q 3 "Reserved" 2 "Invalid" 1 "Valid" 0 "Initializing" ;
VAL_ 128 VCU_RECUPot_WhlTq_FA_Q 3 "Reserved" 2 "Invalid" 1 "Valid" 0 "Initializing" ;
VAL_ 128 VCU_Target_WhlTq_Q 3 "Reserved" 2 "Invalid" 1 "Valid" 0 "Initializing" ;
VAL_ 128 VCU_Target_WhlTq_FA_Q 3 "Reserved" 2 "Invalid" 1 "Valid" 0 "Initializing" ;
VAL_ 128 VCU_Target_WhlTq_RA_Q 3 "Reserved" 2 "Invalid" 1 "Valid" 0 "Initializing" ;
VAL_ 128 VCU_coordWhlTq_Q 3 "Reserved" 2 "Invalid" 1 "Valid" 0 "Initializing" ;
VAL_ 832 TCC_ByPassFlap_error 3 "Invalid" 2 "Reserved" 1 "Error" 0 "No error" ;
VAL_ 832 TCC_RecircFlap_error 3 "Invalid" 2 "Reserved" 1 "Error" 0 "No error" ;
VAL_ 832 TCC_ModeFlap_error 3 "Invalid" 2 "Reserved" 1 "Error" 0 "No error" ;
VAL_ 832 TCC_Blower_Error 3 "Invalid" 2 "Reserved" 1 "Error" 0 "No error" ;
VAL_ 832 TCC_HVAC_AirDistributionMode 7 "Invalid" 6 "Defrost" 5 "Defog" 4 "Winter Bi-Level" 3 "Foot" 2 "Tri-Level (Vent-Foot-Defrost)" 1 "Vent-Foot" 0 "Vent" ;
VAL_ 832 TCC_HV_Compressor_Availability 1 "error" 0 "no error" ;
VAL_ 832 TCC_HV_Compressor_error 3 "Invalid" 2 "Reserved" 1 "Error" 0 "No error" ;
VAL_ 832 TCC_HV_PTC_HVAC_Availability 1 "error" 0 "no error" ;
VAL_ 832 TCC_HV_PTC_HVAC_error 3 "Invalid" 2 "Reserved" 1 "Error" 0 "No error" ;
VAL_ 832 TCC_AGM_error 3 "Invalid" 2 "Reserved" 1 "Error" 0 "No error" ;
VAL_ 832 TCC_EFAN_error 3 "Invalid" 2 "Reserved" 1 "Error" 0 "No error" ;
VAL_ 832 TCC_HV_PTC_Battery_Availability 1 "error" 0 "no error" ;
VAL_ 832 TCC_HV_PTC_Battery_error 3 "Invalid" 2 "Reserved" 1 "Error" 0 "No error" ;
VAL_ 832 TCC_WAPU_EDU_Error 3 "Invalid" 2 "Reserved" 1 "Error" 0 "No error" ;
VAL_ 832 TCC_RSV_EDU_Error 3 "Invalid" 2 "Reserved" 1 "Error" 0 "No error" ;
VAL_ 832 TCC_CoolantTempEDURear_IN_error 3 "Invalid" 2 "Reserved" 1 "Error" 0 "No error" ;
VAL_ 832 TCC_CoolantTempEDUFront_IN_error 3 "Invalid" 2 "Reserved" 1 "Error" 0 "No error" ;
VAL_ 832 TCC_EDU_Cooling_error 3 "Invalid" 2 "Reserved" 1 "Error" 0 "No error" ;
VAL_ 832 TCC_STAT_Defrost 3 "Invalid" 2 "Reserved" 1 "Active" 0 "Not active" ;
VAL_ 832 TCC_STAT_Sync 3 "Invalid" 2 "Reserved" 1 "Active" 0 "Not active" ;
VAL_ 832 TCC_STAT_Recirc 3 "Invalid" 2 "Reserved" 1 "Active" 0 "Not active" ;
VAL_ 832 TCC_STAT_AC 3 "Invalid" 2 "Reserved" 1 "Active" 0 "Not active" ;
VAL_ 832 TCC_STAT_AUTO 3 "Invalid" 2 "Reserved" 1 "Active" 0 "Not active" ;
VAL_ 832 TCC_BlowerLevelManual 6 "Reserved" 5 "Reserved" 4 "Level 4" 3 "Level 3" 7 "Invalid" 2 "Level 2" 1 "Level 1" 0 "Level 0" ;
VAL_ 832 TCC_CoolantTempIPU_IN_error 3 "Invalid" 2 "Reserved" 1 "Error" 0 "No error" ;
VAL_ 832 TCC_CabinTemp_Q 3 "Invalid" 2 "Reserved" 1 "Valid" 0 "Init" ;
VAL_ 832 TCC_BlowerLevel 127 "Invalid" ;
VAL_ 832 TCC_AmbientTemp_Q 3 "Invalid" 2 "Reserved" 1 "Valid" 0 "Init" ;
VAL_ 832 TCC_STAT_MaxAC 3 "Invalid" 2 "Reserved" 1 "Active" 0 "Not active" ;
VAL_ 409 ESC_VehLatInc_Q 15 "Invalid" 14 "Reserved" 13 "Reserved" 12 "Reserved" 11 "Reserved" 10 "Reserved" 9 "Reserved" 8 "Reserved" 7 "Reserved" 6 "Reserved" 5 "Valid" 4 "Reserved" 3 "Reserved" 2 "Reserved" 1 "Reserved" 0 "Initializing" ;
VAL_ 409 ESC_VehLgtInc_Q 15 "Invalid" 14 "Reserved" 13 "Reserved" 12 "Reserved" 11 "Reserved" 10 "Reserved" 9 "Reserved" 8 "Reserved" 7 "Reserved" 6 "Reserved" 5 "Valid" 4 "Reserved" 3 "Reserved" 2 "Reserved" 1 "Reserved" 0 "Initializing" ;
VAL_ 409 ESC_LatAcc_Q 13 "Reserved" 5 "Valid" 0 "Initializing" 1 "Reserved" 2 "Reserved" 3 "Reserved" 4 "Reserved" 6 "Reserved" 7 "Reserved" 8 "Reserved" 9 "Reserved" 10 "Reserved" 11 "Reserved" 12 "Reserved" 14 "Reserved" 15 "Signal invalid" ;
VAL_ 409 ESC_LgtAcc_Q 13 "Reserved" 5 "Valid" 0 "Initializing" 1 "Reserved" 2 "Reserved" 3 "Reserved" 4 "Reserved" 6 "Reserved" 7 "Reserved" 8 "Reserved" 9 "Reserved" 10 "Reserved" 11 "Reserved" 12 "Reserved" 14 "Reserved" 15 "Signal invalid" ;
VAL_ 409 ESC_YawRt_Q 15 "Invalid" 14 "Reserved" 13 "Reserved" 12 "Reserved" 11 "Reserved" 10 "Reserved" 9 "Reserved" 8 "Reserved" 7 "Reserved" 6 "Reserved" 5 "Valid" 4 "Reserved" 3 "Reserved" 2 "Reserved" 1 "Reserved" 0 "Initialization" ;
VAL_ 299 ESC_IntvAct_Q 15 "Invalid" 14 "Reserved" 13 "Reserved" 12 "Reserved" 11 "Reserved" 10 "Reserved" 9 "Reserved" 8 "Reserved" 7 "Reserved" 6 "Reserved" 5 "Valid" 4 "Reserved" 3 "Reserved" 2 "Reserved" 1 "Reserved" 0 "Initalizing" ;
VAL_ 299 ESC_IntvAct 3 "Reserved" 2 "Reserved" 1 "Intervention active" 0 "No intervention" ;
VAL_ 299 ESC_DTC_IntvAct_Q 15 "Invalid" 14 "Reserved" 13 "Reserved" 12 "Reserved" 11 "Reserved" 10 "Reserved" 9 "Reserved" 8 "Reserved" 7 "Reserved" 6 "Reserved" 5 "Valid" 4 "Reserved" 3 "Reserved" 2 "Reserved" 1 "Reserved" 0 "Initalizing" ;
VAL_ 299 ESC_DTC_IntvAct 3 "Reserved" 2 "Reserved" 1 "Intervention active" 0 "No intervention" ;
VAL_ 299 ESC_TCS_IntvAct_Q 15 "Invalid" 14 "Reserved" 13 "Reserved" 12 "Reserved" 11 "Reserved" 10 "Reserved" 9 "Reserved" 8 "Reserved" 7 "Reserved" 6 "Reserved" 5 "Valid" 4 "Reserved" 3 "Reserved" 2 "Reserved" 1 "Reserved" 0 "Initalizing" ;
VAL_ 299 ESC_MotRotSpdMinLim_RA_Q 15 "Invalid" 14 "Reserved" 13 "Reserved" 12 "Reserved" 11 "Reserved" 10 "Reserved" 9 "Reserved" 8 "Reserved" 7 "Reserved" 6 "Reserved" 5 "Valid" 4 "Reserved" 3 "Reserved" 2 "Reserved" 1 "Reserved" 0 "Initializing" ;
VAL_ 299 ESC_MotRotSpdMinLim_FA_Q 15 "Invalid" 14 "Reserved" 13 "Reserved" 12 "Reserved" 11 "Reserved" 10 "Reserved" 9 "Reserved" 8 "Reserved" 7 "Reserved" 6 "Reserved" 5 "Valid" 4 "Reserved" 3 "Reserved" 2 "Reserved" 1 "Reserved" 0 "Initializing" ;
VAL_ 299 ESC_MotRotSpdMinLim_RA_Sts 1 "Released" 0 "Not released" ;
VAL_ 299 ESC_MotRotSpdMinLim_FA_Sts 1 "Released" 0 "Not released" ;
VAL_ 299 ESC_TCS_IntvAct 3 "Reserved" 2 "Reserved" 1 "Intervention active" 0 "No Intervention" ;
VAL_ 299 ESC_MotRotSpdMaxLim_FA_Sts 1 "Released" 0 "Not released" ;
VAL_ 299 ESC_MotRotSpdMaxLim_RA_Sts 1 "Released" 0 "Not released" ;
VAL_ 299 ESC_RecuWhlTqReq_Q 15 "Invalid" 14 "Reserved" 13 "Reserved" 12 "Reserved" 11 "Reserved" 10 "Reserved" 9 "Reserved" 8 "Reserved" 7 "Reserved" 6 "Reserved" 5 "Valid" 4 "Reserved" 3 "Reserved" 2 "Reserved" 1 "Reserved" 0 "Initalizing" ;
VAL_ 299 ESC_StabWhlTq_FA_Q 15 "Invalid" 14 "Reserved" 13 "Reserved" 12 "Reserved" 11 "Reserved" 10 "Reserved" 9 "Reserved" 8 "Reserved" 7 "Reserved" 6 "Reserved" 5 "Valid" 4 "Reserved" 3 "Reserved" 2 "Reserved" 1 "Reserved" 0 "Initializing" ;
VAL_ 299 ESC_RecuWhlTqReq_Sts 3 "Reserved" 2 "Reserved" 1 "Request active" 0 "Request not active" ;
VAL_ 299 ESC_StabWhlTq_FA_Sts 3 "Reserved" 2 "Max intervention (DTC)" 1 "Min intervention (TCS)" 0 "No intervention" ;
VAL_ 299 ESC_StabWhlTq_RA_Q 15 "Invalid" 14 "Reserved" 13 "Reserved" 12 "Reserved" 11 "Reserved" 10 "Reserved" 9 "Reserved" 8 "Reserved" 7 "Reserved" 6 "Reserved" 5 "Valid" 4 "Reserved" 3 "Reserved" 2 "Reserved" 1 "Reserved" 0 "Initializing" ;
VAL_ 299 ESC_StabWhlTq_RA_Sts 3 "Reserved" 2 "Max intervention (DTC)" 1 "Min intervention (TCS)" 0 "No intervention" ;
VAL_ 299 ESC_MotRotSpdMaxLim_FA_Q 15 "Invalid" 14 "Reserved" 13 "Reserved" 12 "Reserved" 11 "Reserved" 10 "Reserved" 9 "Reserved" 8 "Reserved" 7 "Reserved" 6 "Reserved" 5 "Valid" 4 "Reserved" 3 "Reserved" 2 "Reserved" 1 "Reserved" 0 "Initializing" ;
VAL_ 299 ESC_MotRotSpdMaxLim_RA_Q 15 "Invalid" 14 "Reserved" 13 "Reserved" 12 "Reserved" 11 "Reserved" 10 "Reserved" 9 "Reserved" 8 "Reserved" 7 "Reserved" 6 "Reserved" 5 "Valid" 4 "Reserved" 3 "Reserved" 2 "Reserved" 1 "Reserved" 0 "Initializing" ;
VAL_ 299 ESC_DrvTotBrkTqReq_Q 13 "Reserved" 5 "Valid" 0 "Initializing" 14 "Reserved" 12 "Reserved" 11 "Reserved" 10 "Reserved" 9 "Reserved" 7 "Reserved" 6 "Reserved" 4 "Reserved" 3 "Reserved" 1 "Reserved" 15 "Signal invalid" 8 "Reserved" 2 "Reserved" ;
VAL_ 299 ESC_TotBrkTqReq_Q 13 "Reserved" 5 "Valid" 0 "Initializing" 14 "Reserved" 12 "Reserved" 11 "Reserved" 10 "Reserved" 9 "Reserved" 7 "Reserved" 6 "Reserved" 4 "Reserved" 3 "Reserved" 2 "Reserved" 15 "Signal invalid" 8 "Reserved" 1 "Reserved" ;
VAL_ 152 ESC_ActvIndcn_AEB 1 "Active" 0 "Not active" ;
VAL_ 152 ESC_FltIndcn_AEB 3 "Invalid" 2 "Reserved" 1 "AEB not available" 0 "AEB available" ;
VAL_ 152 ESC_ABS_IntvAct 3 "Full intervention" 2 "Intervention RA" 1 "Intervention FA" 0 "No intervention" ;
VAL_ 152 ESC_SysSts 3 "Signal invalid" 2 "ESC Error/backup/degradation" 1 "ESC passive/offroad" 0 "ESC system OK, no error" ;
VAL_ 152 ESC_EssReq 3 "Hazard_light_request" 2 "Brake_light_blinking" 1 "No_request" 0 "Init" 7 "Invalid" 6 "Reserved" 5 "Reserved" 4 "Reserved" ;
VAL_ 152 ESC_EssReq_Q 15 "Invalid" 14 "Reserved" 13 "Reserved" 12 "Reserved" 11 "Reserved" 10 "Reserved" 9 "Reserved" 8 "Reserved" 7 "Reserved" 6 "Reserved" 5 "Valid" 4 "Reserved" 3 "Reserved" 2 "Reserved" 1 "Reserved" 0 "Initializing" ;
VAL_ 152 ESC_BrkLiReq_Q 15 "Invalid" 14 "Reserved" 13 "Reserved" 12 "Reserved" 11 "Reserved" 10 "Reserved" 9 "Reserved" 8 "Reserved" 7 "Reserved" 6 "Reserved" 5 "Valid" 4 "Reserved" 3 "Reserved" 2 "Reserved" 1 "Reserved" 0 "Initializing" ;
VAL_ 152 ESC_BrkLiReq 3 "Signal not available" 2 "Reserved" 1 "Brake light ON" 0 "Brake light OFF" ;
VAL_ 152 ESC_MstCylP_Q 15 "Invalid" 14 "Reserved" 13 "Reserved" 12 "Reserved" 11 "Reserved" 10 "Reserved" 9 "Reserved" 8 "Reserved" 7 "Reserved" 6 "Reserved" 5 "Valid" 4 "Reserved" 3 "Reserved" 2 "Reserved" 1 "Reserved" 0 "Initializing" ;
VAL_ 152 ESC_BTC_IntvAct_Q 15 "Invalid" 14 "Reserved" 13 "Reserved" 12 "Reserved" 11 "Reserved" 10 "Reserved" 9 "Reserved" 8 "Reserved" 7 "Reserved" 6 "Reserved" 5 "Valid" 4 "Reserved" 3 "Reserved" 2 "Reserved" 1 "Reserved" 0 "Initializing" ;
VAL_ 152 ESC_SystSts_EPB 3 "Invalid" 2 "both brakes in operation (applying/releasing)" 1 "both brakes applied" 0 "both brakes released" ;
VAL_ 152 ESC_AVH_Actv 3 "Signal invalid" 2 "Reserved" 1 "Active" 0 "Inactive" ;
VAL_ 152 ESC_CDP_Actv 3 "Signal invalid" 2 "Reserved" 1 "Active" 0 "Inactive" ;
VAL_ 152 ESC_EPB_SwitchPosition 3 "Error" 2 "Apply request" 1 "Release request" 0 "No request" ;
VAL_ 152 ESC_EPB_SwitchPosition_Q 15 "Invalid" 14 "Reserved" 13 "Reserved" 12 "Reserved" 11 "Reserved" 10 "Reserved" 9 "Reserved" 8 "Reserved" 7 "Reserved" 6 "Reserved" 5 "Valid" 4 "Reserved" 3 "Reserved" 2 "Reserved" 1 "Reserved" 0 "Initializing" ;
VAL_ 152 ESC_BTC_IntvAct 3 "Full intervention" 2 "BTC intervention RA" 1 "BTC intervention FA" 0 "No intervention" ;
VAL_ 152 ESC_VDC_IntvAct_Q 15 "Invalid" 14 "Reserved" 13 "Reserved" 12 "Reserved" 11 "Reserved" 10 "Reserved" 9 "Reserved" 8 "Reserved" 7 "Reserved" 6 "Reserved" 5 "Valid" 4 "Reserved" 3 "Reserved" 2 "Reserved" 1 "Reserved" 0 "Initializing" ;
VAL_ 152 ESC_ABS_IntvAct_Q 15 "Invalid" 14 "Reserved" 13 "Reserved" 12 "Reserved" 11 "Reserved" 10 "Reserved" 9 "Reserved" 8 "Reserved" 7 "Reserved" 6 "Reserved" 5 "Valid" 4 "Reserved" 3 "Reserved" 2 "Reserved" 1 "Reserved" 0 "Initializing" ;
VAL_ 152 ESC_DrvPressBrkPedl 0 "False" 1 "True" ;
VAL_ 152 ESC_SpecialMode 0 "Inactive" 1 "Dyno Mode active" 2 "Roller Mode active" 3 "Signal invalid" ;
VAL_ 152 ESC_VDC_IntvAct 3 "Full intervention" 2 "Intervention RA" 1 "Intervention FA" 0 "No intervention" ;
VAL_ 152 ESC_Mode 15 "Signal Invalid" 7 "ESCOffroadF&RDiffLockMode(FuMo8)" 6 "ESCOffroadRDiffLockMode(FuMo7)" 5 "ESC Offroad(VCL)&PaTaMode(FuMo6)" 4 "ESC Offroad (VCL) Mode (FuMo5)" 3 "ESC Grit & PaTa Mode(FuMo4)" 2 "ESC Grit Mode (FuMo3)" 1 "ESC Onroad & PaTa Mode (FuMo2)" 0 "ESC Onroad Mode (FuMo1)" ;
VAL_ 152 ESC_SystSts_HDC 3 "Active and Controlling" 2 "Active" 1 "Standby" 0 "OFF" 7 "Signal Invalid" 6 "Reserved" 5 "Reserved" 4 "Not Available" ;
VAL_ 152 ESC_SystSts_AVH 3 "Signal invalid" 2 "Reserved" 1 "Active" 0 "Inactive" ;
VAL_ 787 HU_OTA_UpdateConfirm 7 "Invalid" 6 "Reserved" 5 "Reserved" 4 "Reserved" 3 "Reserved" 2 "OTA Finished" 1 "OTA updateconfirmed" 0 "Initial" ;
VAL_ 786 ESC_OTA_inhib_FB 3 "Invalid" 2 "Not inhibited" 1 "Inhibited" 0 "Initial" ;
VAL_ 386 FCM_LaneMarkingColor 3 "Reserved" 2 "Invalid" 1 "Yellow" 0 "White" ;
VAL_ 386 FCM_LaneMarkingTyp 7 "Reserved" 6 "Reserved" 5 "Tide" 4 "Solid - Dashed" 3 "Dashed - Solid" 2 "Double solid" 1 "Single solid" 0 "Single dashed" ;
VAL_ 386 FCM_LaneMarkingSts 3 "Lane markings on both side" 2 "Right lane marking" 1 "Left lane marking" 0 "No lane marking" ;
VAL_ 386 FCM_DRA_AESA_ECALL_Req 1 "Requested" 0 "No request" ;
VAL_ 357 FCM_LA_sens_Feed 3 "Invalid" 2 "Late" 1 "Normal" 0 "Early" ;
VAL_ 357 FCM_ELKA_ON_Feed 2 "Invalid" 1 "ELKA ON" 0 "ELKA OFF" ;
VAL_ 357 FCM_LA_Mode_Feed 3 "Invalid" 2 "Warning & Steering" 1 "Warning Only" 0 "OFF" ;
VAL_ 357 FCM_HWA_ICON_Feed 5 "Red ICON" 4 "Yellow ICON" 3 "White ICON" 2 "Blue ICON" 1 "Gray ICON" 0 "Off" ;
VAL_ 357 FCM_DRA_Sts 6 "Fault" 5 "Active_suspend" 4 "Passive" 3 "Override" 2 "Active" 1 "Stand_by" 0 "Off" ;
VAL_ 357 FCM_AESA_Sts 3 "Reserved" 2 "Target following" 1 "Decelerating" 0 "Not active" ;
VAL_ 357 FCM_PDC_SettingSts 3 "Signal Invalid" 2 "No change" 1 "OFF" 0 "ON" ;
VAL_ 357 FCM_BSW_Sts 3 "Invalid" 2 "Error" 1 "Warning" 0 "No Warning" ;
VAL_ 357 FCM_DRA_DstSetgsSts 3 "Invalid" 2 "Error" 1 "Enabled" 0 "Disabled" ;
VAL_ 357 FCM_DRA_BehaviorSts 3 "Invalid" 2 "Error" 1 "Enabled" 0 "Disabled" ;
VAL_ 357 FCM_ASA_RoadCondSts 3 "Invalid" 2 "Error" 1 "Enabled" 0 "Disabled" ;
VAL_ 357 FCM_ASA_LegalLimSts 3 "Invalid" 2 "Error" 1 "Enabled" 0 "Disabled" ;
VAL_ 357 FCM_ELK_Sts 5 "Error" 4 "Active right" 3 "Active left" 2 "Passive" 1 "Standby" 0 "Off Mode" ;
VAL_ 357 FCM_LDW_Sts 5 "Error" 4 "Active right" 3 "Active left" 2 "Passive" 1 "Standby" 0 "Off Mode" ;
VAL_ 357 FCM_ASA_SpdChgWarnSts 3 "Error" 2 "Warning" 1 "No warning" 0 "OFF" ;
VAL_ 357 FCM_ASA_OverSpdWarnSts 7 "Invalid" 6 "Reserved" 5 "Reserved" 4 "Error" 3 "L2 Warning" 2 "L1 Warning" 1 "No Warning" 0 "OFF" ;
VAL_ 357 FCM_DCA_Sts 3 "Invalid" 2 "Error" 1 "Enabled" 0 "Disabled" ;
VAL_ 357 FCM_AEB_Sts 3 "Invalid" 2 "Error" 1 "Active Braking" 0 "Not Active" ;
VAL_ 357 FCM_FCW_Snvty 3 "Invalid" 2 "Late" 1 "Medium" 0 "Early" ;
VAL_ 357 FCM_FCW_Sts 3 "Invalid" 2 "Error" 1 "Warning" 0 "Not warning" ;
VAL_ 357 FCM_DRA_AESA_Status 3 "Reserved" 2 "Target following" 1 "Decelerating" 0 "Not active" ;
VAL_ 357 FCM_HOW_Sts 7 "Reserved" 6 "Reserved" 5 "Invalid" 4 "Error" 3 "Warning Level 3" 2 "Warning Level 2" 1 "Warning Level 1" 0 "No Warning" ;
VAL_ 357 FCM_LCA_Sts 7 "Reserved" 6 "Reserved" 5 "Invalid" 4 "Error" 3 "Suppression" 2 "Steering" 1 "Standby" 0 "Off" ;
VAL_ 357 FCM_VehPosiLane 7 "Reserved" 6 "Reserved" 5 "Ramp" 4 "Lane4" 3 "Lane3" 2 "Lane2" 1 "Lane1" 0 "Not detected" ;
VAL_ 357 FCM_TakeoverWarnSts 3 "Invalid" 2 "Error" 1 "Warning" 0 "No Warning" ;
VAL_ 357 FCM_ASA_Sts 3 "Error" 2 "Active" 1 "Standby" 0 "Off" ;
VAL_ 357 FCM_DCA_Sts2 3 "Signal Invalid" 2 "Reserved" 1 "Active" 0 "Inactive" ;
VAL_ 352 HU_Veh_DoorLock 1 "Locked" 0 "Unlock" ;
VAL_ 352 HU_Veh_GearPosition 4 "S" 3 "D" 2 "N" 1 "R" 0 "P" ;
VAL_ 352 HU_Veh_TurnLed 2 "Turn right" 1 "Turn left" 0 "No turn" ;
VAL_ 352 HU_Veh_SteerAngle_Symbol 1 "Negative" 0 "Positive" ;
VAL_ 352 HU_LDW_Switch 2 "Reserved" 1 "Sound" 0 "OFF" ;
VAL_ 352 HOD_HandsMonitor 2 "ON" 1 "Hands off" 0 "Initial" ;
VAL_ 352 HU_FunctSelect 15 "Invalid" 4 "Speed limiter active" 3 "Distance control active" 2 "CC active" 1 "ACC active" 0 "Init" ;
VAL_ 352 HU_SpeedControlSts 2 "Active" 1 "Standby" 0 "Off" ;
VAL_ 352 HU_CruiseControlSts 2 "Active" 1 "Standby" 0 "Off" ;
VAL_ 352 SET_ACCSoftbutton_mode 3 "invalid" 2 "Reserved" 1 "ASA to road topology off" 0 "ASA to road topology on " ;
VAL_ 352 SET_ACCSoftButton_set_timegap 15 "Singal invald" 5 "Very Far" 4 "Far" 3 "Mid" 2 "Short" 1 "Very Short" 0 "Remember" ;
VAL_ 352 HU_PDCPopupSts 3 "Invalid" 2 "Reserved" 1 "Pop up is open" 0 "Pop up is closed" ;
VAL_ 352 SET_PDCSoftButton_Front 3 "Invalid" 2 "Reserved" 1 "Off" 0 "On" ;
VAL_ 352 SET_PDCSetting 3 "Signal invalid" 2 "No change" 1 "Offroad ON" 0 "Offroad OFF" ;
VAL_ 352 SET_BlindSpotWarning 3 "Invalid" 2 "Reserved" 1 "Active" 0 "Not Active" ;
VAL_ 352 SET_DistanceSettings 3 "Invalid" 2 "Reserved" 1 "Active" 0 "Not Active" ;
VAL_ 352 SET_DrivingAssistBehavior 3 "Invalid" 2 "Reserved" 1 "Active" 0 "Not Active" ;
VAL_ 352 SET_AutoSpeedAdaption_RoadCond 3 "Invalid" 2 "Reserved" 1 "Active" 0 "Not Active" ;
VAL_ 352 SET_AutoSpeedAdaption_LegalLimit 3 "Invalid" 2 "Reserved" 1 "Active" 0 "Not Active" ;
VAL_ 352 SET_ELK 3 "Invalid" 2 "Reserved" 1 "Active" 0 "Not Active" ;
VAL_ 352 SET_LDW 3 "Invalid" 2 "Reserved" 1 "Active" 0 "Not Active" ;
VAL_ 352 SET_SpeedChangeWarning 3 "Invalid" 2 "Reserved" 1 "Active" 0 "Not Active" ;
VAL_ 352 SET_OverspeedWarning 3 "Invalid" 2 "Reserved" 1 "Active" 0 "Not Active" ;
VAL_ 352 SET_DriverConditionAssist 3 "Invalid" 2 "Reserved" 1 "Active" 0 "Not Active" ;
VAL_ 352 SET_AEB 3 "Invalid" 2 "Reserved" 1 "Active" 0 "Not Active" ;
VAL_ 352 SET_ForwardCollWarn_Sensitivity 3 "Invalid" 2 "Late" 1 "Medium" 0 "Early" ;
VAL_ 352 SET_ForwardCollisionWarning 3 "Invalid" 2 "Reserved" 1 "Active" 0 "Not Active" ;
VAL_ 352 HU_ELK_AcoustWarnSetg 2 "Reserved" 1 "Sound" 0 "OFF" ;
VAL_ 352 SET_ASA 3 "Invalid" 2 "Reserved" 1 "Active" 0 "Not Active" ;
VAL_ 352 SET_PDCSoftButton 3 "Invalid" 2 "Reserved" 1 "Press" 0 "No press" ;
VAL_ 352 STAT_ISAMap 3 "Supported" 2 "Failure" 1 "Not Supported" 0 "Unknown" ;
VAL_ 400 CC_STATE 3 "Signal invalid" 2 "Long Pressed" 1 "Short Pressed" 0 "Not Pressed" ;
VAL_ 400 CC_CNL 3 "Signal invalid" 2 "Long Pressed" 1 "Short Pressed" 0 "Not Pressed" ;
VAL_ 400 CC_RES 3 "Signal invalid" 2 "Long Pressed" 1 "Short Pressed" 0 "Not Pressed" ;
VAL_ 400 CC_SET 3 "Signal invalid" 2 "Long Pressed" 1 "Short Pressed" 0 "Not Pressed" ;
VAL_ 1055 BitBlinking_iBooster 3 "Signal invalid" 2 "3Hz" 1 "1Hz" 0 "No action" ;
VAL_ 1055 BitStatus_iBooster 3 "Signal invalid" 2 "Reserved" 1 "Reset" 0 "Set" ;
VAL_ 1049 BitBlinking_TPMS 3 "Signal invalid" 2 "3Hz" 1 "1Hz" 0 "No action" ;
VAL_ 1049 BitStatus_TPMS 3 "Signal invalid" 2 "Reserved" 1 "Reset" 0 "Set" ;
VAL_ 263 STAT_WiperSensitivityInterval 7 "Signal Invalid" 6 "Sensitivity 6" 5 "Sensitivity 5" 4 "Sensitivity 4" 3 "Sensitivity 3" 2 "Sensitivity 2" 1 "Sensitivity 1" 0 "Sensitivity 0" ;
VAL_ 263 STAT_WasherRear 3 "Signal invalid" 2 "Reserved" 1 "ON" 0 "OFF" ;
VAL_ 263 STAT_WiperRear 3 "Signal invalid" 2 "Continuous" 1 "Intermittent" 0 "OFF" ;
VAL_ 263 STAT_WasherFront 3 "Signal invalid" 2 "Reserved" 1 "ON" 0 "OFF" ;
VAL_ 263 STAT_WiperFront 7 "Signal invalid" 6 "Reserved" 5 "Reserved" 4 "High Speed" 3 "Low Speed" 2 "Intermittent Auto" 1 "Mist" 0 "OFF" ;
VAL_ 265 STAT_AutoAC_Button 3 "Signal Invalid" 2 "Reserved" 1 "Pressed" 0 "Not Pressed" ;
VAL_ 265 STAT_ESCButton 3 "Signal Invalid" 2 "Reserved" 1 "Pressed" 0 "Not Pressed" ;
VAL_ 265 STAT_WadingModeButton 3 "Signal Invalid" 2 "Reserved" 1 "Pressed" 0 "Not Pressed" ;
VAL_ 265 STAT_DownhillAssistButton 3 "Signal Invalid" 2 "Reserved" 1 "Pressed" 0 "Not Pressed" ;
VAL_ 265 STAT_InteriorSocket230VButton 3 "Signal Invalid" 2 "Reserved" 1 "Pressed" 0 "Not Pressed" ;
VAL_ 265 STAT_PDC_Button 3 "Signal Invalid" 2 "Reserved" 1 "Pressed" 0 "Not Pressed" ;
VAL_ 265 STAT_MaxAC_Button 3 "Signal Invalid" 2 "Reserved" 1 "Pressed" 0 "Not Pressed" ;
VAL_ 265 STAT_BLTS_BCM_Mon 3 "Signal invald monitoring not available" 2 "Short Cut Battery" 1 "Short Cut Ground or Open Load" 0 "No failure" ;
VAL_ 265 STAT_TemperatureRightWheel 7 "Invalid" 6 "Reserved" 5 "Reserved" 4 "Reserved" 3 "Fault" 2 "Status CCW" 1 "Status CW" 0 "Status Not Changed" ;
VAL_ 265 STAT_TemperatureLeftWheel 7 "Invalid" 6 "Reserved" 5 "Reserved" 4 "Reserved" 3 "Fault" 2 "Status CCW" 1 "Status CW" 0 "Status Not Changed" ;
VAL_ 265 STAT_FAN_Wheel 7 "Invalid" 6 "Reserved" 5 "Reserved" 4 "Reserved" 3 "Fault" 2 "Status CCW" 1 "Status CW" 0 "Status Not Changed" ;
VAL_ 265 STAT_AC_Button 3 "Signal Invalid" 2 "Reserved" 1 "Pressed" 0 "Not Pressed" ;
VAL_ 265 STAT_Zone_Wheel 7 "Invalid" 6 "Reserved" 5 "Reserved" 4 "Reserved" 3 "Fault" 2 "Status CCW" 1 "Status CW" 0 "Status Not Changed" ;
VAL_ 265 STAT_Recirculation_Button 3 "Signal Invalid" 2 "Reserved" 1 "Pressed" 0 "Not Pressed" ;
VAL_ 265 STAT_Windshield_Button 3 "Signal Invalid" 2 "Reserved" 1 "Pressed" 0 "Not Pressed" ;
VAL_ 265 STAT_MultimediaControlButton 3 "Right Short" 2 "Left Long" 1 "Left Short" 0 "Not Pressed" 7 "Fault" 6 "OnOff" 5 "Mute" 4 "Right Long" ;
VAL_ 265 STAT_MultimediaVolumeButton 7 "Invalid" 6 "Reserved" 5 "Reserved" 4 "Reserved" 3 "Fault" 2 "Status CCW" 1 "Status CW" 0 "Status Not Changed" ;
VAL_ 265 STAT_Display_Button 3 "Signal Invalid" 2 "Reserved" 1 "Pressed" 0 "Not Pressed" ;
VAL_ 265 STAT_SteeringWheelHeating_Button 3 "Signal Invalid" 2 "Reserved" 1 "Pressed" 0 "Not Pressed" ;
VAL_ 265 STAT_Sync_Button 3 "Signal Invalid" 2 "Reserved" 1 "Pressed" 0 "Not Pressed" ;
VAL_ 265 STAT_Defrost_Button 3 "Signal Invalid" 2 "Reserved" 1 "Pressed" 0 "Not Pressed" ;
VAL_ 265 STAT_BrakeLightSwitchBCM 3 "Signal invalid" 2 "Reserved" 1 "Brakel Light Switch  pressed" 0 "Brakel Light Switch not pressed" ;
VAL_ 265 STAT_Horn 3 "Signal invalid" 2 "Toot active" 1 "Horn active" 0 "not active" ;
VAL_ 265 STAT_WorkingLight_Button 3 "Signal invalid" 2 "Reserved" 1 "Pressed" 0 "Not Pressed" ;
VAL_ 265 STAT_HazardWarn 3 "Signal invalid" 2 "Reserved" 1 "Active" 0 "Not active" ;
VAL_ 262 STAT_ReadingLight_RR 3 "Invalid" 2 "Reserved" 1 "ON" 0 "OFF" ;
VAL_ 262 STAT_ActiveReadLightPA 3 "Invalid" 2 "Reserved" 1 "ON" 0 "OFF" ;
VAL_ 262 STAT_ActiveReadLightDR 3 "Invalid" 2 "Reserved" 1 "ON" 0 "OFF" ;
VAL_ 262 STAT_ActiveInteriorLight 3 "Invalid" 2 "Reserved" 1 "ON" 0 "OFF" ;
VAL_ 262 STAT_ActiveAmbientLight 3 "Invalid" 2 "Reserved" 1 "ON" 0 "OFF" ;
VAL_ 262 STAT_HeadlightTurnOnReminder 3 "Signal invalid" 2 "Reserved" 1 "On" 0 "Off" ;
VAL_ 262 STAT_HazardWarningLight 3 "Signal invalid" 2 "Reserved" 1 "On" 0 "Off" ;
VAL_ 262 STAT_Emergency_BrakeLight 3 "Signal invalid" 2 "Reserved" 1 "On" 0 "Off" ;
VAL_ 262 RLS_VoltageError 3 "Not used" 2 "High Voltage" 1 "Low Voltage" 0 "Normal" ;
VAL_ 262 STAT_ReadingLight_RL 3 "Invalid" 2 "Reserved" 1 "ON" 0 "OFF" ;
VAL_ 262 STAT_HeadlightReminder 3 "Invalid" 2 "Reserved" 1 "ON" 0 "OFF" ;
VAL_ 262 RLS_RS_FAULT 1 "True" 0 "False" ;
VAL_ 262 RLS_Response_error 1 "True" 0 "False" ;
VAL_ 262 RLS_Rainfall 3 "Heavy Rain" 2 "Moderate Rain" 1 "Light Rain" 0 "No Rain" ;
VAL_ 262 RLS_LiSwitchReason 3 "Tunnel" 2 "Night" 1 "Day" 0 "Darkstart" ;
VAL_ 262 RLS_Humid_Temp_Error 1 "Error" 0 "Normal" ;
VAL_ 262 RLS_COMMFAULT 1 "True" 0 "False" ;
VAL_ 262 RLS_AutoPanel 1 "Panel dim activate" 0 "Panel dim deactivate" ;
VAL_ 262 BCM_BSM_OTM_Right_LED_State 7 "Reserved" 6 "Reserved" 5 "Reserved" 4 "Reserved" 3 "LED Init Run" 2 "LED Blinking" 1 "LED On" 0 "LED Off" ;
VAL_ 262 BCM_BSM_OTM_Left_LED_State 7 "Reserved" 6 "Reserved" 5 "Reserved" 4 "Reserved" 3 "LED Init Run" 2 "LED Blinking" 1 "LED On" 0 "LED Off" ;
VAL_ 262 STAT_LicenceLight 3 "Invalid" 2 "Reserved" 1 "ON" 0 "OFF" ;
VAL_ 262 STAT_WorkingLight 3 "Invalid" 2 "Reserved" 1 "ON" 0 "OFF" ;
VAL_ 262 STAT_LowBeam 3 "Signal invalid" 2 "HW malfunction" 1 "LowBeam ON" 0 "LowBeam OFF" ;
VAL_ 262 STAT_PositionLight 3 "Signal invalid" 2 "ParkingLight ON" 1 "PositionLight ON" 0 "PositionLight OFF" ;
VAL_ 262 STAT_BrakeLight 3 "Signal invalid" 2 "Reserved" 1 "ON" 0 "OFF" ;
VAL_ 262 STAT_LightActivation 7 "Signal invalid" 6 "Reserved" 5 "ParkLight_right" 4 "ParkLight_Left" 3 "AutoLight" 2 "LowBeam" 1 "PositionLight" 0 "OFF" ;
VAL_ 262 STAT_DRL 3 "Signal invalid" 2 "Reserved" 1 "ON" 0 "OFF" ;
VAL_ 262 STAT_TurnIndicators 7 "Signal invalid" 6 "Reserved" 5 "Reserved" 4 "Reserved" 3 "Both turn lamps ON" 2 "Right turn lamp ON" 1 "Left turn lamp ON" 0 "OFF" ;
VAL_ 262 STAT_ReverseLight 3 "Signal invalid" 2 "Reserved" 1 "ON" 0 "OFF" ;
VAL_ 262 STAT_InteriorLight 3 "Signal invalid" 2 "Reserved" 1 "ON" 0 "OFF" ;
VAL_ 262 STAT_FogLampRear 3 "Signal invalid" 2 "Reserved" 1 "ON" 0 "OFF" ;
VAL_ 262 STAT_ADBFunction 3 "Signal invalid" 2 "Reserved" 1 "ADB_ON" 0 "ADB_OFF" ;
VAL_ 262 STAT_HighBeam 3 "Signal invalid" 2 "Reserved" 1 "Highbeam ON" 0 "Highbeam OFF" ;
VAL_ 324 ESC_VehSpdLat_Q 13 "Replacement value" 9 "Reserved" 0 "Initializing" 12 "Replacement value status temp" 11 "Quality limited status temporary" 7 "Reserved" 6 "Reserved" 5 "Valid" 4 "Reserved" 3 "Reserved" 2 "Reserved" 15 "Signal invalid" 14 "Signal invalid status temporary" 10 "Value is valid status temporary" 8 "Reserved" 1 "Reserved" ;
VAL_ 324 ESC_WhlTck_RR_Q 3 "Invalid" 2 "Reserved" 1 "Valid" 0 "Initializing" ;
VAL_ 324 ESC_WhlTck_RL_Q 3 "Invalid" 2 "Reserved" 1 "Valid" 0 "Initializing" ;
VAL_ 324 ESC_WhlTck_FR_Q 3 "Invalid" 2 "Reserved" 1 "Valid" 0 "Initializing" ;
VAL_ 324 ESC_WhlTck_FL_Q 3 "Invalid" 2 "Reserved" 1 "Valid" 0 "Initializing" ;
VAL_ 324 ESC_WhlSpd_RR_Q 0 "Initializing" 3 "Signal invalid" 2 "Replacement value" 1 "Valid" ;
VAL_ 324 ESC_WhlSpd_RL_Q 0 "Initializing" 3 "Signal invalid" 2 "Replacement value" 1 "Valid" ;
VAL_ 324 ESC_WhlSpd_FR_Q 0 "Initializing" 3 "Signal invalid" 2 "Replacement value" 1 "Valid" ;
VAL_ 324 ESC_WhlSpd_FL_Q 1 "Valid" 3 "Signal invalid" 2 "Replacement value" 0 "Initializing" ;
VAL_ 324 ESC_VehDrvCond_Q 3 "Signal invalid" 2 "Reserved" 1 "Valid" 0 "Initializing" ;
VAL_ 324 ESC_DrivDist_Q 3 "Invalid" 2 "Reserved" 1 "Valid" 0 "Initializing" ;
VAL_ 324 ESC_VehDrvCond 3 "Invalid" 2 "Backward" 1 "Forward" 0 "Standstill" ;
VAL_ 324 ESC_VehSpd_Q 0 "Initializing" 3 "Signal invalid" 2 "Quality limited status temp" 1 "Valid" ;
VAL_ 267 STAT_Hitch_TM 3 "Invalid (safety state not set)" 1 "Unlocked (unsafe)" 0 "locked (safe)" ;
VAL_ 267 ST_TRAI 0 "No trailer detected" 1 "Trailer detected" 3 "Signal invalid" ;
VAL_ 267 TrailerInput 3 "Invalid" 2 "Reserved" 1 "Trailer synchronous with HW input" 0 "Trailer synchronous with CAN" ;
VAL_ 267 STAT_HWPosLightInput_TM 3 "Signal invalid" 2 "Reserved" 1 "PosLight input active TRM" 0 "PosLight nput not active TRM" ;
VAL_ 267 STAT_HWIndicatorInput_TM 3 "Signal invalid" 2 "Reserved" 1 "Indicator Input active TRM" 0 "Indicator Input not active TRM" ;
VAL_ 267 STAT_HWBrakeLightInput_TM 3 "Signal invalid" 2 "Reserved" 1 "Brakel Light Input  active TRM" 0 "Brakel Light Input not active TRM" ;
VAL_ 267 VoltageStatus_TM 3 "Invalid" 2 "Undervoltage" 1 "Overvoltage" 0 "No failure" ;
VAL_ 267 STAT_BrakeLight_TM 3 "Signal invalid" 2 "Reserved" 1 "ON" 0 "OFF" ;
VAL_ 267 TrailerSystemError 3 "Invalid" 2 "Reserved" 1 "Error" 0 "No error" ;
VAL_ 267 STAT_TurnIndicators_TM 15 "Signal invalid" 6 "Both turn lamp defect" 5 "Right turn lamp defect" 4 "Left turn lamp defect" 3 "Both turn lamps ON" 2 "Right turn lamp ON" 1 "Left turn lamp ON" 0 "OFF" ;
VAL_ 267 STAT_FogLampRear_TM 3 "Signal invalid" 2 "Failure" 1 "ON" 0 "OFF" ;
VAL_ 267 STAT_PositionLight_TM 3 "Signal invalid" 2 "PositionLight failure" 1 "PositionLight ON" 0 "PositionLight OFF" ;
VAL_ 267 STAT_ReverseLight_TM 3 "Signal invalid" 2 "Failure" 1 "ON" 0 "OFF" ;
VAL_ 171 ST_CRASH_TYPE 12 "reserved / not in use" 11 "reserved / not in use" 10 "reserved / not in use" 9 "reserved / not in use" 8 "mulitple impacts" 7 "rollover" 6 "rear crash severity 2" 5 "rear crash severity 1" 0 "no crash" 1 "front crash severity 1" 2 "front crash severity 2" 3 "side crash severity 1" 4 "side crash severity 2" 13 "reserved / not in use" 14 "init" 15 "invalid" ;
VAL_ 171 ST_CRASH 7 "invalid" 6 "init" 5 "not used / reserved" 0 "No crash" 1 "Crash severity 1" 2 "Crash severity 2" 3 "not used / reserved" 4 "not used / reserved" ;
VAL_ 1015 VolumeDown_SWS 3 "Signal invalid" 2 "Continuous volume decrease" 1 "Volume decrease" 0 "OFF" ;
VAL_ 1015 VolumeUp_SWS 3 "Signal invalid" 2 "Continuous volume increase" 1 "Volume increase" 0 "OFF" ;
VAL_ 1015 OK_button_SWS 3 "Signal invalid" 2 "Long pressed" 1 "Short pressed" 0 "No pressed" ;
VAL_ 1015 TOOT_SWS 3 "Signal invalid" 2 "SWS_toot_long_pressed" 1 "SWS_toot_pressed" 0 "OFF" ;
VAL_ 1018 SET_TowMode 3 "Signal invalid" 2 "No change" 1 "ON" 0 "OFF" ;
VAL_ 1018 SET_InteriorMotionSensing 3 "Signal invalid" 2 "No change" 1 "ON" 0 "OFF" ;
VAL_ 1018 SET_RCP_Button 3 "Signal invalid" 2 "Reserved" 1 "Pressed" 0 "Not pressed" ;
VAL_ 1018 SET_DayTimeRunningLight 3 "Signal invalid" 2 "Reserved" 1 "ON" 0 "OFF" ;
VAL_ 1018 SET_LeavingHomeSetting 3 "60" 2 "40" 1 "20" 0 "OFF" 7 "Signal invalid" 6 "No change" 5 "Reserved" 4 "80" ;
VAL_ 1018 SET_ComingHomeSetting 7 "Signal invalid" 6 "No change" 5 "Reserved" 4 "80" 3 "60" 2 "40" 1 "20" 0 "OFF" ;
VAL_ 1018 SET_ToDefaultFactorySetting 3 "Signal invalid / no change" 2 "Reserved" 1 "ON" 0 "OFF" ;
VAL_ 1018 SET_RemoteLockFeedback 3 "Signal invalid" 2 "Turnindicator + Toot" 1 "Turn indicator" 0 "No Feedback" ;
